VERSION "BASE;119 -- 04.07.2025 -- R3233 -- FDMgenDBC1.0"

NS_ :

BS_:

BU_: CM4

BO_ 2600460568 RTprop2_BASE: 8 CM4
 SG_ rmtTstrBattCurrentOTA_BASE : 0|8@1+ (0.2,0) [0|50] "A" Vector__XXX
 SG_ rmtTstrInstallProgressBar_BASE : 16|8@1+ (1,0) [0|250] "%" Vector__XXX
 SG_ rmtTstrDispCondC1gearNeut_BASE : 24|2@1+ (1,0) [0|0] "-" Vector__XXX
 SG_ rmtTstrDispCondC1VehSpd_BASE : 26|2@1+ (1,0) [0|0] "-" Vector__XXX
 SG_ rmtTstrDispCondC1ParkBrake_BASE : 28|2@1+ (1,0) [0|0] "-" Vector__XXX
 SG_ rmtTstrDispCondC1engSpd_BASE : 30|2@1+ (1,0) [0|0] "-" Vector__XXX
 SG_ rmtTstrDispCondIgnition_BASE : 32|2@1+ (1,0) [0|0] "-" Vector__XXX
 SG_ rmtTstrDispCondOBD_BASE : 34|2@1+ (1,0) [0|0] "-" Vector__XXX
 SG_ rmtTstrDispICLreset_BASE : 36|2@1+ (1,0) [0|0] "-" Vector__XXX
 SG_ rmtTstrDispUpdateAvail_BASE : 38|2@1+ (1,0) [0|0] "-" Vector__XXX
 SG_ rmtTstrInstallNumOfJobs_BASE : 40|8@1+ (1,0) [0|250] "-" Vector__XXX
 SG_ rmtTstrInstallTxtUpdToggle_BASE : 48|2@1+ (1,0) [0|1] "-" Vector__XXX
 SG_ rmtTstrDispCondEPTO_BASE : 50|2@1+ (1,0) [0|0] "-" Vector__XXX
 SG_ rmtTstrDispCond24VBattChrg_BASE : 52|2@1+ (1,0) [0|0] "-" Vector__XXX
 SG_ rmtTstrDispCondSecCerts_BASE : 54|2@1+ (1,0) [0|0] "-" Vector__XXX
 SG_ rmtTstrDispCondCurrent_BASE : 56|2@1+ (1,0) [0|0] "-" Vector__XXX
 SG_ rmtTstrDispAllowDriverExit_BASE : 58|2@1+ (1,0) [0|0] "-" Vector__XXX
 SG_ rmtTstrDispCondExtrnlChrg_BASE : 60|2@1+ (1,0) [0|0] "-" Vector__XXX
 SG_ rmtTstrOverrideCl15_BASE : 62|2@1+ (1,0) [0|0] "-" Vector__XXX
 SG_ rmtTstrInstallEstTotTime_VAR1 : 8|8@1+ (5,0) [0|1250] "min" Vector__XXX

BO_ 2566834939 DM1_CM4_SAE: 42 CM4
 SG_ protectLampStatus_CM4_SAE : 0|2@1+ (1,0) [0|0] "-" Vector__XXX
 SG_ flashAmberWarningLamp_CM4_SAE : 10|2@1+ (1,0) [0|0] "-" Vector__XXX
 SG_ SPN_high_reserved03_CM4_SAE : 101|3@1+ (1,0) [0|7] "-" Vector__XXX
 SG_ OcC_03_CM4_SAE : 104|7@1+ (1,0) [0|127] "-" Vector__XXX
 SG_ CM_03_CM4_SAE : 111|1@1+ (1,0) [0|1] "-" Vector__XXX
 SG_ SPN_04_CM4_SAE : 112|16@1+ (1,0) [0|65535] "-" Vector__XXX
 SG_ flashRedStopLamp_CM4_SAE : 12|2@1+ (1,0) [0|0] "-" Vector__XXX
 SG_ FMI_04_CM4_SAE : 128|5@1+ (1,0) [0|31] "-" Vector__XXX
 SG_ SPN_high_reserved04_CM4_SAE : 133|3@1+ (1,0) [0|7] "-" Vector__XXX
 SG_ OcC_04_CM4_SAE : 136|7@1+ (1,0) [0|127] "-" Vector__XXX
 SG_ flashMalFunctionalIndicatorLamp_ : 14|2@1+ (1,0) [0|0] "-" Vector__XXX
 SG_ CM_04_CM4_SAE : 143|1@1+ (1,0) [0|1] "-" Vector__XXX
 SG_ SPN_05_CM4_SAE : 144|16@1+ (1,0) [0|65535] "-" Vector__XXX
 SG_ SPN_01_CM4_SAE : 16|16@1+ (1,0) [0|65535] "-" Vector__XXX
 SG_ FMI_05_CM4_SAE : 160|5@1+ (1,0) [0|31] "-" Vector__XXX
 SG_ SPN_high_reserved05_CM4_SAE : 165|3@1+ (1,0) [0|7] "-" Vector__XXX
 SG_ OcC_05_CM4_SAE : 168|7@1+ (1,0) [0|127] "-" Vector__XXX
 SG_ CM_05_CM4_SAE : 175|1@1+ (1,0) [0|1] "-" Vector__XXX
 SG_ SPN_06_CM4_SAE : 176|16@1+ (1,0) [0|65535] "-" Vector__XXX
 SG_ FMI_06_CM4_SAE : 192|5@1+ (1,0) [0|31] "-" Vector__XXX
 SG_ SPN_high_reserved06_CM4_SAE : 197|3@1+ (1,0) [0|7] "-" Vector__XXX
 SG_ amberWarningLamp_CM4_SAE : 2|2@1+ (1,0) [0|0] "-" Vector__XXX
 SG_ OcC_06_CM4_SAE : 200|7@1+ (1,0) [0|127] "-" Vector__XXX
 SG_ CM_06_CM4_SAE : 207|1@1+ (1,0) [0|1] "-" Vector__XXX
 SG_ SPN_07_CM4_SAE : 208|16@1+ (1,0) [0|65535] "-" Vector__XXX
 SG_ FMI_07_CM4_SAE : 224|5@1+ (1,0) [0|31] "-" Vector__XXX
 SG_ SPN_high_reserved07_CM4_SAE : 229|3@1+ (1,0) [0|7] "-" Vector__XXX
 SG_ OcC_07_CM4_SAE : 232|7@1+ (1,0) [0|127] "-" Vector__XXX
 SG_ CM_07_CM4_SAE : 239|1@1+ (1,0) [0|1] "-" Vector__XXX
 SG_ SPN_08_CM4_SAE : 240|16@1+ (1,0) [0|65535] "-" Vector__XXX
 SG_ FMI_08_CM4_SAE : 256|5@1+ (1,0) [0|31] "-" Vector__XXX
 SG_ SPN_high_reserved08_CM4_SAE : 261|3@1+ (1,0) [0|7] "-" Vector__XXX
 SG_ OcC_08_CM4_SAE : 264|7@1+ (1,0) [0|127] "-" Vector__XXX
 SG_ CM_08_CM4_SAE : 271|1@1+ (1,0) [0|1] "-" Vector__XXX
 SG_ SPN_09_CM4_SAE : 272|16@1+ (1,0) [0|65535] "-" Vector__XXX
 SG_ FMI_09_CM4_SAE : 288|5@1+ (1,0) [0|31] "-" Vector__XXX
 SG_ SPN_high_reserved09_CM4_SAE : 293|3@1+ (1,0) [0|7] "-" Vector__XXX
 SG_ OcC_09_CM4_SAE : 296|7@1+ (1,0) [0|127] "-" Vector__XXX
 SG_ CM_09_CM4_SAE : 303|1@1+ (1,0) [0|1] "-" Vector__XXX
 SG_ SPN_10_CM4_SAE : 304|16@1+ (1,0) [0|65535] "-" Vector__XXX
 SG_ FMI_01_CM4_SAE : 32|5@1+ (1,0) [0|31] "-" Vector__XXX
 SG_ FMI_10_CM4_SAE : 320|5@1+ (1,0) [0|31] "-" Vector__XXX
 SG_ SPN_high_reserved10_CM4_SAE : 325|3@1+ (1,0) [0|7] "-" Vector__XXX
 SG_ OcC_10_CM4_SAE : 328|7@1+ (1,0) [0|127] "-" Vector__XXX
 SG_ CM_10_CM4_SAE : 335|1@1+ (1,0) [0|1] "-" Vector__XXX
 SG_ SPN_high_reserved01_CM4_SAE : 37|3@1+ (1,0) [0|7] "-" Vector__XXX
 SG_ redStopLamp_CM4_SAE : 4|2@1+ (1,0) [0|0] "-" Vector__XXX
 SG_ OcC_01_CM4_SAE : 40|7@1+ (1,0) [0|127] "-" Vector__XXX
 SG_ CM_01_CM4_SAE : 47|1@1+ (1,0) [0|1] "-" Vector__XXX
 SG_ SPN_02_CM4_SAE : 48|16@1+ (1,0) [0|65535] "-" Vector__XXX
 SG_ malfunctionIndicatorLamp_CM4_SAE : 6|2@1+ (1,0) [0|0] "-" Vector__XXX
 SG_ FMI_02_CM4_SAE : 64|5@1+ (1,0) [0|31] "-" Vector__XXX
 SG_ SPN_high_reserved02_CM4_SAE : 69|3@1+ (1,0) [0|7] "-" Vector__XXX
 SG_ OcC_02_CM4_SAE : 72|7@1+ (1,0) [0|127] "-" Vector__XXX
 SG_ CM_02_CM4_SAE : 79|1@1+ (1,0) [0|1] "-" Vector__XXX
 SG_ flashProtectLampStatus_CM4_SAE : 8|2@1+ (1,0) [0|0] "-" Vector__XXX
 SG_ SPN_03_CM4_SAE : 80|16@1+ (1,0) [0|65535] "-" Vector__XXX
 SG_ FMI_03_CM4_SAE : 96|5@1+ (1,0) [0|31] "-" Vector__XXX

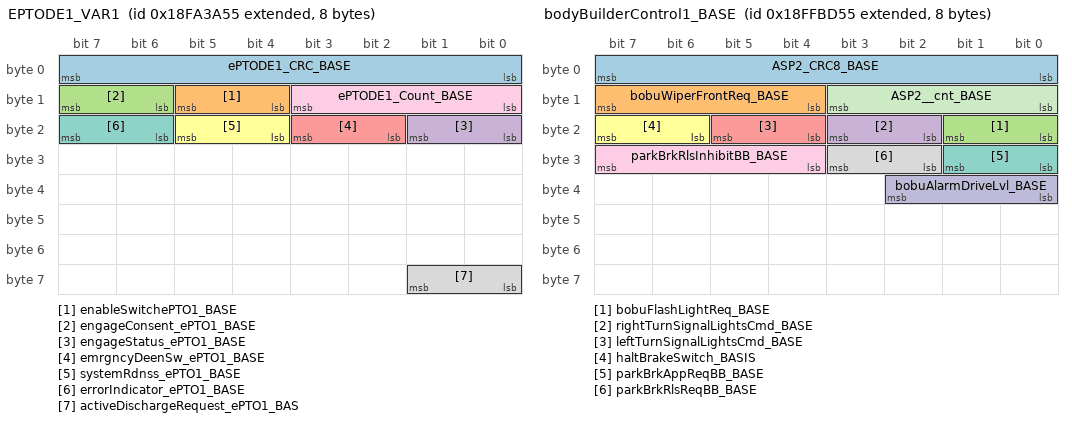
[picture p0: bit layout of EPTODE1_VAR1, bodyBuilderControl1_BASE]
BO_ 2566535765 EPTODE1_VAR1: 8 CM4
 SG_ ePTODE1_CRC_BASE : 0|8@1+ (1,0) [0|255] "count" Vector__XXX
 SG_ enableSwitchePTO1_BASE : 12|2@1+ (1,0) [0|0] "-" Vector__XXX
 SG_ engageConsent_ePTO1_BASE : 14|2@1+ (1,0) [0|0] "-" Vector__XXX
 SG_ engageStatus_ePTO1_BASE : 16|2@1+ (1,0) [0|0] "-" Vector__XXX
 SG_ emrgncyDeenSw_ePTO1_BASE : 18|2@1+ (1,0) [0|0] "-" Vector__XXX
 SG_ systemRdnss_ePTO1_BASE : 20|2@1+ (1,0) [0|0] "-" Vector__XXX
 SG_ errorIndicator_ePTO1_BASE : 22|2@1+ (1,0) [0|0] "-" Vector__XXX
 SG_ activeDischargeRequest_ePTO1_BAS : 56|2@1+ (1,0) [0|0] "-" Vector__XXX
 SG_ ePTODE1_Count_BASE : 8|4@1+ (1,0) [0|15] "-" Vector__XXX

BO_ 2566896981 bodyBuilderControl1_BASE: 8 CM4
 SG_ ASP2_CRC8_BASE : 0|8@1+ (1,0) [0|255] "-" Vector__XXX
 SG_ bobuWiperFrontReq_BASE : 12|4@1+ (1,0) [0|0] "-" Vector__XXX
 SG_ bobuFlashLightReq_BASE : 16|2@1+ (1,0) [0|0] "-" Vector__XXX
 SG_ rightTurnSignalLightsCmd_BASE : 18|2@1+ (1,0) [0|0] "-" Vector__XXX
 SG_ leftTurnSignalLightsCmd_BASE : 20|2@1+ (1,0) [0|0] "-" Vector__XXX
 SG_ haltBrakeSwitch_BASIS : 22|2@1+ (1,0) [0|0] "-" Vector__XXX
 SG_ parkBrkAppReqBB_BASE : 24|2@1+ (1,0) [0|0] "-" Vector__XXX
 SG_ parkBrkRlsReqBB_BASE : 26|2@1+ (1,0) [0|0] "-" Vector__XXX
 SG_ parkBrkRlsInhibitBB_BASE : 28|4@1+ (1,0) [0|0] "-" Vector__XXX
 SG_ bobuAlarmDriveLvl_BASE : 32|3@1+ (1,0) [0|0] "-" Vector__XXX
 SG_ ASP2__cnt_BASE : 8|4@1+ (1,0) [0|15] "-" Vector__XXX

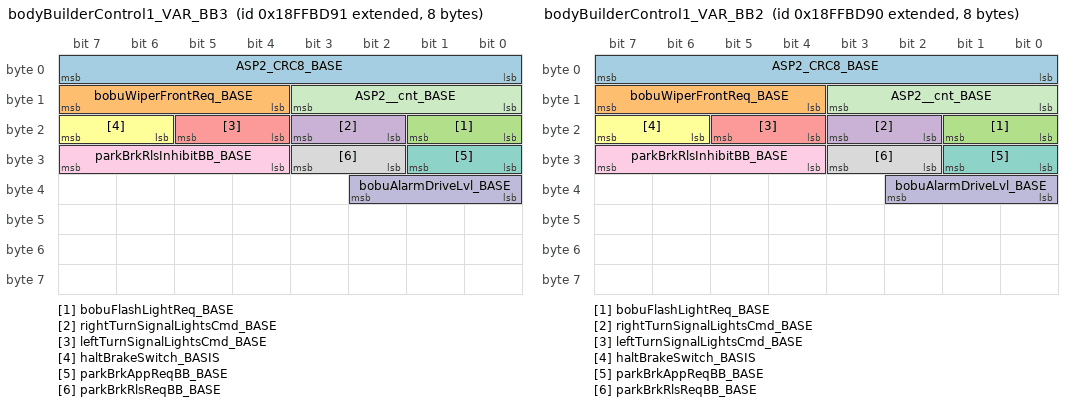
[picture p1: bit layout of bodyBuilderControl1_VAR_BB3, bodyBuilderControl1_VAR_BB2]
BO_ 2566897041 bodyBuilderControl1_VAR_BB3: 8 CM4
 SG_ ASP2_CRC8_BASE : 0|8@1+ (1,0) [0|255] "-" Vector__XXX
 SG_ bobuWiperFrontReq_BASE : 12|4@1+ (1,0) [0|0] "-" Vector__XXX
 SG_ bobuFlashLightReq_BASE : 16|2@1+ (1,0) [0|0] "-" Vector__XXX
 SG_ rightTurnSignalLightsCmd_BASE : 18|2@1+ (1,0) [0|0] "-" Vector__XXX
 SG_ leftTurnSignalLightsCmd_BASE : 20|2@1+ (1,0) [0|0] "-" Vector__XXX
 SG_ haltBrakeSwitch_BASIS : 22|2@1+ (1,0) [0|0] "-" Vector__XXX
 SG_ parkBrkAppReqBB_BASE : 24|2@1+ (1,0) [0|0] "-" Vector__XXX
 SG_ parkBrkRlsReqBB_BASE : 26|2@1+ (1,0) [0|0] "-" Vector__XXX
 SG_ parkBrkRlsInhibitBB_BASE : 28|4@1+ (1,0) [0|0] "-" Vector__XXX
 SG_ bobuAlarmDriveLvl_BASE : 32|3@1+ (1,0) [0|0] "-" Vector__XXX
 SG_ ASP2__cnt_BASE : 8|4@1+ (1,0) [0|15] "-" Vector__XXX

BO_ 2566897040 bodyBuilderControl1_VAR_BB2: 8 CM4
 SG_ ASP2_CRC8_BASE : 0|8@1+ (1,0) [0|255] "-" Vector__XXX
 SG_ bobuWiperFrontReq_BASE : 12|4@1+ (1,0) [0|0] "-" Vector__XXX
 SG_ bobuFlashLightReq_BASE : 16|2@1+ (1,0) [0|0] "-" Vector__XXX
 SG_ rightTurnSignalLightsCmd_BASE : 18|2@1+ (1,0) [0|0] "-" Vector__XXX
 SG_ leftTurnSignalLightsCmd_BASE : 20|2@1+ (1,0) [0|0] "-" Vector__XXX
 SG_ haltBrakeSwitch_BASIS : 22|2@1+ (1,0) [0|0] "-" Vector__XXX
 SG_ parkBrkAppReqBB_BASE : 24|2@1+ (1,0) [0|0] "-" Vector__XXX
 SG_ parkBrkRlsReqBB_BASE : 26|2@1+ (1,0) [0|0] "-" Vector__XXX
 SG_ parkBrkRlsInhibitBB_BASE : 28|4@1+ (1,0) [0|0] "-" Vector__XXX
 SG_ bobuAlarmDriveLvl_BASE : 32|3@1+ (1,0) [0|0] "-" Vector__XXX
 SG_ ASP2__cnt_BASE : 8|4@1+ (1,0) [0|15] "-" Vector__XXX

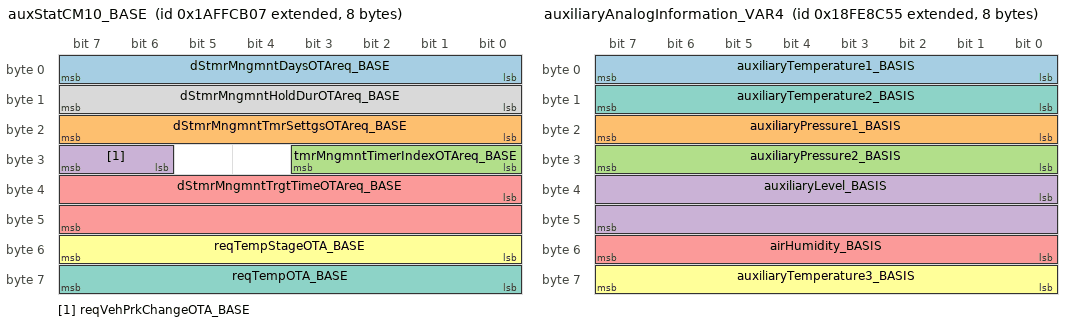
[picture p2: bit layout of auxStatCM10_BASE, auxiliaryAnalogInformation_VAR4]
BO_ 2600454919 auxStatCM10_BASE: 8 CM4
 SG_ dStmrMngmntDaysOTAreq_BASE : 0|8@1+ (1,0) [0|127] "-" Vector__XXX
 SG_ dStmrMngmntTmrSettgsOTAreq_BASE : 16|8@1+ (1,0) [0|127] "-" Vector__XXX
 SG_ tmrMngmntTimerIndexOTAreq_BASE : 24|4@1+ (1,0) [0|0] "-" Vector__XXX
 SG_ reqVehPrkChangeOTA_BASE : 30|2@1+ (1,0) [0|0] "-" Vector__XXX
 SG_ dStmrMngmntTrgtTimeOTAreq_BASE : 32|16@1+ (1,0) [0|64255] "min" Vector__XXX
 SG_ reqTempStageOTA_BASE : 48|8@1+ (1,1) [1|9] "-" Vector__XXX
 SG_ reqTempOTA_BASE : 56|8@1+ (0.5,0) [0|125] "°C" Vector__XXX
 SG_ dStmrMngmntHoldDurOTAreq_BASE : 8|8@1+ (15,0) [0|3750] "min" Vector__XXX

BO_ 2566818901 auxiliaryAnalogInformation_VAR4: 8 CM4
 SG_ auxiliaryTemperature1_BASIS : 0|8@1+ (1,-40) [-40|210] "°C" Vector__XXX
 SG_ auxiliaryPressure1_BASIS : 16|8@1+ (16,0) [0|4000] "kPa" Vector__XXX
 SG_ auxiliaryPressure2_BASIS : 24|8@1+ (16,0) [0|4000] "kPa" Vector__XXX
 SG_ auxiliaryLevel_BASIS : 32|16@1+ (0.1,0) [0|6425.5] "mm" Vector__XXX
 SG_ airHumidity_BASIS : 48|8@1+ (0.4,0) [0|100] "%" Vector__XXX
 SG_ auxiliaryTemperature3_BASIS : 56|8@1+ (1,-40) [-40|210] "°C" Vector__XXX
 SG_ auxiliaryTemperature2_BASIS : 8|8@1+ (1,-40) [-40|210] "°C" Vector__XXX

BO_ 2600454922 auxStatCM13_BASE: 8 CM4
 SG_ auxStatCM13placeholder_BASE : 0|8@1+ (1,0) [0|255] "-" Vector__XXX

BO_ 2566845696 ambientConditions_BASIS: 8 Vector__XXX
 SG_ barometricPressure_BASIS : 0|8@1+ (0.5,0) [0|125] "kPa" CM4
 SG_ ambientAirTemperature_BASIS : 24|16@1+ (0.03125,-273) [-273|1734.96875] "°C" CM4
 SG_ cabInteriorTemperature_BASIS : 8|16@1+ (0.03125,-273) [-273|1734.96875] "°C" CM4

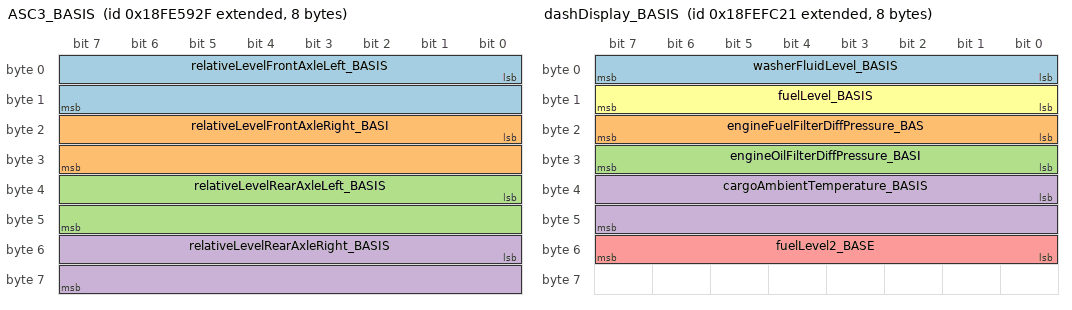
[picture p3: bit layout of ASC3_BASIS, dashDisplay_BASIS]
BO_ 2566805807 ASC3_BASIS: 8 Vector__XXX
 SG_ relativeLevelFrontAxleLeft_BASIS : 0|16@1+ (0.1,-3200) [-3200|3225.5] "mm" CM4
 SG_ relativeLevelFrontAxleRight_BASI : 16|16@1+ (0.1,-3200) [-3200|3225.5] "mm" CM4
 SG_ relativeLevelRearAxleLeft_BASIS : 32|16@1+ (0.1,-3200) [-3200|3225.5] "mm" CM4
 SG_ relativeLevelRearAxleRight_BASIS : 48|16@1+ (0.1,-3200) [-3200|3225.5] "mm" CM4

BO_ 2566838781 auxStatKSM1_BASIS: 8 Vector__XXX
 SG_ Kuehlwassertemperaturwarnung_BAS : 0|2@1+ (1,0) [0|0] "-" CM4
 SG_ Oeldruckwarnung_BASIS : 2|2@1+ (1,0) [0|0] "-" CM4

BO_ 2563833623 cabIllumination_BASIS: 8 Vector__XXX
 SG_ illuminationBrightness_BASIS : 0|8@1+ (0.4,0) [0|100] "%" CM4

BO_ 2566843687 cruiseControlVehicleSpeedSetup_V: 8 Vector__XXX
 SG_ maximumVehicleSpeedLimit_BASIS : 0|8@1+ (1,0) [0|250] "km/h" CM4
 SG_ CClowSetLimitSpeed_BASIS : 16|8@1+ (1,0) [0|250] "km/h" CM4
 SG_ CChighSetLimitSpeed_BASIS : 8|8@1+ (1,0) [0|250] "km/h" CM4

BO_ 2566847521 dashDisplay_BASIS: 8 Vector__XXX
 SG_ washerFluidLevel_BASIS : 0|8@1+ (0.4,0) [0|100] "%" CM4
 SG_ engineFuelFilterDiffPressure_BAS : 16|8@1+ (2,0) [0|500] "kPa" CM4
 SG_ engineOilFilterDiffPressure_BASI : 24|8@1+ (0.5,0) [0|125] "kPa" CM4
 SG_ cargoAmbientTemperature_BASIS : 32|16@1+ (0.03125,-273) [-273|1735] "°C" CM4
 SG_ fuelLevel2_BASE : 48|8@1+ (0.4,0) [0|100] "%" CM4
 SG_ fuelLevel_BASIS : 8|8@1+ (0.4,0) [0|100] "%" CM4

BO_ 2566759916 doorControl2_BASIS: 8 Vector__XXX
 SG_ lockStatusOfDoor1_BASIS : 0|2@1+ (1,0) [0|0] "-" CM4
 SG_ enableStatusOfDoor2_BASIS : 10|2@1+ (1,0) [0|0] "-" CM4
 SG_ lockStatusOfDoor3_BASIS : 12|2@1+ (1,0) [0|0] "-" CM4
 SG_ openStatusOfDoor3_BASIS : 14|2@1+ (1,0) [0|0] "-" CM4
 SG_ enableStatusOfDoor3_BASIS : 16|2@1+ (1,0) [0|0] "-" CM4
 SG_ lockStatusOfDoor4_BASIS : 18|2@1+ (1,0) [0|0] "-" CM4
 SG_ openStatusOfDoor1_BASIS : 2|2@1+ (1,0) [0|0] "-" CM4
 SG_ openStatusOfDoor4_BASIS : 20|2@1+ (1,0) [0|0] "-" CM4
 SG_ enableStatusOfDoor4_BASIS : 22|2@1+ (1,0) [0|0] "-" CM4
 SG_ lockStatusOfDoor5_BASIS : 24|2@1+ (1,0) [0|0] "-" CM4
 SG_ openStatusOfDoor5_BASIS : 26|2@1+ (1,0) [0|0] "-" CM4
 SG_ enableStatusOfDoor5_BASIS : 28|2@1+ (1,0) [0|0] "-" CM4
 SG_ lockStatusOfDoor6_BASIS : 30|2@1+ (1,0) [0|0] "-" CM4
 SG_ openStatusOfDoor6_BASIS : 32|2@1+ (1,0) [0|0] "-" CM4
 SG_ enableStatusOfDoor6_BASIS : 34|2@1+ (1,0) [0|0] "-" CM4
 SG_ lockStatusOfDoor7_BASIS : 36|2@1+ (1,0) [0|0] "-" CM4
 SG_ openStatusOfDoor7_BASIS : 38|2@1+ (1,0) [0|0] "-" CM4
 SG_ enableStatusOfDoor1_BASIS : 4|2@1+ (1,0) [0|0] "-" CM4
 SG_ enableStatusOfDoor7_BASIS : 40|2@1+ (1,0) [0|0] "-" CM4
 SG_ lockStatusOfDoor8_BASIS : 42|2@1+ (1,0) [0|0] "-" CM4
 SG_ openStatusOfDoor8_BASIS : 44|2@1+ (1,0) [0|0] "-" CM4
 SG_ enableStatusOfDoor8_BASIS : 46|2@1+ (1,0) [0|0] "-" CM4
 SG_ lockStatusOfDoor9_BASIS : 48|2@1+ (1,0) [0|0] "-" CM4
 SG_ openStatusOfDoor9_BASIS : 50|2@1+ (1,0) [0|0] "-" CM4
 SG_ enableStatusOfDoor9_BASIS : 52|2@1+ (1,0) [0|0] "-" CM4
 SG_ lockStatusOfDoor10_BASIS : 54|2@1+ (1,0) [0|0] "-" CM4
 SG_ openStatusOfDoor10_BASIS : 56|2@1+ (1,0) [0|0] "-" CM4
 SG_ enableStatusOfDoor10_BASIS : 58|2@1+ (1,0) [0|0] "-" CM4
 SG_ lockStatusOfDoor2_BASIS : 6|2@1+ (1,0) [0|0] "-" CM4
 SG_ openStatusOfDoor2_BASIS : 8|2@1+ (1,0) [0|0] "-" CM4

BO_ 2566810606 driversIdentification_VAR3: 40 Vector__XXX
 SG_ driverIdentification_BASE : 0|320@1+ (1,0) [0|0] "-" CM4

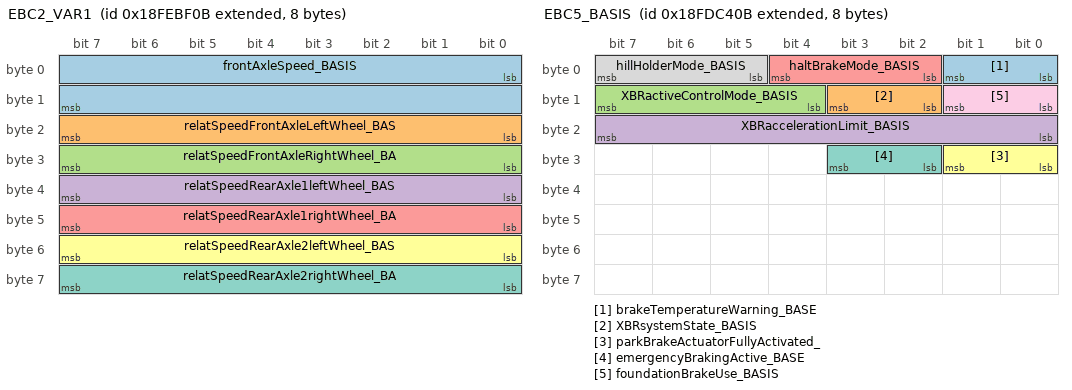
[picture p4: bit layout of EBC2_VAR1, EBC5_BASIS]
BO_ 2566831883 EBC2_VAR1: 8 Vector__XXX
 SG_ frontAxleSpeed_BASIS : 0|16@1+ (0.00390625,0) [0|250.996] "km/h" CM4
 SG_ relatSpeedFrontAxleLeftWheel_BAS : 16|8@1+ (0.0625,-7.8125) [-7.8125|7.8125] "km/h" CM4
 SG_ relatSpeedFrontAxleRightWheel_BA : 24|8@1+ (0.0625,-7.8125) [-7.8125|7.8125] "km/h" CM4
 SG_ relatSpeedRearAxle1leftWheel_BAS : 32|8@1+ (0.0625,-7.8125) [-7.8125|7.8125] "km/h" CM4
 SG_ relatSpeedRearAxle1rightWheel_BA : 40|8@1+ (0.0625,-7.8125) [-7.8125|7.8125] "km/h" CM4
 SG_ relatSpeedRearAxle2leftWheel_BAS : 48|8@1+ (0.0625,-7.8125) [-7.8125|7.8125] "km/h" CM4
 SG_ relatSpeedRearAxle2rightWheel_BA : 56|8@1+ (0.0625,-7.8125) [-7.8125|7.8125] "km/h" CM4

BO_ 2566767627 EBC5_BASIS: 8 Vector__XXX
 SG_ brakeTemperatureWarning_BASE : 0|2@1+ (1,0) [0|0] "-" CM4
 SG_ XBRsystemState_BASIS : 10|2@1+ (1,0) [0|0] "-" CM4
 SG_ XBRactiveControlMode_BASIS : 12|4@1+ (1,0) [0|0] "-" CM4
 SG_ XBRaccelerationLimit_BASIS : 16|8@1+ (0.1,-12.5) [-12.5|12.5] "m/s²" CM4
 SG_ haltBrakeMode_BASIS : 2|3@1+ (1,0) [0|0] "-" CM4
 SG_ parkBrakeActuatorFullyActivated_ : 24|2@1+ (1,0) [0|0] "-" CM4
 SG_ emergencyBrakingActive_BASE : 26|2@1+ (1,0) [0|0] "-" CM4
 SG_ hillHolderMode_BASIS : 5|3@1+ (1,0) [0|0] "-" CM4
 SG_ foundationBrakeUse_BASIS : 8|2@1+ (1,0) [0|0] "-" CM4

BO_ 2566833352 EBS22_T1_TO_TRUCK: 8 Vector__XXX
 SG_ vehicleABSactivePassive_T1_TO_TR : 0|2@1+ (1,0) [0|0] "-" CM4
 SG_ redWarningSignalRequest_T1_TO_TR : 10|2@1+ (1,0) [0|0] "-" CM4
 SG_ amberWarningSignalRequest_T1_TO_ : 12|2@1+ (1,0) [0|0] "-" CM4
 SG_ electricalSupplyOfNonBrakingSyst : 14|2@1+ (1,0) [0|0] "-" CM4
 SG_ springBrakeInstalled_T1_TO_TRUCK : 16|2@1+ (1,0) [0|0] "-" CM4
 SG_ electrLoadProportionalFunc_T1_TO : 18|2@1+ (1,0) [0|0] "-" CM4
 SG_ vehicleRetContrActivePassive_T1_ : 2|2@1+ (1,0) [0|0] "-" CM4
 SG_ vehicleType_T1_TO_TRUCK_EBS22 : 20|2@1+ (1,0) [0|0] "-" CM4
 SG_ springBrakeEngaged_T1_TO_TRUCK : 22|2@1+ (1,0) [0|0] "-" CM4
 SG_ loadingRampApproachAssistance_T1 : 24|2@1+ (1,0) [0|0] "-" CM4
 SG_ supplylineBrakingRequest_T1_TO_T : 26|2@1+ (1,0) [0|0] "-" CM4
 SG_ stopLampsRequest_BASE : 28|2@1+ (1,0) [0|0] "-" CM4
 SG_ electricCtrlLineBrkngSuprt_BASE : 30|2@1+ (1,0) [0|0] "-" CM4
 SG_ axleLoadSum_T1_TO_TRUCK : 32|16@1+ (2,0) [0|128510] "kg" CM4
 SG_ vehicleServiceBrakeActPass_T1_TO : 4|2@1+ (1,0) [0|0] "-" CM4
 SG_ referenceRetarderTorque_T1_TO_TR : 48|16@1+ (1,0) [0|64255] "Nm" CM4
 SG_ automaticTowedVehicleBrake_T1_TO : 6|2@1+ (1,0) [0|0] "-" CM4
 SG_ vehicleElectricalSupply_T1_TO_TR : 8|2@1+ (1,0) [0|0] "-" CM4

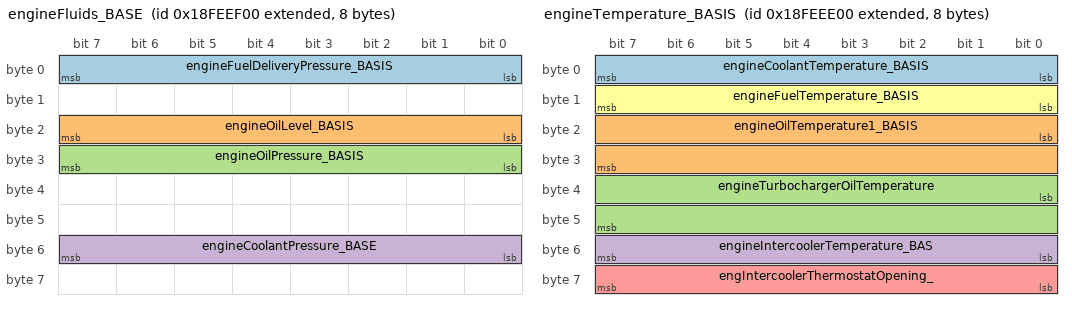
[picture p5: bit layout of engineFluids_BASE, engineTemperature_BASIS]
BO_ 2566844160 engineFluids_BASE: 8 Vector__XXX
 SG_ engineFuelDeliveryPressure_BASIS : 0|8@1+ (4,0) [0|1000] "kPa" CM4
 SG_ engineOilLevel_BASIS : 16|8@1+ (0.4,0) [0|100] "%" CM4
 SG_ engineOilPressure_BASIS : 24|8@1+ (4,0) [0|1000] "kPa" CM4
 SG_ engineCoolantPressure_BASE : 48|8@1+ (2,0) [0|500] "kPa" CM4

BO_ 2566841639 engineHoursRevolutions_VAR1: 8 Vector__XXX
 SG_ engineTotalHoursOfOperation_BASI : 0|32@1+ (0.05,0) [0|210554060.75] "h" CM4
 SG_ engineTotalRevolutions_BASIS : 32|32@1+ (1000,0) [0|4211081215000] "r" CM4

BO_ 2566843904 engineTemperature_BASIS: 8 Vector__XXX
 SG_ engineCoolantTemperature_BASIS : 0|8@1+ (1,-40) [-40|210] "°C" CM4
 SG_ engineOilTemperature1_BASIS : 16|16@1+ (0.03125,-273) [-273|1734.96875] "°C" CM4
 SG_ engineTurbochargerOilTemperature : 32|16@1+ (0.03125,-273) [-273|1734.96875] "°C" CM4
 SG_ engineIntercoolerTemperature_BAS : 48|8@1+ (1,-40) [-40|210] "°C" CM4
 SG_ engIntercoolerThermostatOpening_ : 56|8@1+ (0.4,0) [0|100] "%" CM4
 SG_ engineFuelTemperature_BASIS : 8|8@1+ (1,-40) [-40|210] "°C" CM4

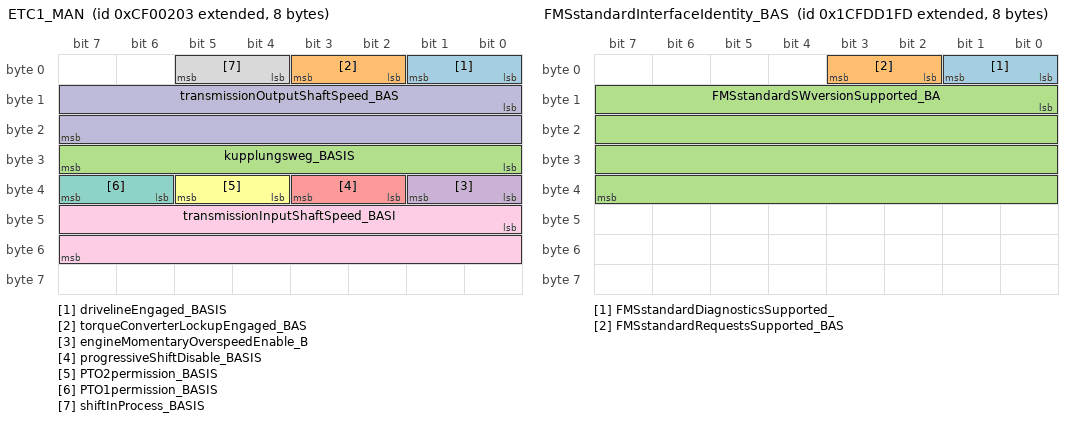
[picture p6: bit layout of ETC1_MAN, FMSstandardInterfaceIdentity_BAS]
BO_ 2364539395 ETC1_MAN: 8 Vector__XXX
 SG_ drivelineEngaged_BASIS : 0|2@1+ (1,0) [0|0] "-" CM4
 SG_ torqueConverterLockupEngaged_BAS : 2|2@1+ (1,0) [0|0] "-" CM4
 SG_ kupplungsweg_BASIS : 24|8@1+ (0.4,0) [0|100] "%" CM4
 SG_ engineMomentaryOverspeedEnable_B : 32|2@1+ (1,0) [0|0] "-" CM4
 SG_ progressiveShiftDisable_BASIS : 34|2@1+ (1,0) [0|0] "-" CM4
 SG_ PTO2permission_BASIS : 36|2@1+ (1,0) [0|0] "-" CM4
 SG_ PTO1permission_BASIS : 38|2@1+ (1,0) [0|0] "-" CM4
 SG_ shiftInProcess_BASIS : 4|2@1+ (1,0) [0|0] "-" CM4
 SG_ transmissionInputShaftSpeed_BASI : 40|16@1+ (0.125,0) [0|8031.875] "rpm" CM4
 SG_ transmissionOutputShaftSpeed_BAS : 8|16@1+ (0.125,0) [0|8031.875] "rpm" CM4

BO_ 2633880061 FMSstandardInterfaceIdentity_BAS: 8 Vector__XXX
 SG_ FMSstandardDiagnosticsSupported_ : 0|2@1+ (1,0) [0|0] "-" CM4
 SG_ FMSstandardRequestsSupported_BAS : 2|2@1+ (1,0) [0|0] "-" CM4
 SG_ FMSstandardSWversionSupported_BA : 8|32@1+ (1,0) [0|255] "-" CM4

BO_ 2566842663 fuelConsumption_VAR3: 8 Vector__XXX
 SG_ engineTripFuel_BASIS : 0|32@1+ (0.5,0) [0|2105540607.5] "l" CM4
 SG_ engineTotalFuelUsed_BASIS : 32|32@1+ (0.5,0) [0|2105540607.5] "l" CM4

BO_ 2566719744 highResolutionFuelConsumption_BA: 8 Vector__XXX
 SG_ highResolutionEngineTripFuel_BAS : 0|32@1+ (0.001,0) [0|4211081.2149999998509883881] "l" CM4
 SG_ HRengineTotalFuelUsed_BASE : 32|32@1+ (0.001,0) [0|4211081.2149999998509883881] "l" CM4

BO_ 2566844967 fuelEconomy_BASIS: 8 Vector__XXX
 SG_ engineFuelRate_BASIS : 0|16@1+ (0.05,0) [0|3212.75] "l/h" CM4
 SG_ engineInstantaneousFuelEconomy_B : 16|16@1+ (0.001953,0) [0|125.490015] "km/l" CM4
 SG_ engineAverageFuelEconomy_BASIS : 32|16@1+ (0.001953,0) [0|125.490015] "km/l" CM4

BO_ 2365443111 operatorsExtLightControlsMessage: 8 Vector__XXX
 SG_ turnSignalSwitch_BASE : 8|4@1+ (1,0) [0|0] "-" CM4

BO_ 2566805053 tankInformation1_BASIS: 8 Vector__XXX
 SG_ catalystTankLevel_BASIS : 0|8@1+ (0.4,0) [0|100] "%" CM4
 SG_ temperatureReagentInTank_BASIS : 8|8@1+ (1,-40) [-40|210] "°C" CM4

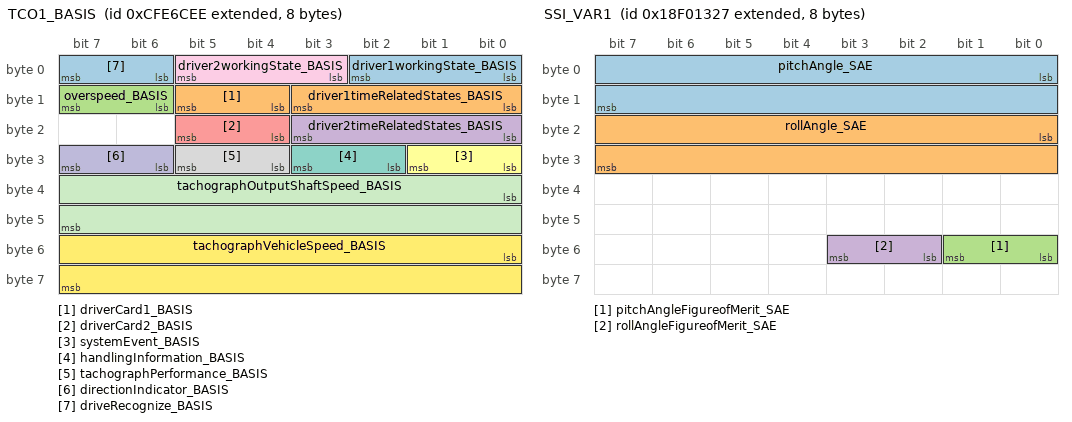
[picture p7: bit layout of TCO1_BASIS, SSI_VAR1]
BO_ 2365484270 TCO1_BASIS: 8 Vector__XXX
 SG_ driver1workingState_BASIS : 0|3@1+ (1,0) [0|0] "-" CM4
 SG_ driverCard1_BASIS : 12|2@1+ (1,0) [0|0] "-" CM4
 SG_ overspeed_BASIS : 14|2@1+ (1,0) [0|0] "-" CM4
 SG_ driver2timeRelatedStates_BASIS : 16|4@1+ (1,0) [0|0] "-" CM4
 SG_ driverCard2_BASIS : 20|2@1+ (1,0) [0|0] "-" CM4
 SG_ systemEvent_BASIS : 24|2@1+ (1,0) [0|0] "-" CM4
 SG_ handlingInformation_BASIS : 26|2@1+ (1,0) [0|0] "-" CM4
 SG_ tachographPerformance_BASIS : 28|2@1+ (1,0) [0|0] "-" CM4
 SG_ driver2workingState_BASIS : 3|3@1+ (1,0) [0|0] "-" CM4
 SG_ directionIndicator_BASIS : 30|2@1+ (1,0) [0|0] "-" CM4
 SG_ tachographOutputShaftSpeed_BASIS : 32|16@1+ (0.125,0) [0|8031.875] "rpm" CM4
 SG_ tachographVehicleSpeed_BASIS : 48|16@1+ (0.00390625,0) [0|250.996] "km/h" CM4
 SG_ driveRecognize_BASIS : 6|2@1+ (1,0) [0|0] "-" CM4
 SG_ driver1timeRelatedStates_BASIS : 8|4@1+ (1,0) [0|0] "-" CM4

BO_ 2566802471 militaryLightingCommand_BASE: 8 Vector__XXX
 SG_ OprtrsBlackOutIntnstySel_BASE : 56|8@1+ (0.4,0) [0|100] "%" CM4

BO_ 2566806728 RGE22_T1_TO_TRUCK: 8 Vector__XXX
 SG_ tyreWheelIdentification_BASIS : 32|8@1+ (1,0) [0|0] "-" CM4
 SG_ axleLoad_BASE : 40|16@1+ (0.5,0) [0|32127.5] "kg" CM4

BO_ 2565870375 SSI_VAR1: 8 Vector__XXX
 SG_ pitchAngle_SAE : 0|16@1+ (0.002,-64) [-64|64.51] "°" CM4
 SG_ rollAngle_SAE : 16|16@1+ (0.002,-64) [-64|64.51] "°" CM4
 SG_ pitchAngleFigureofMerit_SAE : 48|2@1+ (1,0) [0|0] "-" CM4
 SG_ rollAngleFigureofMerit_SAE : 50|2@1+ (1,0) [0|0] "-" CM4

BO_ 2566846467 transmissionFluids_TCU: 8 Vector__XXX
 SG_ transmissionOilTemperature_TCU : 32|16@1+ (0.03125,-273) [-273|1735] "°C" CM4
 SG_ transmissionOilLevel_TCU : 8|8@1+ (0.4,0) [0|100] "%" CM4

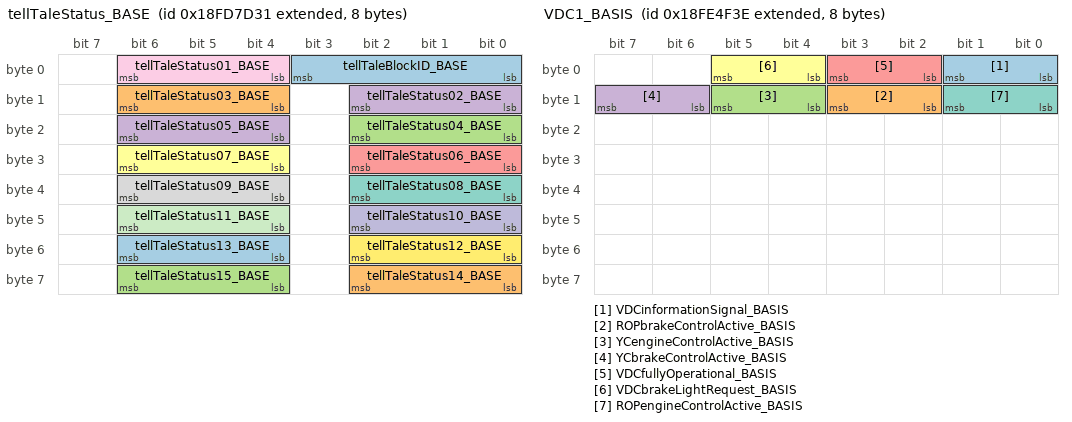
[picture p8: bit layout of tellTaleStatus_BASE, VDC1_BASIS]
BO_ 2566749489 tellTaleStatus_BASE: 8 Vector__XXX
 SG_ tellTaleBlockID_BASE : 0|4@1+ (1,0) [0|15] "-" CM4
 SG_ tellTaleStatus03_BASE : 12|3@1+ (1,0) [0|0] "-" CM4
 SG_ tellTaleStatus04_BASE : 16|3@1+ (1,0) [0|0] "-" CM4
 SG_ tellTaleStatus05_BASE : 20|3@1+ (1,0) [0|0] "-" CM4
 SG_ tellTaleStatus06_BASE : 24|3@1+ (1,0) [0|0] "-" CM4
 SG_ tellTaleStatus07_BASE : 28|3@1+ (1,0) [0|0] "-" CM4
 SG_ tellTaleStatus08_BASE : 32|3@1+ (1,0) [0|0] "-" CM4
 SG_ tellTaleStatus09_BASE : 36|3@1+ (1,0) [0|0] "-" CM4
 SG_ tellTaleStatus01_BASE : 4|3@1+ (1,0) [0|0] "-" CM4
 SG_ tellTaleStatus10_BASE : 40|3@1+ (1,0) [0|0] "-" CM4
 SG_ tellTaleStatus11_BASE : 44|3@1+ (1,0) [0|0] "-" CM4
 SG_ tellTaleStatus12_BASE : 48|3@1+ (1,0) [0|0] "-" CM4
 SG_ tellTaleStatus13_BASE : 52|3@1+ (1,0) [0|0] "-" CM4
 SG_ tellTaleStatus14_BASE : 56|3@1+ (1,0) [0|0] "-" CM4
 SG_ tellTaleStatus15_BASE : 60|3@1+ (1,0) [0|0] "-" CM4
 SG_ tellTaleStatus02_BASE : 8|3@1+ (1,0) [0|0] "-" CM4

BO_ 2566803262 VDC1_BASIS: 8 Vector__XXX
 SG_ VDCinformationSignal_BASIS : 0|2@1+ (1,0) [0|0] "-" CM4
 SG_ ROPbrakeControlActive_BASIS : 10|2@1+ (1,0) [0|0] "-" CM4
 SG_ YCengineControlActive_BASIS : 12|2@1+ (1,0) [0|0] "-" CM4
 SG_ YCbrakeControlActive_BASIS : 14|2@1+ (1,0) [0|0] "-" CM4
 SG_ VDCfullyOperational_BASIS : 2|2@1+ (1,0) [0|0] "-" CM4
 SG_ VDCbrakeLightRequest_BASIS : 4|2@1+ (1,0) [0|0] "-" CM4
 SG_ ROPengineControlActive_BASIS : 8|2@1+ (1,0) [0|0] "-" CM4

BO_ 2566613799 HVBI_BASE: 8 Vector__XXX
 SG_ highVtgBusEPTOAvlblty_BASE : 12|4@1+ (1,0) [0|0] "-" CM4

BO_ 2365346087 ASC7_BASE: 8 Vector__XXX
 SG_ liftAxle1Status_BASE : 0|3@1+ (1,0) [0|0] "-" CM4

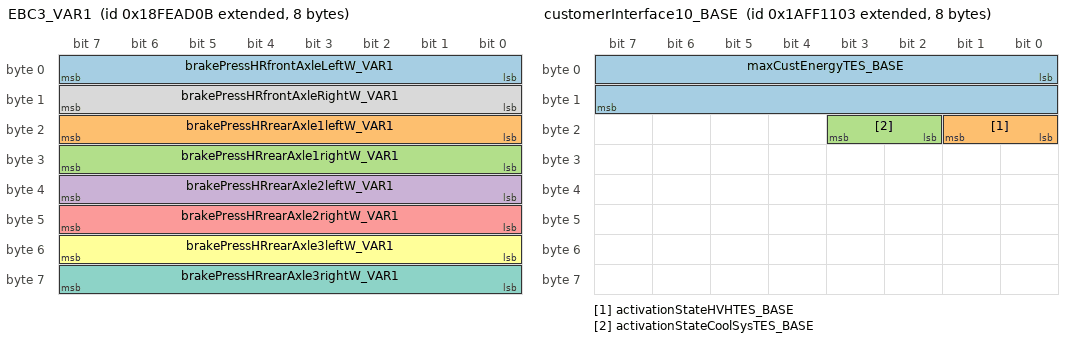
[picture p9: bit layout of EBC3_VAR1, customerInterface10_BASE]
BO_ 2566827275 EBC3_VAR1: 8 Vector__XXX
 SG_ brakePressHRfrontAxleLeftW_VAR1 : 0|8@1+ (5,0) [0|1250] "kPa" CM4
 SG_ brakePressHRrearAxle1leftW_VAR1 : 16|8@1+ (5,0) [0|1250] "kPa" CM4
 SG_ brakePressHRrearAxle1rightW_VAR1 : 24|8@1+ (5,0) [0|1250] "kPa" CM4
 SG_ brakePressHRrearAxle2leftW_VAR1 : 32|8@1+ (5,0) [0|1250] "kPa" CM4
 SG_ brakePressHRrearAxle2rightW_VAR1 : 40|8@1+ (5,0) [0|1250] "kPa" CM4
 SG_ brakePressHRrearAxle3leftW_VAR1 : 48|8@1+ (5,0) [0|1250] "kPa" CM4
 SG_ brakePressHRrearAxle3rightW_VAR1 : 56|8@1+ (5,0) [0|1250] "kPa" CM4
 SG_ brakePressHRfrontAxleRightW_VAR1 : 8|8@1+ (5,0) [0|1250] "kPa" CM4

BO_ 2566767143 EEC14_BASE: 8 Vector__XXX
 SG_ fuelType_BASE : 48|8@1+ (1,0) [0|0] "-" CM4

BO_ 2364641930 HVESP1D2_BASE: 8 Vector__XXX
 SG_ HVESP1fastUpdateSOC_BASE : 0|16@1+ (0.0015625,0) [0|100.3984375] "%" CM4
 SG_ HVESP1HighestCellVoltage_BASE : 16|16@1+ (0.001,0) [0|64.255] "V" CM4
 SG_ HVESP1lowestCellVoltage_BASE : 32|16@1+ (0.001,0) [0|64.255] "V" CM4

BO_ 2364645770 HVESP2D2_BASE: 8 Vector__XXX
 SG_ HVESP2fastUpdateSOC_BASE : 0|16@1+ (0.0015625,0) [0|100.3984375] "%" CM4
 SG_ HVESP2HighestCellVoltage_BASE : 16|16@1+ (0.001,0) [0|64.255] "V" CM4
 SG_ HVESP2lowestCellVoltage_BASE : 32|16@1+ (0.001,0) [0|64.255] "V" CM4

BO_ 2364649610 HVESP3D2_BASE: 8 Vector__XXX
 SG_ HVESP3fastUpdateSOC_BASE : 0|16@1+ (0.0015625,0) [0|100.3984375] "%" CM4
 SG_ HVESP3HighestCellVoltage_BASE : 16|16@1+ (0.001,0) [0|64.255] "V" CM4
 SG_ HVESP3lowestCellVoltage_BASE : 32|16@1+ (0.001,0) [0|64.255] "V" CM4

BO_ 2364657290 HVESP5D2_BASE: 8 Vector__XXX
 SG_ HVESP5fastUpdateSOC_BASE : 0|16@1+ (0.0015625,0) [0|100.3984375] "%" CM4
 SG_ HVESP5HighestCellVoltage_BASE : 16|16@1+ (0.001,0) [0|64.255] "V" CM4
 SG_ HVESP5lowestCellVoltage_BASE : 32|16@1+ (0.001,0) [0|64.255] "V" CM4

BO_ 2364675722 HVESP7D2_BASE: 8 Vector__XXX
 SG_ HVESP7fastUpdateSOC_BASE : 0|16@1+ (0.0015625,0) [0|100.3984375] "%" CM4
 SG_ HVESP7HighestCellVoltage_BASE : 16|16@1+ (0.001,0) [0|64.255] "V" CM4
 SG_ HVESP7lowestCellVoltage_BASE : 32|16@1+ (0.001,0) [0|64.255] "V" CM4

BO_ 2364653450 HVESP4D2_BASE: 8 Vector__XXX
 SG_ HVESP4fastUpdateSOC_BASE : 0|16@1+ (0.0015625,0) [0|100.3984375] "%" CM4
 SG_ HVESP4HighestCellVoltage_BASE : 16|16@1+ (0.001,0) [0|64.255] "V" CM4
 SG_ HVESP4lowestCellVoltage_BASE : 32|16@1+ (0.001,0) [0|64.255] "V" CM4

BO_ 2364679562 HVESP8D2_BASE: 8 Vector__XXX
 SG_ HVESP8fastUpdateSOC_BASE : 0|16@1+ (0.0015625,0) [0|100.3984375] "%" CM4
 SG_ HVESP8HighestCellVoltage_BASE : 16|16@1+ (0.001,0) [0|64.255] "V" CM4
 SG_ HVESP8lowestCellVoltage_BASE : 32|16@1+ (0.001,0) [0|64.255] "V" CM4

BO_ 2364661130 HVESP6D2_BASE: 8 Vector__XXX
 SG_ HVESP6fastUpdateSOC_BASE : 0|16@1+ (0.0015625,0) [0|100.3984375] "%" CM4
 SG_ HVESP6HighestCellVoltage_BASE : 16|16@1+ (0.001,0) [0|64.255] "V" CM4
 SG_ HVESP6lowestCellVoltage_BASE : 32|16@1+ (0.001,0) [0|64.255] "V" CM4

BO_ 2566840592 retarderConfiguration_RD: 19 Vector__XXX
 SG_ retarderType_RD : 0|4@1+ (1,0) [0|0] "-" CM4
 SG_ percentTorqueAtPoint4_RD : 104|8@1+ (1,-125) [-125|125] "%" CM4
 SG_ retarderSpeedAtPeakTorqPoint5_RD : 112|16@1+ (0.125,0) [0|8031.875] "rpm" CM4
 SG_ referenceRetarderTorque_RD : 128|16@1+ (1,0) [0|64255] "Nm" CM4
 SG_ percentTorqAtPeakTorqPoint5_RD : 144|8@1+ (1,-125) [-125|125] "%" CM4
 SG_ retarderSpeedAtIdlePoint1_RD : 16|16@1+ (0.125,0) [0|8031.875] "rpm" CM4
 SG_ percentTorqueAtIdlePoint1_RD : 32|8@1+ (1,-125) [-125|125] "%" CM4
 SG_ retarderLocation_RD : 4|4@1+ (1,0) [0|0] "-" CM4
 SG_ maximumRetarderSpeedPoint2_RD : 40|16@1+ (0.125,0) [0|8031.875] "rpm" CM4
 SG_ percentTorqueAtMaxSpeedPoint2_RD : 56|8@1+ (1,-125) [-125|125] "%" CM4
 SG_ retarderSpeedAtPoint3_RD : 64|16@1+ (0.125,0) [0|8031.875] "rpm" CM4
 SG_ retarderControlMethod_RD : 8|8@1+ (1,0) [0|250] "step" CM4
 SG_ percentTorqueAtPoint3_RD : 80|8@1+ (1,-125) [-125|125] "%" CM4
 SG_ retarderSpeedAtPoint4_RD : 88|16@1+ (0.125,0) [0|8031.875] "rpm" CM4

BO_ 2566847248 retarderFluids_RD: 8 Vector__XXX
 SG_ drivelineRetOverheatIndicator_RD : 16|2@1+ (1,0) [0|0] "-" CM4
 SG_ hydraulicOilTemperature_RD : 8|8@1+ (1,-40) [-40|210] "°C" CM4

BO_ 2566698791 VEP4_BASE: 8 Vector__XXX
 SG_ hybridBatPackRemCharge_BASE : 0|16@1+ (0.0025,0) [0|160.6375] "%" CM4

BO_ 2566545546 EVDCCIP_BASE: 8 Vector__XXX
 SG_ EVfullChargeTimeRemaining_BASE : 32|16@1+ (10,0) [0|642550] "s" CM4

BO_ 2600407299 customerInterface10_BASE: 8 Vector__XXX
 SG_ maxCustEnergyTES_BASE : 0|16@1+ (0.05,0) [0|3212.75] "kWh" CM4
 SG_ activationStateHVHTES_BASE : 16|2@1+ (1,0) [0|0] "-" CM4
 SG_ activationStateCoolSysTES_BASE : 18|2@1+ (1,0) [0|0] "-" CM4

BO_ 2600407300 customerInterface11_BASE: 8 Vector__XXX
 SG_ totalEnergyConsumption_BASE : 0|32@1+ (1,0) [0|4211081215] "kWh" CM4
 SG_ HVESSintakeCoolantTemp_BASE : 32|8@1+ (1,-40) [-40|210] "°C" CM4
 SG_ drvSysActv_BASE : 40|2@1+ (1,0) [0|0] "-" CM4

BO_ 2600407297 customerInterface8_BASE: 8 Vector__XXX
 SG_ HVESSstateOfHealth_BASE : 0|8@1+ (0.4,0) [0|100] "%" CM4
 SG_ HVESSmaxPackSOC_BASE : 24|16@1+ (0.0015625,0) [0|100.3984375] "%" CM4
 SG_ HVESSminPackSOC_BASE : 8|16@1+ (0.0015625,0) [0|100.3984375] "%" CM4

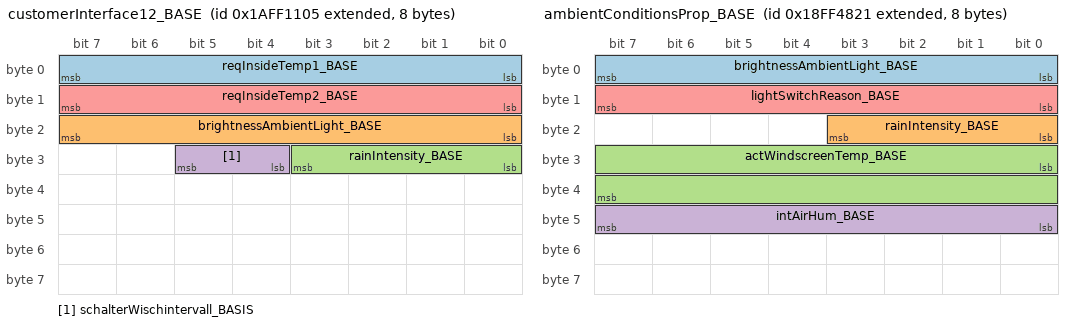
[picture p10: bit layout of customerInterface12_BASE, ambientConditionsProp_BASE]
BO_ 2600407301 customerInterface12_BASE: 8 Vector__XXX
 SG_ reqInsideTemp1_BASE : 0|8@1+ (0.33,-30) [-30|52.5] "°C" CM4
 SG_ brightnessAmbientLight_BASE : 16|8@1+ (100,0) [0|25000] "lx" CM4
 SG_ rainIntensity_BASE : 24|4@1+ (1,0) [0|0] "-" CM4
 SG_ schalterWischintervall_BASIS : 28|2@1+ (1,0) [0|0] "-" CM4
 SG_ reqInsideTemp2_BASE : 8|8@1+ (0.33,-30) [-30|52.5] "°C" CM4

BO_ 2565903754 HVESSD6_BASE: 8 Vector__XXX
 SG_ HVESSintakeCoolantTemp_BASE : 32|8@1+ (1,-40) [-40|210] "°C" CM4
 SG_ HVESStemperature_BASE : 56|8@1+ (1,-40) [-40|210] "°C" CM4

BO_ 2566866977 ambientConditionsProp_BASE: 8 Vector__XXX
 SG_ brightnessAmbientLight_BASE : 0|8@1+ (100,0) [0|25000] "lx" CM4
 SG_ rainIntensity_BASE : 16|4@1+ (1,0) [0|0] "-" CM4
 SG_ actWindscreenTemp_BASE : 24|16@1+ (0.03125,-273) [-273|1734.96875] "°C" CM4
 SG_ intAirHum_BASE : 40|8@1+ (0.4,0) [0|100] "%" CM4
 SG_ lightSwitchReason_BASE : 8|8@1+ (1,0) [0|0] "-" CM4

BO_ 2566771850 CM3_BASE: 8 Vector__XXX
 SG_ oprtnKeySwIgnPow_BASE : 20|2@1+ (1,0) [0|0] "-" CM4

BO_ 2364610442 DCDC1S2_BASE: 8 Vector__XXX
 SG_ lowSidePowerDCDC_BASE : 0|16@1+ (0.05,-1600) [-1600|1612.75] "kW" CM4

BO_ 2364579978 HVESSD7_BASE: 8 Vector__XXX
 SG_ HVESSdischgEnCpcty_BASE : 0|24@1+ (0.001,0) [0|16449.535] "kWh" CM4

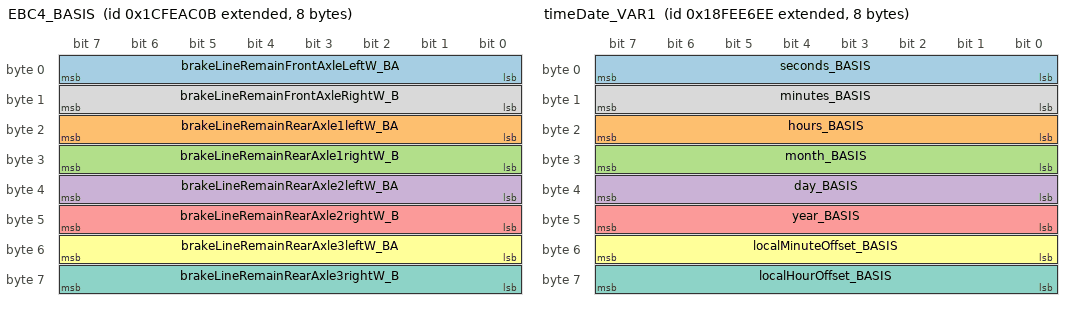
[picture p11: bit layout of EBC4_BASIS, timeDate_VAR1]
BO_ 2633935883 EBC4_BASIS: 8 Vector__XXX
 SG_ brakeLineRemainFrontAxleLeftW_BA : 0|8@1+ (0.4,0) [0|100] "%" CM4
 SG_ brakeLineRemainRearAxle1leftW_BA : 16|8@1+ (0.4,0) [0|100] "%" CM4
 SG_ brakeLineRemainRearAxle1rightW_B : 24|8@1+ (0.4,0) [0|100] "%" CM4
 SG_ brakeLineRemainRearAxle2leftW_BA : 32|8@1+ (0.4,0) [0|100] "%" CM4
 SG_ brakeLineRemainRearAxle2rightW_B : 40|8@1+ (0.4,0) [0|100] "%" CM4
 SG_ brakeLineRemainRearAxle3leftW_BA : 48|8@1+ (0.4,0) [0|100] "%" CM4
 SG_ brakeLineRemainRearAxle3rightW_B : 56|8@1+ (0.4,0) [0|100] "%" CM4
 SG_ brakeLineRemainFrontAxleRightW_B : 8|8@1+ (0.4,0) [0|100] "%" CM4

BO_ 2566842094 timeDate_VAR1: 8 Vector__XXX
 SG_ seconds_BASIS : 0|8@1+ (0.25,0) [0|62.5] "s" CM4
 SG_ hours_BASIS : 16|8@1+ (1,0) [0|250] "h" CM4
 SG_ month_BASIS : 24|8@1+ (1,0) [0|250] "month" CM4
 SG_ day_BASIS : 32|8@1+ (0.25,0) [0|62.5] "day" CM4
 SG_ year_BASIS : 40|8@1+ (1,1985) [1985|2235] "year" CM4
 SG_ localMinuteOffset_BASIS : 48|8@1+ (1,-125) [-125|125] "min" CM4
 SG_ localHourOffset_BASIS : 56|8@1+ (1,-125) [-125|125] "h" CM4
 SG_ minutes_BASIS : 8|8@1+ (1,0) [0|250] "min" CM4

BO_ 2583638092 appControlInterface_VAR1: 8 Vector__XXX
 SG_ appFrameworkAppID_BASE : 0|16@1+ (1,0) [0|64255] "-" CM4
 SG_ appFrameworkAppState_BASE : 16|8@1+ (1,0) [0|0] "-" CM4

BO_ 2564488174 UDSresp_DTCO2TBM: 8 Vector__XXX
 SG_ UDSresp_DTCO2TBM : 0|8@1+ (1,0) [0|255] "-" CM4

BO_ 2564430062 UDSresp_DTCO2CM4: 8 Vector__XXX
 SG_ UDSresp_DTCO2CM4 : 0|8@1+ (1,0) [0|255] "-" CM4

BO_ 2600422183 CVM_13_BASE: 8 Vector__XXX
 SG_ frceAirflushActive_BASE : 0|2@1+ (1,0) [0|0] "-" CM4
 SG_ actPrkHtrProgData_BASE : 10|2@1+ (1,0) [0|0] "-" CM4
 SG_ reqSilentMode_BASE : 12|2@1+ (1,0) [0|0] "-" CM4
 SG_ washerPumpFront_BASE : 14|2@1+ (1,0) [0|0] "-" CM4
 SG_ eco24VshutOffReq_BASE : 16|2@1+ (1,0) [0|0] "-" CM4
 SG_ mainSwitchShutOffInfo_BASE : 18|2@1+ (1,0) [0|0] "-" CM4
 SG_ actForceReqAC_BASE : 2|2@1+ (1,0) [0|0] "-" CM4
 SG_ infoEmgcyShutOff_BASE : 20|2@1+ (1,0) [0|0] "-" CM4
 SG_ revGearHVAC_BASE : 22|2@1+ (1,0) [0|0] "-" CM4
 SG_ eco24VpwrSaveReq_BASE : 24|8@1+ (1,0) [0|0] "-" CM4
 SG_ egyModeHVAC_BASE : 32|8@1+ (1,0) [0|0] "-" CM4
 SG_ prkHtrEnabled_BASE : 4|2@1+ (1,0) [0|0] "-" CM4
 SG_ tempReduceCorrect_BASE : 40|8@1+ (0.1,0) [0|10] "°C" CM4
 SG_ drvSysOff_BASE : 48|2@1+ (1,0) [0|0] "-" CM4
 SG_ wiperMotorFrontStep1_BASE : 50|2@1+ (1,0) [0|0] "-" CM4
 SG_ wiperMotorFrontStep2_BASE : 52|2@1+ (1,0) [0|0] "-" CM4
 SG_ stopStartActvnState_BASE : 54|2@1+ (1,0) [0|0] "-" CM4
 SG_ CVM13cntE2E_BASE : 56|4@1+ (1,0) [0|15] "-" CM4
 SG_ windscreenHeatingDisp_BASE : 6|2@1+ (1,0) [0|0] "-" CM4
 SG_ CVM13chkE2E_BASE : 60|4@1+ (1,0) [0|15] "-" CM4
 SG_ reqElManual_BASE : 8|2@1+ (1,0) [0|0] "-" CM4

BO_ 2600460311 RTinst1_BASE: 8 Vector__XXX
 SG_ rmtTstrInstallMsgHeaderReq_BASE : 0|16@1+ (1,0) [0|0] "-" CM4
 SG_ rmtTstrInstallJobIdReq_BASE : 16|8@1+ (1,0) [0|250] "-" CM4
 SG_ rmtTstrInstallListIdxReq_BASE : 24|8@1+ (1,0) [0|250] "-" CM4

BO_ 2600462375 LCprop2_BASE: 8 Vector__XXX
 SG_ selectedLanguage_BASE : 48|8@1+ (1,0) [0|0] "-" CM4

BO_ 2364547840 A1SCRdosingSysInfo1_VAR2: 8 Vector__XXX
 SG_ A1SCRactDosingUreaQuantity_BASE : 0|16@1+ (0.3,0) [0|19276.5] "g/h" CM4

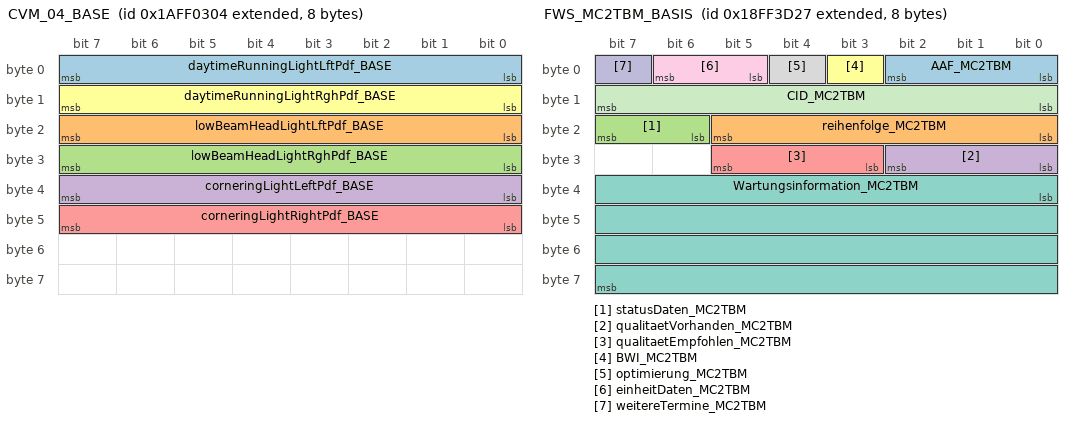
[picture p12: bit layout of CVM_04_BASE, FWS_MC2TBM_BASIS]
BO_ 2600403716 CVM_04_BASE: 8 Vector__XXX
 SG_ daytimeRunningLightLftPdf_BASE : 0|8@1+ (0.4,0) [0|100] "%" CM4
 SG_ lowBeamHeadLightLftPdf_BASE : 16|8@1+ (0.4,0) [0|100] "%" CM4
 SG_ lowBeamHeadLightRghPdf_BASE : 24|8@1+ (0.4,0) [0|100] "%" CM4
 SG_ corneringLightLeftPdf_BASE : 32|8@1+ (0.4,0) [0|100] "%" CM4
 SG_ corneringLightRightPdf_BASE : 40|8@1+ (0.4,0) [0|100] "%" CM4
 SG_ daytimeRunningLightRghPdf_BASE : 8|8@1+ (0.4,0) [0|100] "%" CM4

BO_ 2566832622 highResolutionVehicleDistance_BA: 8 Vector__XXX
 SG_ highResolutionTotalVehDistance_B : 0|32@1+ (0.005,0) [0|21055406] "km" CM4
 SG_ highResolutionTripDistance_BASIS : 32|32@1+ (0.005,0) [0|21055406] "km" CM4

BO_ 2566864167 FWS_MC2TBM_BASIS: 8 Vector__XXX
 SG_ AAF_MC2TBM : 0|3@1+ (1,0) [0|0] "-" CM4
 SG_ reihenfolge_MC2TBM : 16|6@1+ (1,0) [0|0] "-" CM4
 SG_ statusDaten_MC2TBM : 22|2@1+ (1,0) [0|0] "-" CM4
 SG_ qualitaetVorhanden_MC2TBM : 24|3@1+ (1,0) [0|0] "-" CM4
 SG_ qualitaetEmpfohlen_MC2TBM : 27|3@1+ (1,0) [0|0] "-" CM4
 SG_ BWI_MC2TBM : 3|1@1+ (1,0) [0|0] "-" CM4
 SG_ Wartungsinformation_MC2TBM : 32|32@1+ (1,0) [0|4294967295] "-" CM4
 SG_ optimierung_MC2TBM : 4|1@1+ (1,0) [0|0] "-" CM4
 SG_ einheitDaten_MC2TBM : 5|2@1+ (1,0) [0|0] "-" CM4
 SG_ weitereTermine_MC2TBM : 7|1@1+ (1,0) [0|0] "-" CM4
 SG_ CID_MC2TBM : 8|8@1+ (1,0) [0|255] "-" CM4

BO_ 2364642442 HVESP1D4_BASE: 8 Vector__XXX
 SG_ HVESP1dischargeCapacity_BASE : 0|16@1+ (0.01,0) [0|642.55] "Ah" CM4

BO_ 2364646282 HVESP2D4_BASE: 8 Vector__XXX
 SG_ HVESP2dischargeCapacity_BASE : 0|16@1+ (0.01,0) [0|642.55] "Ah" CM4

BO_ 2364650122 HVESP3D4_BASE: 8 Vector__XXX
 SG_ HVESP3dischargeCapacity_BASE : 0|16@1+ (0.01,0) [0|642.55] "Ah" CM4

BO_ 2364661642 HVESP6D4_BASE: 8 Vector__XXX
 SG_ HVESP6dischargeCapacity_BASE : 0|16@1+ (0.01,0) [0|642.55] "Ah" CM4

BO_ 2364653962 HVESP4D4_BASE: 8 Vector__XXX
 SG_ HVESP4dischargeCapacity_BASE : 0|16@1+ (0.01,0) [0|642.55] "Ah" CM4

BO_ 2364657802 HVESP5D4_BASE: 8 Vector__XXX
 SG_ HVESP5dischargeCapacity_BASE : 0|16@1+ (0.01,0) [0|642.55] "Ah" CM4

BO_ 2364676234 HVESP7D4_BASE: 8 Vector__XXX
 SG_ HVESP7dischargeCapacity_BASE : 0|16@1+ (0.01,0) [0|642.55] "Ah" CM4

BO_ 2364680074 HVESP8D4_BASE: 8 Vector__XXX
 SG_ HVESP8dischargeCapacity_BASE : 0|16@1+ (0.01,0) [0|642.55] "Ah" CM4

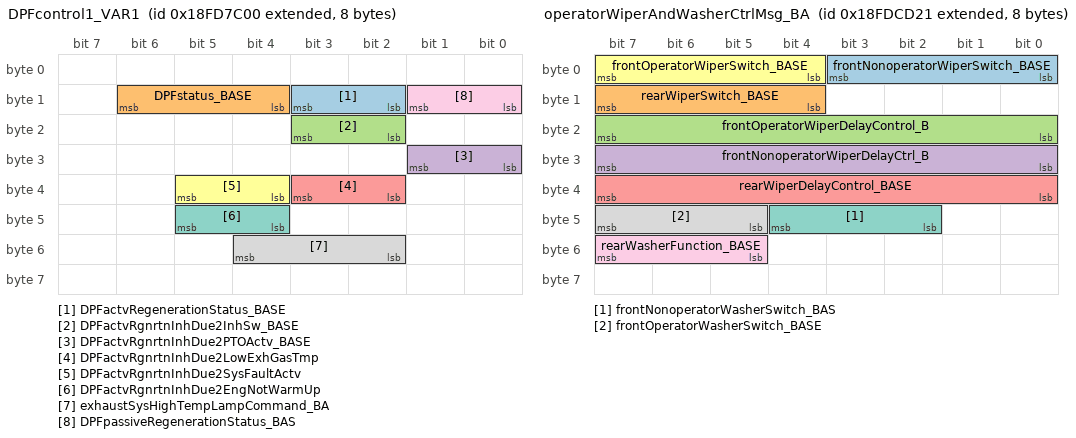
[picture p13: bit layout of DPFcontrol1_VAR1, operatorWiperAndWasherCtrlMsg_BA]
BO_ 2566749184 DPFcontrol1_VAR1: 8 Vector__XXX
 SG_ DPFactvRegenerationStatus_BASE : 10|2@1+ (1,0) [0|0] "-" CM4
 SG_ DPFstatus_BASE : 12|3@1+ (1,0) [0|0] "-" CM4
 SG_ DPFactvRgnrtnInhDue2InhSw_BASE : 18|2@1+ (1,0) [0|0] "-" CM4
 SG_ DPFactvRgnrtnInhDue2PTOActv_BASE : 24|2@1+ (1,0) [0|0] "-" CM4
 SG_ DPFactvRgnrtnInhDue2LowExhGasTmp : 34|2@1+ (1,0) [0|0] "-" CM4
 SG_ DPFactvRgnrtnInhDue2SysFaultActv : 36|2@1+ (1,0) [0|0] "-" CM4
 SG_ DPFactvRgnrtnInhDue2EngNotWarmUp : 44|2@1+ (1,0) [0|0] "-" CM4
 SG_ exhaustSysHighTempLampCommand_BA : 50|3@1+ (1,0) [0|0] "-" CM4
 SG_ DPFpassiveRegenerationStatus_BAS : 8|2@1+ (1,0) [0|0] "-" CM4

BO_ 2566769953 operatorWiperAndWasherCtrlMsg_BA: 8 Vector__XXX
 SG_ frontNonoperatorWiperSwitch_BASE : 0|4@1+ (1,0) [0|0] "-" CM4
 SG_ rearWiperSwitch_BASE : 12|4@1+ (1,0) [0|0] "-" CM4
 SG_ frontOperatorWiperDelayControl_B : 16|8@1+ (0.4,0) [0|100] "%" CM4
 SG_ frontNonoperatorWiperDelayCtrl_B : 24|8@1+ (0.4,0) [0|100] "%" CM4
 SG_ rearWiperDelayControl_BASE : 32|8@1+ (0.4,0) [0|100] "%" CM4
 SG_ frontOperatorWiperSwitch_BASE : 4|4@1+ (1,0) [0|0] "-" CM4
 SG_ frontNonoperatorWasherSwitch_BAS : 42|3@1+ (1,0) [0|0] "-" CM4
 SG_ frontOperatorWasherSwitch_BASE : 45|3@1+ (1,0) [0|0] "-" CM4
 SG_ rearWasherFunction_BASE : 53|3@1+ (1,0) [0|0] "-" CM4

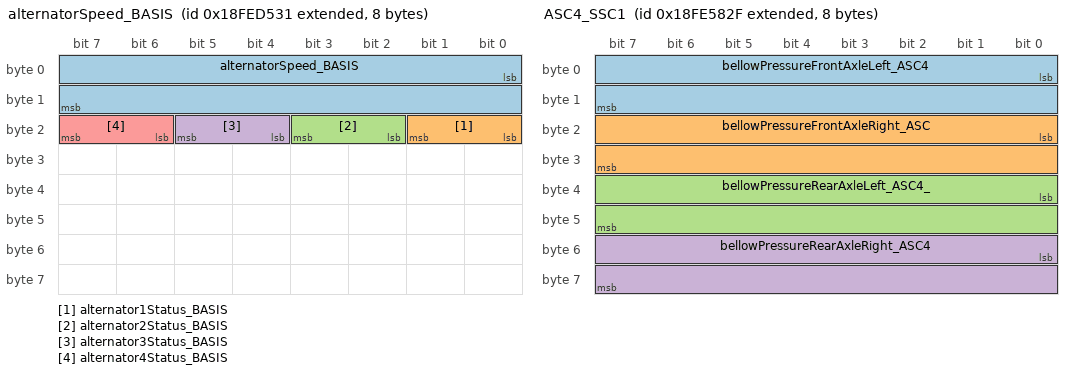
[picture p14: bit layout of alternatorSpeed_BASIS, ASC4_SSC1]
BO_ 2566837553 alternatorSpeed_BASIS: 8 Vector__XXX
 SG_ alternatorSpeed_BASIS : 0|16@1+ (0.5,0) [0|32127.5] "rpm" CM4
 SG_ alternator1Status_BASIS : 16|2@1+ (1,0) [0|0] "-" CM4
 SG_ alternator2Status_BASIS : 18|2@1+ (1,0) [0|0] "-" CM4
 SG_ alternator3Status_BASIS : 20|2@1+ (1,0) [0|0] "-" CM4
 SG_ alternator4Status_BASIS : 22|2@1+ (1,0) [0|0] "-" CM4

BO_ 2566805551 ASC4_SSC1: 8 Vector__XXX
 SG_ bellowPressureFrontAxleLeft_ASC4 : 0|16@1+ (0.1,0) [0|6425.5] "kPa" CM4
 SG_ bellowPressureFrontAxleRight_ASC : 16|16@1+ (0.1,0) [0|6425.5] "kPa" CM4
 SG_ bellowPressureRearAxleLeft_ASC4_ : 32|16@1+ (0.1,0) [0|6425.5] "kPa" CM4
 SG_ bellowPressureRearAxleRight_ASC4 : 48|16@1+ (0.1,0) [0|6425.5] "kPa" CM4

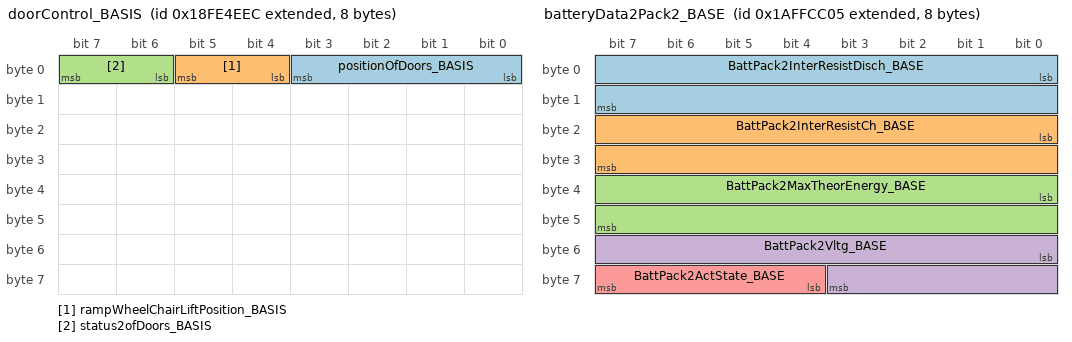
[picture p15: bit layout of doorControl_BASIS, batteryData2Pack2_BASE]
BO_ 2566803180 doorControl_BASIS: 8 Vector__XXX
 SG_ positionOfDoors_BASIS : 0|4@1+ (1,0) [0|0] "-" CM4
 SG_ rampWheelChairLiftPosition_BASIS : 4|2@1+ (1,0) [0|0] "-" CM4
 SG_ status2ofDoors_BASIS : 6|2@1+ (1,0) [0|0] "-" CM4

BO_ 2566876928 vehicleDimensions1_BASE: 8 Vector__XXX
 SG_ bodyLength_BASE : 0|16@1+ (1,0) [0|30000] "mm" CM4
 SG_ bodyWidth_BASE : 16|16@1+ (1,0) [0|3000] "mm" CM4
 SG_ bodyHeight_BASE : 32|16@1+ (1,0) [0|10000] "mm" CM4
 SG_ passengerCapacity_BASE : 48|8@1+ (1,0) [0|250] "-" CM4

BO_ 2566842151 vehicleHours_BASE: 8 Vector__XXX
 SG_ totalVehicleHours_BASE : 0|32@1+ (0.05,0) [0|210554060.75] "h" CM4
 SG_ totalPowerTakeoffHours_BASE : 32|32@1+ (0.05,0) [0|210554060.75] "h" CM4

BO_ 2600455183 batteryData3Pack4_BASE: 8 Vector__XXX
 SG_ BattPack4ActTemp_BASE : 24|8@1+ (0.5,-40) [-40|85] "°C" CM4
 SG_ BattPack4Curr_BASE : 32|12@1+ (0.5,-1024) [-1024|983.5] "A" CM4
 SG_ BattPack4TechSoC_BASE : 48|14@1+ (0.01,0) [0|100] "%" CM4

BO_ 2600455173 batteryData2Pack2_BASE: 8 Vector__XXX
 SG_ BattPack2InterResistDisch_BASE : 0|16@1+ (0.00012207,0) [0|7.8436078499999997149] "Ohm" CM4
 SG_ BattPack2InterResistCh_BASE : 16|16@1+ (0.00012207,0) [0|7.8436078499999997149] "Ohm" CM4
 SG_ BattPack2MaxTheorEnergy_BASE : 32|16@1+ (2,0) [0|128510] "Wh" CM4
 SG_ BattPack2Vltg_BASE : 48|12@1+ (0.25,0) [0|1003.75] "V" CM4
 SG_ BattPack2ActState_BASE : 60|4@1+ (1,0) [0|0] "-" CM4

BO_ 2600455181 batteryData3Pack2_BASE: 8 Vector__XXX
 SG_ BattPack2ActTemp_BASE : 24|8@1+ (0.5,-40) [-40|85] "°C" CM4
 SG_ BattPack2Curr_BASE : 32|12@1+ (0.5,-1024) [-1024|983.5] "A" CM4
 SG_ BattPack2TechSoC_BASE : 48|14@1+ (0.01,0) [0|100] "%" CM4

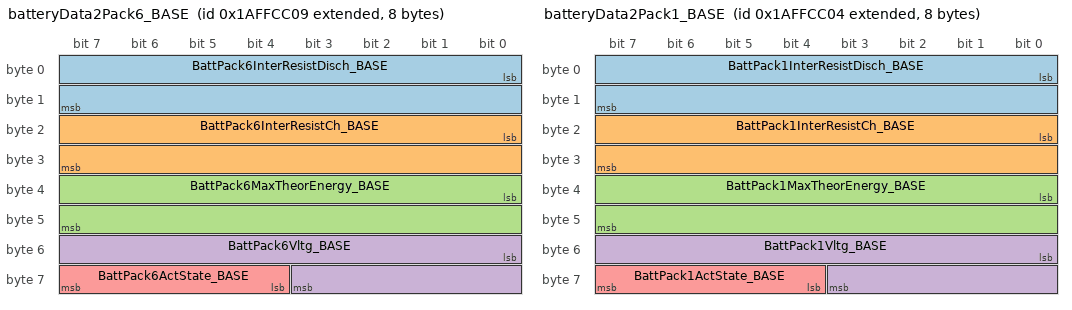
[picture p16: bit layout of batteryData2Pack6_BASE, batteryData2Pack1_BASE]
BO_ 2600455177 batteryData2Pack6_BASE: 8 Vector__XXX
 SG_ BattPack6InterResistDisch_BASE : 0|16@1+ (0.00012207,0) [0|7.8436078499999997149] "Ohm" CM4
 SG_ BattPack6InterResistCh_BASE : 16|16@1+ (0.00012207,0) [0|7.8436078499999997149] "Ohm" CM4
 SG_ BattPack6MaxTheorEnergy_BASE : 32|16@1+ (2,0) [0|128510] "Wh" CM4
 SG_ BattPack6Vltg_BASE : 48|12@1+ (0.25,0) [0|1003.75] "V" CM4
 SG_ BattPack6ActState_BASE : 60|4@1+ (1,0) [0|0] "-" CM4

BO_ 2600455185 batteryData3Pack6_BASE: 8 Vector__XXX
 SG_ BattPack6ActTemp_BASE : 24|8@1+ (0.5,-40) [-40|85] "°C" CM4
 SG_ BattPack6Curr_BASE : 32|12@1+ (0.5,-1024) [-1024|983.5] "A" CM4
 SG_ BattPack6TechSoC_BASE : 48|14@1+ (0.01,0) [0|100] "%" CM4

BO_ 2600455172 batteryData2Pack1_BASE: 8 Vector__XXX
 SG_ BattPack1InterResistDisch_BASE : 0|16@1+ (0.00012207,0) [0|7.8436078499999997149] "Ohm" CM4
 SG_ BattPack1InterResistCh_BASE : 16|16@1+ (0.00012207,0) [0|7.8436078499999997149] "Ohm" CM4
 SG_ BattPack1MaxTheorEnergy_BASE : 32|16@1+ (2,0) [0|128510] "Wh" CM4
 SG_ BattPack1Vltg_BASE : 48|12@1+ (0.25,0) [0|1003.75] "V" CM4
 SG_ BattPack1ActState_BASE : 60|4@1+ (1,0) [0|0] "-" CM4

BO_ 2600455182 batteryData3Pack3_BASE: 8 Vector__XXX
 SG_ BattPack3ActTemp_BASE : 24|8@1+ (0.5,-40) [-40|85] "°C" CM4
 SG_ BattPack3Curr_BASE : 32|12@1+ (0.5,-1024) [-1024|983.5] "A" CM4
 SG_ BattPack3TechSoC_BASE : 48|14@1+ (0.01,0) [0|100] "%" CM4

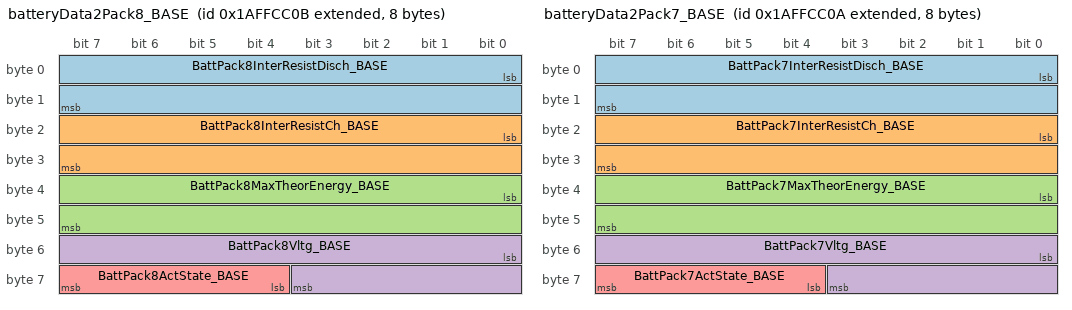
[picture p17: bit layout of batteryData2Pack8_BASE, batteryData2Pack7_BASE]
BO_ 2600455179 batteryData2Pack8_BASE: 8 Vector__XXX
 SG_ BattPack8InterResistDisch_BASE : 0|16@1+ (0.00012207,0) [0|7.8436078499999997149] "Ohm" CM4
 SG_ BattPack8InterResistCh_BASE : 16|16@1+ (0.00012207,0) [0|7.8436078499999997149] "Ohm" CM4
 SG_ BattPack8MaxTheorEnergy_BASE : 32|16@1+ (2,0) [0|128510] "Wh" CM4
 SG_ BattPack8Vltg_BASE : 48|12@1+ (0.25,0) [0|1003.75] "V" CM4
 SG_ BattPack8ActState_BASE : 60|4@1+ (1,0) [0|0] "-" CM4

BO_ 2600455178 batteryData2Pack7_BASE: 8 Vector__XXX
 SG_ BattPack7InterResistDisch_BASE : 0|16@1+ (0.00012207,0) [0|7.8436078499999997149] "Ohm" CM4
 SG_ BattPack7InterResistCh_BASE : 16|16@1+ (0.00012207,0) [0|7.8436078499999997149] "Ohm" CM4
 SG_ BattPack7MaxTheorEnergy_BASE : 32|16@1+ (2,0) [0|128510] "Wh" CM4
 SG_ BattPack7Vltg_BASE : 48|12@1+ (0.25,0) [0|1003.75] "V" CM4
 SG_ BattPack7ActState_BASE : 60|4@1+ (1,0) [0|0] "-" CM4

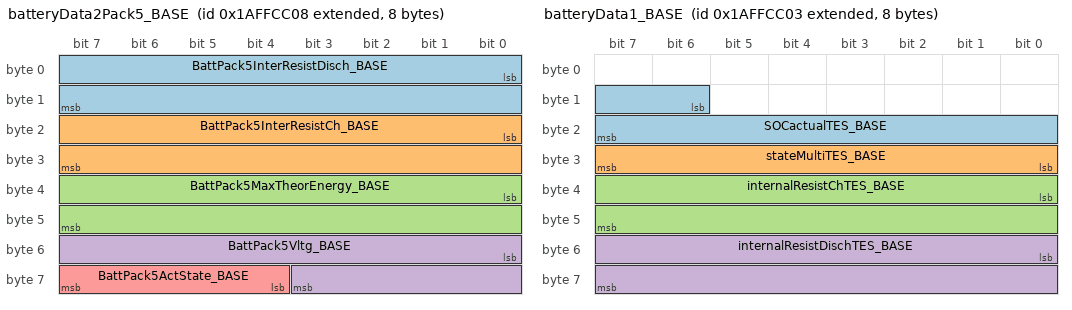
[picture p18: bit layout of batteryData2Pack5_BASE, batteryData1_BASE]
BO_ 2600455176 batteryData2Pack5_BASE: 8 Vector__XXX
 SG_ BattPack5InterResistDisch_BASE : 0|16@1+ (0.00012207,0) [0|7.8436078499999997149] "Ohm" CM4
 SG_ BattPack5InterResistCh_BASE : 16|16@1+ (0.00012207,0) [0|7.8436078499999997149] "Ohm" CM4
 SG_ BattPack5MaxTheorEnergy_BASE : 32|16@1+ (2,0) [0|128510] "Wh" CM4
 SG_ BattPack5Vltg_BASE : 48|12@1+ (0.25,0) [0|1003.75] "V" CM4
 SG_ BattPack5ActState_BASE : 60|4@1+ (1,0) [0|0] "-" CM4

BO_ 2600455180 batteryData3Pack1_BASE: 8 Vector__XXX
 SG_ BattPack1ActTemp_BASE : 24|8@1+ (0.5,-40) [-40|85] "°C" CM4
 SG_ BattPack1Curr_BASE : 32|12@1+ (0.5,-1024) [-1024|983.5] "A" CM4
 SG_ BattPack1TechSoC_BASE : 48|14@1+ (0.01,0) [0|100] "%" CM4

BO_ 2600455186 batteryData3Pack7_BASE: 8 Vector__XXX
 SG_ BattPack7ActTemp_BASE : 24|8@1+ (0.5,-40) [-40|85] "°C" CM4
 SG_ BattPack7Curr_BASE : 32|12@1+ (0.5,-1024) [-1024|983.5] "A" CM4
 SG_ BattPack7TechSoC_BASE : 48|14@1+ (0.01,0) [0|100] "%" CM4

BO_ 2600455171 batteryData1_BASE: 8 Vector__XXX
 SG_ SOCactualTES_BASE : 14|10@1+ (0.1,0) [0|102.1] "%" CM4
 SG_ stateMultiTES_BASE : 24|8@1+ (1,0) [0|0] "-" CM4
 SG_ internalResistChTES_BASE : 32|16@1+ (0.1,0) [0|6425.5] "mOhm" CM4
 SG_ internalResistDischTES_BASE : 48|16@1+ (0.1,0) [0|6425.5] "mOhm" CM4

BO_ 2600455184 batteryData3Pack5_BASE: 8 Vector__XXX
 SG_ BattPack5ActTemp_BASE : 24|8@1+ (0.5,-40) [-40|85] "°C" CM4
 SG_ BattPack5Curr_BASE : 32|12@1+ (0.5,-1024) [-1024|983.5] "A" CM4
 SG_ BattPack5TechSoC_BASE : 48|14@1+ (0.01,0) [0|100] "%" CM4

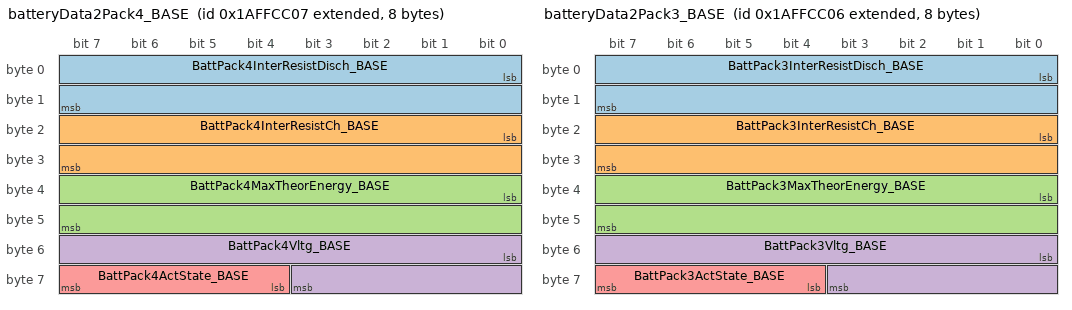
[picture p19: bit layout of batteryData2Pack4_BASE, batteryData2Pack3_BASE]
BO_ 2600455175 batteryData2Pack4_BASE: 8 Vector__XXX
 SG_ BattPack4InterResistDisch_BASE : 0|16@1+ (0.00012207,0) [0|7.8436078499999997149] "Ohm" CM4
 SG_ BattPack4InterResistCh_BASE : 16|16@1+ (0.00012207,0) [0|7.8436078499999997149] "Ohm" CM4
 SG_ BattPack4MaxTheorEnergy_BASE : 32|16@1+ (2,0) [0|128510] "Wh" CM4
 SG_ BattPack4Vltg_BASE : 48|12@1+ (0.25,0) [0|1003.75] "V" CM4
 SG_ BattPack4ActState_BASE : 60|4@1+ (1,0) [0|0] "-" CM4

BO_ 2600455187 batteryData3Pack8_BASE: 8 Vector__XXX
 SG_ BattPack8ActTemp_BASE : 24|8@1+ (0.5,-40) [-40|85] "°C" CM4
 SG_ BattPack8Curr_BASE : 32|12@1+ (0.5,-1024) [-1024|983.5] "A" CM4
 SG_ BattPack8TechSoC_BASE : 48|14@1+ (0.01,0) [0|100] "%" CM4

BO_ 2600455174 batteryData2Pack3_BASE: 8 Vector__XXX
 SG_ BattPack3InterResistDisch_BASE : 0|16@1+ (0.00012207,0) [0|7.8436078499999997149] "Ohm" CM4
 SG_ BattPack3InterResistCh_BASE : 16|16@1+ (0.00012207,0) [0|7.8436078499999997149] "Ohm" CM4
 SG_ BattPack3MaxTheorEnergy_BASE : 32|16@1+ (2,0) [0|128510] "Wh" CM4
 SG_ BattPack3Vltg_BASE : 48|12@1+ (0.25,0) [0|1003.75] "V" CM4
 SG_ BattPack3ActState_BASE : 60|4@1+ (1,0) [0|0] "-" CM4

BO_ 2566846247 vehicleElectricalPower_VAR1: 8 Vector__XXX
 SG_ electricalPotential_BASIS : 32|16@1+ (0.05,0) [0|3212.75] "V" CM4

BO_ 2566843630 VI_VAR5: 18 Vector__XXX
 SG_ vehicleID_VAR1 : 0|144@1+ (1,0) [0|0] "-" CM4

CM_ BO_ 2600460568 "Proprietary message RTprop2 of the remote tester";
CM_ SG_ 2600460568 rmtTstrBattCurrentOTA_BASE "Current (in Ampere) that would be drawn from the 24V battery during a FOTA update, when unnecessary consumers would be deactivated.";
CM_ SG_ 2600460568 rmtTstrInstallProgressBar_BASE "Percentage of the progress of a Remote Tester job installation.";
CM_ SG_ 2600460568 rmtTstrDispCondC1gearNeut_BASE "Signal from Remote-Tester when to show the condition gear is in neutral position as fulfilled and when not.";
CM_ SG_ 2600460568 rmtTstrDispCondC1VehSpd_BASE "Signal from Remote-Tester when to show the condition vehicle speed is zero as fulfilled and when not.";
CM_ SG_ 2600460568 rmtTstrDispCondC1ParkBrake_BASE "Signal from Remote-Tester when to show the condition parking brake is engaged as fulfilled and when not.";
CM_ SG_ 2600460568 rmtTstrDispCondC1engSpd_BASE "Signal from Remote-Tester when to show the condition engine speed is zero as fulfilled and when not.";
CM_ SG_ 2600460568 rmtTstrDispCondIgnition_BASE "Signal from Remote-Tester when to show the condition ignition on as fulfilled and when not.";
CM_ SG_ 2600460568 rmtTstrDispCondOBD_BASE "Signal from Remote-Tester when to show the condition no diagnostic communication at OBD connector as fulfilled and when not.";
CM_ SG_ 2600460568 rmtTstrDispICLreset_BASE "Signal from Remote-Tester when to show the additional hint during installation that the cluster will be resetted.";
CM_ SG_ 2600460568 rmtTstrDispUpdateAvail_BASE "Signal from Remote-Tester when to show the driver notice (popup) in the cluster.";
CM_ SG_ 2600460568 rmtTstrInstallNumOfJobs_BASE "Total number of Remote Tester jobs. Used in list notification message: RemoteTesterFeatureList_Update: RemoteTesterFeatureList_Update.noOfJobs Please refer also to: Service Specification for RemoteTesterFeatureList (ServiceSpec_RemoteTesterFeatureList.pdf";
CM_ SG_ 2600460568 rmtTstrInstallTxtUpdToggle_BASE "Update toggle bit indicates a change in the text information. Used only in list notification message RemoteTesterFeatureList_Update. Please refer also to: Service Specification for RemoteTesterFeatureList (ServiceSpec_RemoteTesterFeatureList.pdf)";
CM_ SG_ 2600460568 rmtTstrDispCondEPTO_BASE "Signal from Remote-Tester when to show the condition ePTO deactivated as fulfilled and when not.";
CM_ SG_ 2600460568 rmtTstrDispCond24VBattChrg_BASE "Signal from Remote-Tester when to show the condition 24V Battery sufficiently charged as fulfilled and when not.";
CM_ SG_ 2600460568 rmtTstrDispCondSecCerts_BASE "Signal from Remote-Tester when to show the condition security certificates are valid (up to date) as fulfilled and when not.";
CM_ SG_ 2600460568 rmtTstrDispCondCurrent_BASE "Binary indicator whether current power consumption (battery current) is too high for FOTA update. The condition is not fulfilled if the power consumption is too high.";
CM_ SG_ 2600460568 rmtTstrDispAllowDriverExit_BASE "Signal indicates whether the driver allowed to exit the vehicle during an OTA installation process.";
CM_ SG_ 2600460568 rmtTstrDispCondExtrnlChrg_BASE "Binary indicator whether an external charging cable (EV) is connected. Condition is fulfilled when NO charging cable is connected.";
CM_ SG_ 2600460568 rmtTstrOverrideCl15_BASE "Request to override the ignition request from driver starter switch and switch CL15 relais ON.";
CM_ SG_ 2600460568 rmtTstrInstallEstTotTime_VAR1 "Estimated time in minutes to execute all remote tester jobs.";
CM_ SG_ 2566834939 protectLampStatus_CM4_SAE "Protect Lamp Status (PL)";
CM_ SG_ 2566834939 flashAmberWarningLamp_CM4_SAE "Flash AWL";
CM_ SG_ 2566834939 SPN_high_reserved03_CM4_SAE "SPN High Reserved 03";
CM_ SG_ 2566834939 OcC_03_CM4_SAE "OcC 03";
CM_ SG_ 2566834939 CM_03_CM4_SAE "CM 03";
CM_ SG_ 2566834939 SPN_04_CM4_SAE "SPN 04";
CM_ SG_ 2566834939 flashRedStopLamp_CM4_SAE "Flash RSL";
CM_ SG_ 2566834939 FMI_04_CM4_SAE "FM1 04";
CM_ SG_ 2566834939 SPN_high_reserved04_CM4_SAE "SPN High Reserved 04";
CM_ SG_ 2566834939 OcC_04_CM4_SAE "OcC 04";
CM_ SG_ 2566834939 flashMalFunctionalIndicatorLamp_ "Flash MIL";
CM_ SG_ 2566834939 CM_04_CM4_SAE "CM 04";
CM_ SG_ 2566834939 SPN_05_CM4_SAE "SPN 05";
CM_ SG_ 2566834939 SPN_01_CM4_SAE "SPN 01";
CM_ SG_ 2566834939 FMI_05_CM4_SAE "FM1 05";
CM_ SG_ 2566834939 SPN_high_reserved05_CM4_SAE "SPN High Reserved 05";
CM_ SG_ 2566834939 OcC_05_CM4_SAE "OcC 05";
CM_ SG_ 2566834939 CM_05_CM4_SAE "CM 05";
CM_ SG_ 2566834939 SPN_06_CM4_SAE "SPN 06";
CM_ SG_ 2566834939 FMI_06_CM4_SAE "FM1 06";
CM_ SG_ 2566834939 SPN_high_reserved06_CM4_SAE "SPN High Reserved 06";
CM_ SG_ 2566834939 amberWarningLamp_CM4_SAE "Amber Warning Lamp (AWL)";
CM_ SG_ 2566834939 OcC_06_CM4_SAE "OcC 06";
CM_ SG_ 2566834939 CM_06_CM4_SAE "CM 06";
CM_ SG_ 2566834939 SPN_07_CM4_SAE "SPN 07";
CM_ SG_ 2566834939 FMI_07_CM4_SAE "FM1 07";
CM_ SG_ 2566834939 SPN_high_reserved07_CM4_SAE "SPN High Reserved 07";
CM_ SG_ 2566834939 OcC_07_CM4_SAE "OcC 07";
CM_ SG_ 2566834939 CM_07_CM4_SAE "CM 07";
CM_ SG_ 2566834939 SPN_08_CM4_SAE "SPN 08";
CM_ SG_ 2566834939 FMI_08_CM4_SAE "FM1 08";
CM_ SG_ 2566834939 SPN_high_reserved08_CM4_SAE "SPN High Reserved 08";
CM_ SG_ 2566834939 OcC_08_CM4_SAE "OcC 08";
CM_ SG_ 2566834939 CM_08_CM4_SAE "CM 08";
CM_ SG_ 2566834939 SPN_09_CM4_SAE "SPN 09";
CM_ SG_ 2566834939 FMI_09_CM4_SAE "FM1 09";
CM_ SG_ 2566834939 SPN_high_reserved09_CM4_SAE "SPN High Reserved 09";
CM_ SG_ 2566834939 OcC_09_CM4_SAE "OcC 09";
CM_ SG_ 2566834939 CM_09_CM4_SAE "CM 09";
CM_ SG_ 2566834939 SPN_10_CM4_SAE "SPN 10";
CM_ SG_ 2566834939 FMI_01_CM4_SAE "FM1 01";
CM_ SG_ 2566834939 FMI_10_CM4_SAE "FM1 10";
CM_ SG_ 2566834939 SPN_high_reserved10_CM4_SAE "SPN High Reserved 10";
CM_ SG_ 2566834939 OcC_10_CM4_SAE "OcC 10";
CM_ SG_ 2566834939 CM_10_CM4_SAE "CM 10";
CM_ SG_ 2566834939 SPN_high_reserved01_CM4_SAE "SPN High Reserved 01";
CM_ SG_ 2566834939 redStopLamp_CM4_SAE "Red Stop Lamp (RSL)";
CM_ SG_ 2566834939 OcC_01_CM4_SAE "OcC 01";
CM_ SG_ 2566834939 CM_01_CM4_SAE "CM 01";
CM_ SG_ 2566834939 SPN_02_CM4_SAE "SPN 02";
CM_ SG_ 2566834939 malfunctionIndicatorLamp_CM4_SAE "Malfunction Indicator Lamp (MIL)";
CM_ SG_ 2566834939 FMI_02_CM4_SAE "FM1 02";
CM_ SG_ 2566834939 SPN_high_reserved02_CM4_SAE "SPN High Reserved 02";
CM_ SG_ 2566834939 OcC_02_CM4_SAE "OcC 02";
CM_ SG_ 2566834939 CM_02_CM4_SAE "CM 02";
CM_ SG_ 2566834939 flashProtectLampStatus_CM4_SAE "Flash PL";
CM_ SG_ 2566834939 SPN_03_CM4_SAE "SPN 03";
CM_ SG_ 2566834939 FMI_03_CM4_SAE "FM1 03";
CM_ BO_ 2566535765 "Electric PTO Drive Engagement 1 Variant for BodyBuilder transmitting msg id FA3A55";
CM_ SG_ 2566535765 ePTODE1_CRC_BASE "Note: This uses boilerplate that is intended to be revised in 3Q2022.";
CM_ SG_ 2566535765 enableSwitchePTO1_BASE "Status of the operator's switch or other input on vehicle which indicates the desire for activating or engaging the ePTO equipment";
CM_ SG_ 2566535765 engageConsent_ePTO1_BASE "Indicates equipment controller's consent to activate or engage the high voltage ePTO. The vehicle controller may only apply high voltage to ePTO equipment when consent is given. Removal of consent initiates normal power down. Lack of consent may indicat";
CM_ SG_ 2566535765 engageStatus_ePTO1_BASE "Indicates whether electric power is applied to the ePTO equipment.";
CM_ SG_ 2566535765 emrgncyDeenSw_ePTO1_BASE "Initiates emergency shutdown procedure as appropriate to the application, which may include active discharge of ePTO bus.";
CM_ SG_ 2566535765 systemRdnss_ePTO1_BASE "Indicates availability of the power source to energize ePTO equipment or operational readiness of ePTO equipment to be energized";
CM_ SG_ 2566535765 errorIndicator_ePTO1_BASE "Signal to the operator that some ePTO error exists, such as failed to activate when requested";
CM_ SG_ 2566535765 activeDischargeRequest_ePTO1_BAS "active discharge requests";
CM_ SG_ 2566535765 ePTODE1_Count_BASE "The message counter is used to detect situations where the transmitting ECU malfunction repeats the same frame all the time. The receiver of the information may use the counter parameter to detect this situation. The transmitting device will increase the ";
CM_ BO_ 2566896981 "body builder Control 1 message - Safety  data ID: 165 233 133 4 251 108 223 241 222 144 168 203 221 59 128 135";
CM_ SG_ 2566896981 ASP2_CRC8_BASE "CRC8 Autosar Profile 2 with Data ID";
CM_ SG_ 2566896981 bobuWiperFrontReq_BASE "external wiper front request";
CM_ SG_ 2566896981 bobuFlashLightReq_BASE "The signal includes the request of the flashlight by the bodybuilder.";
CM_ SG_ 2566896981 rightTurnSignalLightsCmd_BASE "Command to activate or de-activate right turn signal lights on the tractor and all connected implements";
CM_ SG_ 2566896981 leftTurnSignalLightsCmd_BASE "Command to activate or de-activate left turn signal lights on the tractor and all connected implements";
CM_ SG_ 2566896981 haltBrakeSwitch_BASIS "Switch signal which indicates the position of the halt brake switch.";
CM_ SG_ 2566896981 parkBrkAppReqBB_BASE "External request to engage the electric parking brake";
CM_ SG_ 2566896981 parkBrkRlsReqBB_BASE "External request to release the electric parking brake";
CM_ SG_ 2566896981 parkBrkRlsInhibitBB_BASE "External requirement to prevent release of the electric parking brake";
CM_ SG_ 2566896981 bobuAlarmDriveLvl_BASE "alarm drive level for fire fighting trucks by body builder";
CM_ SG_ 2566896981 ASP2__cnt_BASE "Cnt Autosar Profile 2";
CM_ BO_ 2566897041 "body builder Control 1 message - Safety  data ID: 131 15 183 45 87 136 247 26 41 32 174 178 118 94 55 56";
CM_ SG_ 2566897041 ASP2_CRC8_BASE "CRC8 Autosar Profile 2 with Data ID";
CM_ SG_ 2566897041 bobuWiperFrontReq_BASE "external wiper front request";
CM_ SG_ 2566897041 bobuFlashLightReq_BASE "The signal includes the request of the flashlight by the bodybuilder.";
CM_ SG_ 2566897041 rightTurnSignalLightsCmd_BASE "Command to activate or de-activate right turn signal lights on the tractor and all connected implements";
CM_ SG_ 2566897041 leftTurnSignalLightsCmd_BASE "Command to activate or de-activate left turn signal lights on the tractor and all connected implements";
CM_ SG_ 2566897041 haltBrakeSwitch_BASIS "Switch signal which indicates the position of the halt brake switch.";
CM_ SG_ 2566897041 parkBrkAppReqBB_BASE "External request to engage the electric parking brake";
CM_ SG_ 2566897041 parkBrkRlsReqBB_BASE "External request to release the electric parking brake";
CM_ SG_ 2566897041 parkBrkRlsInhibitBB_BASE "External requirement to prevent release of the electric parking brake";
CM_ SG_ 2566897041 bobuAlarmDriveLvl_BASE "alarm drive level for fire fighting trucks by body builder";
CM_ SG_ 2566897041 ASP2__cnt_BASE "Cnt Autosar Profile 2";
CM_ BO_ 2566897040 "body builder Control 1 message - Safety  data ID: 142 58 204 83 10 138 122 100 185 90 47 137 126 23 149 183";
CM_ SG_ 2566897040 ASP2_CRC8_BASE "CRC8 Autosar Profile 2 with Data ID";
CM_ SG_ 2566897040 bobuWiperFrontReq_BASE "external wiper front request";
CM_ SG_ 2566897040 bobuFlashLightReq_BASE "The signal includes the request of the flashlight by the bodybuilder.";
CM_ SG_ 2566897040 rightTurnSignalLightsCmd_BASE "Command to activate or de-activate right turn signal lights on the tractor and all connected implements";
CM_ SG_ 2566897040 leftTurnSignalLightsCmd_BASE "Command to activate or de-activate left turn signal lights on the tractor and all connected implements";
CM_ SG_ 2566897040 haltBrakeSwitch_BASIS "Switch signal which indicates the position of the halt brake switch.";
CM_ SG_ 2566897040 parkBrkAppReqBB_BASE "External request to engage the electric parking brake";
CM_ SG_ 2566897040 parkBrkRlsReqBB_BASE "External request to release the electric parking brake";
CM_ SG_ 2566897040 parkBrkRlsInhibitBB_BASE "External requirement to prevent release of the electric parking brake";
CM_ SG_ 2566897040 bobuAlarmDriveLvl_BASE "alarm drive level for fire fighting trucks by body builder";
CM_ SG_ 2566897040 ASP2__cnt_BASE "Cnt Autosar Profile 2";
CM_ BO_ 2600454919 "CANMSG auxStatCM10";
CM_ SG_ 2600454919 dStmrMngmntDaysOTAreq_BASE "Data set for two timers containing the days the timer is valid provided as bitmask (0 = disabled; 1 = enabled) requested by the OTA backend.bit 0: Mondaybit 1: Tuesdaybit 2: Wednesday bit 3: Thursday bit 4: Friday bit 5: Saturday bit 6: Sunday";
CM_ SG_ 2600454919 dStmrMngmntTmrSettgsOTAreq_BASE "Data set for two timers containing the information about the timer settings provided as bitmask (0 = disabled; 1 = enabled) requested by the OTA backend. &#x0A;bit 0: charging timer &#x0A;bit 1: recurring &#x0A;bit 2: TES preconditioning &#x0A;bit 3: HVAC";
CM_ SG_ 2600454919 tmrMngmntTimerIndexOTAreq_BASE "Indicates for which of the up to seven timer the transferred information is related to.";
CM_ SG_ 2600454919 reqVehPrkChangeOTA_BASE "The signal describes the request for changing the stationary mode (auxiliary heating / parking cooling) from the OTA";
CM_ SG_ 2600454919 dStmrMngmntTrgtTimeOTAreq_BASE "Data set for two timers containing the target time of the timer in minutes calculated from 00:00 requested by the OTA backend.";
CM_ SG_ 2600454919 reqTempStageOTA_BASE "The signal describes the request for changing the setpoint temperature-level via OTA.";
CM_ SG_ 2600454919 reqTempOTA_BASE "The signal describes the request for the setpoint temperature changes via OTA.";
CM_ SG_ 2600454919 dStmrMngmntHoldDurOTAreq_BASE "Data set for two timers containing the holding duration of the timer requested by the OTA backend.";
CM_ BO_ 2566818901 "auxiliary Analog Information (used for urea sensor)";
CM_ SG_ 2566818901 auxiliaryTemperature1_BASIS "Auxiliary Temperature 1";
CM_ SG_ 2566818901 auxiliaryPressure1_BASIS "Auxiliary Pressure 1";
CM_ SG_ 2566818901 auxiliaryPressure2_BASIS "Auxiliary Pressure 2";
CM_ SG_ 2566818901 auxiliaryLevel_BASIS "Level measured by a sensor";
CM_ SG_ 2566818901 airHumidity_BASIS "air humidity";
CM_ SG_ 2566818901 auxiliaryTemperature3_BASIS "Auxiliary Temperature 3 (actual temperature refrigerated container)";
CM_ SG_ 2566818901 auxiliaryTemperature2_BASIS "Auxiliary temperature 2 (desired temperature refrigerated container)";
CM_ BO_ 2600454922 "CANMSG auxStatCM13";
CM_ SG_ 2600454922 auxStatCM13placeholder_BASE "Placeholder signal";
CM_ BO_ 2566845696 "Ambient Conditions";
CM_ SG_ 2566845696 barometricPressure_BASIS "Absolute air pressure of the atmosphere.";
CM_ SG_ 2566845696 ambientAirTemperature_BASIS "Temperature of air surrounding vehicle.";
CM_ SG_ 2566845696 cabInteriorTemperature_BASIS "Temperature of air inside the part of the vehicle that encloses the driver and vehicle operating controls.";
CM_ BO_ 2566847521 "CAN message dashDisplay.";
CM_ SG_ 2566847521 fuelLevel2_BASE "Ratio of volume of fuel to the total volume of fuel in the second or right-side storage container. When Fuel Level 2 is not used, Fuel Level 1 (SPN 96) represents the total fuel in all fuel storage containers.";
CM_ BO_ 2566831883 "EBC2";
CM_ SG_ 2566831883 frontAxleSpeed_BASIS "The average speed of the two front wheels. Comment: This signal are supposed to be used as a redudant signal to the ordinary vehicle speed for vehcile speeds in forward direction. The signal should detect errors in the ordinary vehicle speed signal.";
CM_ SG_ 2566831883 relatSpeedFrontAxleLeftWheel_BAS "The speed of the front axle, left wheel relative to the front axle speed, SPN 904.";
CM_ SG_ 2566831883 relatSpeedFrontAxleRightWheel_BA "The speed of the front axle, right wheel relative to the front axle speed, SPN 904.";
CM_ SG_ 2566831883 relatSpeedRearAxle1leftWheel_BAS "The speed of the rear axle #1, left wheel relative to the front axle speed, SPN 904.";
CM_ SG_ 2566831883 relatSpeedRearAxle1rightWheel_BA "The speed of the rear axle #1, right wheel relative to the front axle speed, SPN 904.";
CM_ SG_ 2566831883 relatSpeedRearAxle2leftWheel_BAS "The speed of the rear axle #2, left wheel relative to the front axle speed, SPN 904.";
CM_ SG_ 2566831883 relatSpeedRearAxle2rightWheel_BA "The speed of the rear axle #2, right wheel relative to the front axle speed, SPN 904.";
CM_ BO_ 2566767627 "Used for information on brake control.";
CM_ SG_ 2566767627 emergencyBrakingActive_BASE "Signal which indicates an emergency braking situation (ref. ECE Regulation 13 paragraph 5.2.1.31) with high deceleration values. This signal can be used to activate the hazard lights (ref ECE Regulation 48 paragraph 6.23) toindicate other road users to th";
CM_ SG_ 2566833352 vehicleABSactivePassive_T1_TO_TR "The current status of the anti-lock braking function or system. The signal shall be set active when the ABS starts to modulate the wheel brake pressure and shall be reset topassive when all wheels are in stable condition for a certain time period. The sig";
CM_ SG_ 2566833352 redWarningSignalRequest_T1_TO_TR "This signal commands the request from a towed vehicle to the commercial vehicle to activate the red warning signal, which indicates certain specified failures within the braking equipment of the towed vehicle.";
CM_ SG_ 2566833352 amberWarningSignalRequest_T1_TO_ "This signal ommands the request from a towed vehicle to the commercial vehicle to activate the amber warning signal, which indicates certain specified events within the braking equipment of the towed vehicle. A flashing warning signal can be used to signa";
CM_ SG_ 2566833352 electricalSupplyOfNonBrakingSyst "This signal indicates the current status of the supply voltage of non-braking systems.";
CM_ SG_ 2566833352 springBrakeInstalled_T1_TO_TRUCK "This signall indicates if the vehicle is equipped with one or more axles fitted with spring brakes.";
CM_ SG_ 2566833352 electrLoadProportionalFunc_T1_TO "This signal indicates if the vehicle is equipped with an electrical load proportional function.";
CM_ SG_ 2566833352 vehicleRetContrActivePassive_T1_ "The current status in all cases the retarder functionality is applied by the driver¿s demand or by other systems (e.g. brakes).";
CM_ SG_ 2566833352 vehicleType_T1_TO_TRUCK_EBS22 "The signal indicates if a vehicle is a converter dolly or a towing or towed vehicle.";
CM_ SG_ 2566833352 springBrakeEngaged_T1_TO_TRUCK "This signal indicates if the vehicle is equipped with one or more axles fitted with spring brakes.";
CM_ SG_ 2566833352 loadingRampApproachAssistance_T1 "This signall indicates if the vehicle is equipped with a load proportional function.";
CM_ SG_ 2566833352 supplylineBrakingRequest_T1_TO_T "The signal commands a request from the towed vehicle to be braked by the commercial vehicle by means of venting the pneumatic supply line.";
CM_ SG_ 2566833352 vehicleServiceBrakeActPass_T1_TO "This signal indicates the current status of the vehicle¿s service brake by observing the brake pressure.";
CM_ SG_ 2566833352 referenceRetarderTorque_T1_TO_TR "This signal indicates the 100 % reference value for all the specified indicated retarder torque parameters. It shall be specified only once and shall not change if a different retarder torque map becomes valid.";
CM_ SG_ 2566833352 automaticTowedVehicleBrake_T1_TO "Signal indicating the automatic towed vehicle braking is active/passive. This function will occur when the pneumatic supply is sufficient or not connected. This parameter should be used for driver information.";
CM_ SG_ 2566833352 vehicleElectricalSupply_T1_TO_TR "This signal indicates if the current status of the supply voltage is sufficient or insufficient for a proper braking function. This shall also include overvoltage conditions.";
CM_ BO_ 2566844160 "PGN which identifies parameters that are either measuring various pressures within the engine or identifying engine fluid levels";
CM_ BO_ 2566843904 "Engine Temperature";
CM_ SG_ 2566843904 engineCoolantTemperature_BASIS "Temperature of liquid found in engine cooling system.";
CM_ BO_ 2364539395 "Electronic Transmission Controller 1.";
CM_ SG_ 2364539395 drivelineEngaged_BASIS "Driveline engaged indicates the transmission controlled portion of the driveline is engaged sufficiently to allow a transfer of torque through the transmission. Driveline engaged is ACTIVE whenever the transmission is in gear and the clutch (if controlled";
CM_ SG_ 2364539395 kupplungsweg_BASIS "Relative Clutch Distance (not accoridng SAE); 0% is closed; SAE Signal:Requested Percent Clutch Slip";
CM_ SG_ 2364539395 engineMomentaryOverspeedEnable_B "Command signal used to indicate that the engine speed may be boosted up to the maximum engine overspeed value to accommodate transmission downshifts. The maximum time for overspeed is limited by the time defined in the engine configuration message (see PG";
CM_ SG_ 2364539395 shiftInProcess_BASIS "Indicates that the transmission is in process of shifting from the current gear to the selected gear. This state is generally ACTIVE during the entire time that the transmission controls the vehicle. This includes any transmission clutch control, all engi";
CM_ SG_ 2364539395 transmissionInputShaftSpeed_BASI "Rotational velocity of the primary shaft transferring power into the transmission. When a torque converter is present, it is the output of the torque converter.";
CM_ SG_ 2364539395 transmissionOutputShaftSpeed_BAS "Calculated speed of the transmission output shaft.";
CM_ BO_ 2365484270 "Tachograph";
CM_ SG_ 2365484270 directionIndicator_BASIS "Indicates the direction of the vehicle.";
CM_ SG_ 2365484270 tachographOutputShaftSpeed_BASIS "Calculated speed of the transmission output shaft.";
CM_ SG_ 2365484270 tachographVehicleSpeed_BASIS "Speed of the vehicle registered by the tachograph.";
CM_ SG_ 2365484270 driveRecognize_BASIS "Indicates whether motion of the vehicle is detected or not.";
CM_ SG_ 2566802471 OprtrsBlackOutIntnstySel_BASE "Operators Selection of lamp intensity in black out mode. This parameter provides the operators selected illumination intensity as a percentage of available full scale. This parameter would be typically used as a dash or instrument cluster intensity adjust";
CM_ SG_ 2566806728 tyreWheelIdentification_BASIS "It shall indicate the identification number of the tyre or wheel. The identification number shall specify the tyre or wheel position on each axle (bit 1 to bit 4) and the number of axles starting from the front of the respective towed vehicle (bit 5 to bi";
CM_ SG_ 2566806728 axleLoad_BASE "Static vertical load of a vehicle axle identified by tyre/wheel identification.";
CM_ BO_ 2565870375 "SAE Botschaft Slope Sensor Information 1000 ms  M-CAN";
CM_ BO_ 2566846467 "Transmission Fluids 1.";
CM_ SG_ 2566846467 transmissionOilTemperature_TCU "Temperature of the transmission lubricant.";
CM_ SG_ 2566846467 transmissionOilLevel_TCU "First instance of a transmission oil level indicator. Conveys the ratio of volume of transmission sump oil to recommended volume.";
CM_ BO_ 2566749489 "CAN Botschaft for Tell Tale Status Information  The Tell Tale Status information is derived from information displayed to the driver¿s dashboard. There are three possible conditions stated: Red (¿R¿), Yellow (¿Y¿), Info (¿I¿). The interpretation of the st";
CM_ SG_ 2566749489 tellTaleBlockID_BASE "Block ID of tellTaleStatus message";
CM_ SG_ 2566749489 tellTaleStatus03_BASE "tellTale status #3 according to FMS standard";
CM_ SG_ 2566749489 tellTaleStatus04_BASE "tellTale status #4 according to FMS standard";
CM_ SG_ 2566749489 tellTaleStatus05_BASE "tellTale status #5 according to FMS standard";
CM_ SG_ 2566749489 tellTaleStatus06_BASE "tellTale status #6 according to FMS standard";
CM_ SG_ 2566749489 tellTaleStatus07_BASE "tellTale status #7 according to FMS standard";
CM_ SG_ 2566749489 tellTaleStatus08_BASE "tellTale status #8 according to FMS standard";
CM_ SG_ 2566749489 tellTaleStatus09_BASE "tellTale status #9 according to FMS standard";
CM_ SG_ 2566749489 tellTaleStatus01_BASE "tellTale status #1 according to FMS standard";
CM_ SG_ 2566749489 tellTaleStatus10_BASE "tellTale status #10 according to FMS standard";
CM_ SG_ 2566749489 tellTaleStatus11_BASE "tellTale status #11 according to FMS standard";
CM_ SG_ 2566749489 tellTaleStatus12_BASE "tellTale status #12 according to FMS standard";
CM_ SG_ 2566749489 tellTaleStatus13_BASE "tellTale status #13 according to FMS standard";
CM_ SG_ 2566749489 tellTaleStatus14_BASE "tellTale status #14 according to FMS standard";
CM_ SG_ 2566749489 tellTaleStatus15_BASE "tellTale status #15 according to FMS standard";
CM_ SG_ 2566749489 tellTaleStatus02_BASE "tellTale status #2 according to FMS standard";
CM_ BO_ 2566613799 "High Voltage Bus Information PGN 64363";
CM_ SG_ 2566613799 highVtgBusEPTOAvlblty_BASE "This parameter indicates the availability of the high voltage bus to electric power take off components.";
CM_ BO_ 2365346087 "Used for suspension control information ASC7";
CM_ SG_ 2365346087 liftAxle1Status_BASE "Signal which indicates the status / load condition of lift axle / tag axle #1. Numbering of lift/tag axles starts at front axle.";
CM_ BO_ 2566767143 "Electronic Engine Controller 14";
CM_ SG_ 2566767143 fuelType_BASE "Type of fuel currently being utilized by the vehicle";
CM_ BO_ 2364641930 "Data set 2 (electrical data) for High Voltage Energy Storage Pack 1.";
CM_ SG_ 2364641930 HVESP1fastUpdateSOC_BASE "State of charge (SOC) of battery pack 1. SAE description: Indicates this High Voltage Energy Storage Pack instance state of charge. 0% means no charge remaining, 100% means the system is fully charged in terms of physical limits of this energy storage pac";
CM_ SG_ 2364641930 HVESP1HighestCellVoltage_BASE "Highest cell voltage in battery pack 1. SAE description: The highest voltage level reported by any cell in this High Voltage Energy Storage Pack instance.";
CM_ SG_ 2364641930 HVESP1lowestCellVoltage_BASE "lowest cell voltage in battery pack 1. SAE description: The lowest voltage level reported by any cell in this High Voltage Energy Storage Pack instance.";
CM_ BO_ 2364645770 "Data set 2 (electrical data) for High Voltage Energy Storage Pack 2.";
CM_ SG_ 2364645770 HVESP2fastUpdateSOC_BASE "State of charge (SOC) of battery pack 2. SAE description: Indicates this High Voltage Energy Storage Pack instance state of charge. 0% means no charge remaining, 100% means the system is fully charged in terms of physical limits of this energy storage pac";
CM_ SG_ 2364645770 HVESP2HighestCellVoltage_BASE "Highest cell voltage in battery pack 2. SAE description: The highest voltage level reported by any cell in this High Voltage Energy Storage Pack instance.";
CM_ SG_ 2364645770 HVESP2lowestCellVoltage_BASE "lowest cell voltage in battery pack 2. SAE description: The lowest voltage level reported by any cell in this High Voltage Energy Storage Pack instance.";
CM_ BO_ 2364649610 "Data set 2 (electrical data) for High Voltage Energy Storage Pack 3.";
CM_ SG_ 2364649610 HVESP3fastUpdateSOC_BASE "State of charge (SOC) of battery pack 3. SAE description: Indicates this High Voltage Energy Storage Pack instance state of charge. 0% means no charge remaining, 100% means the system is fully charged in terms of physical limits of this energy storage pac";
CM_ SG_ 2364649610 HVESP3HighestCellVoltage_BASE "Highest cell voltage in battery pack 3. SAE description: The highest voltage level reported by any cell in this High Voltage Energy Storage Pack instance.";
CM_ SG_ 2364649610 HVESP3lowestCellVoltage_BASE "lowest cell voltage in battery pack 3. SAE description: The lowest voltage level reported by any cell in this High Voltage Energy Storage Pack instance.";
CM_ BO_ 2364657290 "Data set 2 (electrical data) for High Voltage Energy Storage Pack 5.";
CM_ SG_ 2364657290 HVESP5fastUpdateSOC_BASE "State of charge (SOC) of battery pack 5. SAE description: Indicates this High Voltage Energy Storage Pack instance state of charge. 0% means no charge remaining, 100% means the system is fully charged in terms of physical limits of this energy storage pac";
CM_ SG_ 2364657290 HVESP5HighestCellVoltage_BASE "Highest cell voltage in battery pack 5. SAE description: The highest voltage level reported by any cell in this High Voltage Energy Storage Pack instance.";
CM_ SG_ 2364657290 HVESP5lowestCellVoltage_BASE "lowest cell voltage in battery pack 5. SAE description: The lowest voltage level reported by any cell in this High Voltage Energy Storage Pack instance.";
CM_ BO_ 2364675722 "Data set 2 (electrical data) for High Voltage Energy Storage Pack 7.";
CM_ SG_ 2364675722 HVESP7fastUpdateSOC_BASE "State of charge (SOC) of battery pack 7. SAE description: Indicates this High Voltage Energy Storage Pack instance state of charge. 0% means no charge remaining, 100% means the system is fully charged in terms of physical limits of this energy storage pac";
CM_ SG_ 2364675722 HVESP7HighestCellVoltage_BASE "Highest cell voltage in battery pack 1. SAE description: The highest voltage level reported by any cell in this High Voltage Energy Storage Pack instance.";
CM_ SG_ 2364675722 HVESP7lowestCellVoltage_BASE "lowest cell voltage in battery pack 7. SAE description: The lowest voltage level reported by any cell in this High Voltage Energy Storage Pack instance.";
CM_ BO_ 2364653450 "Data set 2 (electrical data) for High Voltage Energy Storage Pack 4.";
CM_ SG_ 2364653450 HVESP4fastUpdateSOC_BASE "State of charge (SOC) of battery pack 4. SAE description: Indicates this High Voltage Energy Storage Pack instance state of charge. 0% means no charge remaining, 100% means the system is fully charged in terms of physical limits of this energy storage pac";
CM_ SG_ 2364653450 HVESP4HighestCellVoltage_BASE "Highest cell voltage in battery pack 4. SAE description: The highest voltage level reported by any cell in this High Voltage Energy Storage Pack instance.";
CM_ SG_ 2364653450 HVESP4lowestCellVoltage_BASE "lowest cell voltage in battery pack 4. SAE description: The lowest voltage level reported by any cell in this High Voltage Energy Storage Pack instance.";
CM_ BO_ 2364679562 "Data set 2 (electrical data) for High Voltage Energy Storage Pack 8.";
CM_ SG_ 2364679562 HVESP8fastUpdateSOC_BASE "State of charge (SOC) of battery pack 8. SAE description: Indicates this High Voltage Energy Storage Pack instance state of charge. 0% means no charge remaining, 100% means the system is fully charged in terms of physical limits of this energy storage pac";
CM_ SG_ 2364679562 HVESP8HighestCellVoltage_BASE "Highest cell voltage in battery pack 8. SAE description: The highest voltage level reported by any cell in this High Voltage Energy Storage Pack instance.";
CM_ SG_ 2364679562 HVESP8lowestCellVoltage_BASE "lowest cell voltage in battery pack 8. SAE description: The lowest voltage level reported by any cell in this High Voltage Energy Storage Pack instance.";
CM_ BO_ 2364661130 "Data set 2 (electrical data) for High Voltage Energy Storage Pack 6.";
CM_ SG_ 2364661130 HVESP6fastUpdateSOC_BASE "State of charge (SOC) of battery pack 6. SAE description: Indicates this High Voltage Energy Storage Pack instance state of charge. 0% means no charge remaining, 100% means the system is fully charged in terms of physical limits of this energy storage pac";
CM_ SG_ 2364661130 HVESP6HighestCellVoltage_BASE "Highest cell voltage in battery pack 6. SAE description: The highest voltage level reported by any cell in this High Voltage Energy Storage Pack instance.";
CM_ SG_ 2364661130 HVESP6lowestCellVoltage_BASE "lowest cell voltage in battery pack 6. SAE description: The lowest voltage level reported by any cell in this High Voltage Energy Storage Pack instance.";
CM_ BO_ 2566840592 "This map describes the stationary behavior of the retarder.";
CM_ SG_ 2566840592 retarderType_RD "A vehicle retarder is a supplementary device to the wheel brakes for the driver to better control the vehicle. The wheel brakes used in the vehicle are not designed for continuous retarding operation. In a prolonged period of braking, the brakes can be th";
CM_ SG_ 2566840592 percentTorqueAtPoint4_RD "The torque limit that indicates the available retarder torque which can be provided by the retarder at points 3 and 4 of the retarder torque map. Please reference PGN 65249. The data is transmitted in indicated torque as a percent of the reference retarde";
CM_ SG_ 2566840592 retarderSpeedAtPeakTorqPoint5_RD "Please reference PGN 65249";
CM_ SG_ 2566840592 referenceRetarderTorque_RD "This parameter is the 100% reference value for all defined indicated retarder torque parameters. It is only defined once and doesn't change if a different retarder torque map becomes valid.";
CM_ SG_ 2566840592 percentTorqAtPeakTorqPoint5_RD "The torque limit that indicates the available retarder torque which can be provided by the retarder at point 5 of the retarder torque map. Please reference PGN 65249. The data is transmitted in indicated torque as a percent of the reference retarder torqu";
CM_ SG_ 2566840592 retarderSpeedAtIdlePoint1_RD "Please reference PGN 65249";
CM_ SG_ 2566840592 percentTorqueAtIdlePoint1_RD "The torque limit that indicates the available retarder torque which can be provided by the retarder at idle speed. The data is transmitted in indicated torque as a percent of the reference retarder torque. Please reference PGN 65249.";
CM_ SG_ 2566840592 retarderLocation_RD "This parameter defines whether the ¿torque/speed curve¿ defined by the retarder configuration message (PGN 65249) is dependent on engine rpm, output shaft rpm, or other parameter.";
CM_ SG_ 2566840592 maximumRetarderSpeedPoint2_RD "Maximum speed of retarder (Please reference PGN 65249).";
CM_ SG_ 2566840592 percentTorqueAtMaxSpeedPoint2_RD "The torque limit that indicates the available retarder torque which can be provided by the retarder at its maximum speed. Please reference PGN 65249. The data is transmitted in indicated torque as a percent of the reference retarder torque.";
CM_ SG_ 2566840592 retarderSpeedAtPoint3_RD "Retarder speed of point 3 of the engine retarder torque map. Please reference PGN 65249.";
CM_ SG_ 2566840592 retarderControlMethod_RD "This parameter identifies the number of steps used by the retarder.";
CM_ SG_ 2566840592 percentTorqueAtPoint3_RD "The torque limit that indicates the available retarder torque which can be provided by the retarder at points 3 and 4 of the retarder torque map. Please reference PGN 65249. The data is transmitted in indicated torque as a percent of the reference retarde";
CM_ SG_ 2566840592 retarderSpeedAtPoint4_RD "Retarder speed of point 4 of the engine retarder torque map. Please reference PGN 65249.";
CM_ BO_ 2566847248 "Retarder fluids.";
CM_ SG_ 2566847248 drivelineRetOverheatIndicator_RD "Signal from the driveline retarder indicating that its fluid temperature is above normal acceptable limits, and as a result, retarder operation may be altered or restricted. The indicator is typically a lamp. Distinctions in meaning between the continuous";
CM_ SG_ 2566847248 hydraulicOilTemperature_RD "Temperature of oil found in a hydraulic retarder.";
CM_ BO_ 2566698791 "Vehicle Electrical Power #4";
CM_ SG_ 2566698791 hybridBatPackRemCharge_BASE "Indicates the hybrid battery pack remaining charge. 0% means no charge remaining, 100% means full charge remaining.";
CM_ BO_ 2566545546 "CANMSG EVDCCIP PG description Optional information on the present charge cycle that may be sent to the EVSE from the EV for display purposes";
CM_ SG_ 2566545546 EVfullChargeTimeRemaining_BASE "Remaining time to complete full charging. (SAE signal - CANMSG EVDCCIP)";
CM_ BO_ 2600407299 "prop. message for the transmission of customer-specific signals";
CM_ SG_ 2600407299 maxCustEnergyTES_BASE "The maximum possible Traction Energy Storage (TES) energy that is usable by the customer.";
CM_ SG_ 2600407299 activationStateHVHTES_BASE "Indicates if the HVH (High Voltage Heater) is activated or not.";
CM_ SG_ 2600407299 activationStateCoolSysTES_BASE "Indicates if the installed cooling system /device is activated or not.";
CM_ BO_ 2600407300 "prop. message for the transmission of customer-specific signals";
CM_ SG_ 2600407300 totalEnergyConsumption_BASE "overall energy consumption over the vehicle life";
CM_ SG_ 2600407300 HVESSintakeCoolantTemp_BASE "The temperature of liquid coolant as it enters the High Voltage Energy Storage System (or Pack 1 in systems with only one pack). SAE signal";
CM_ SG_ 2600407300 drvSysActv_BASE "The signal describes whether the drive system is ready for operation.";
CM_ BO_ 2600407297 "prop. message for the transmission of customer-specific signals";
CM_ SG_ 2600407297 HVESSstateOfHealth_BASE "This signal represents the expected remaining Life of the High Voltage Energy Storage System in percent. 100% Begin of Life 0% End of Life SAE-SPN: 8121";
CM_ SG_ 2600407297 HVESSmaxPackSOC_BASE "State of charge (SOC) of the highest charged pack of the complete high-voltage battery system.";
CM_ SG_ 2600407297 HVESSminPackSOC_BASE "State of charge (SOC) of the lowest charged pack of the complete high-voltage battery system.";
CM_ BO_ 2600407301 "prop. message for the transmission of customer-specific signals";
CM_ SG_ 2600407301 reqInsideTemp1_BASE "Requested inside temperature in a solobus or in the rear of the vehicle of an articulated bus.";
CM_ SG_ 2600407301 reqInsideTemp2_BASE "Requested inside temperature in the front of the vehicle of an articulated bus.";
CM_ BO_ 2565903754 "CANMSG HVESSD6 PGN description Data set 6 (external or interface data) for High Voltage Energy Storage System (or Pack 1 in systems with only one pack).";
CM_ SG_ 2565903754 HVESSintakeCoolantTemp_BASE "The temperature of liquid coolant as it enters the High Voltage Energy Storage System (or Pack 1 in systems with only one pack). SAE signal";
CM_ SG_ 2565903754 HVESStemperature_BASE "The temperature of High Voltage Energy Storage System (or Pack 1 in systems with only one pack). The value may be determined from a unique sensor specifically for this purpose, or by aggregating various temperature sensor readings within the system.";
CM_ SG_ 2566866977 lightSwitchReason_BASE "This signal indicates which ambient conditions have been detected by the light sensor";
CM_ SG_ 2566771850 oprtnKeySwIgnPow_BASE "Indicates that the ignition state of the operator key switch is active. SAE-SPN: 10145";
CM_ SG_ 2364610442 lowSidePowerDCDC_BASE "Indicates the measured SLI battery or low side power measured at the DC/DC Converter. The low side power is positive if the converter is charging the SLI battery from the HV battery (i.e. Buck Mode). The low side power is negative if the converter is char";
CM_ SG_ 2364579978 HVESSdischgEnCpcty_BASE "The amount of stored electrical energy in High Voltage Energy Storage System (or Pack 1 in systems with only one pack)";
CM_ BO_ 2566842094 "Time/Date";
CM_ SG_ 2566842094 seconds_BASIS "The seconds component of the current time of day.";
CM_ SG_ 2566842094 hours_BASIS "The hour component of the current time of day.";
CM_ SG_ 2566842094 month_BASIS "The month component of the current calendar date.";
CM_ SG_ 2566842094 day_BASIS "The day component of the current calendar date.";
CM_ SG_ 2566842094 year_BASIS "The year component of the current calendar date.";
CM_ SG_ 2566842094 localMinuteOffset_BASIS "The minute component of the offset between the UTC time and date and a local time zone time and date.";
CM_ SG_ 2566842094 localHourOffset_BASIS "The hour component of the offset between the UTC (Universal Time Coordinate) time and date and a local time zone time and date.";
CM_ SG_ 2566842094 minutes_BASIS "The minutes component of the current time of day.";
CM_ BO_ 2583638092 "proprietary CAN message appControlInterface / VAR1 Variant for MMT3  This OnEvent CAN message must not be sent faster than every 100ms.";
CM_ SG_ 2583638092 appFrameworkAppID_BASE "ID of an specific App. 0 is not an valid AppID (default value).";
CM_ SG_ 2583638092 appFrameworkAppState_BASE "State of an specific App.";
CM_ SG_ 2600422183 infoEmgcyShutOff_BASE "Signal contains information as to whether the battery emergency off was requested or not.";
CM_ SG_ 2600422183 egyModeHVAC_BASE "currently required energy mode of the HVAC";
CM_ SG_ 2600422183 CVM13cntE2E_BASE "counter of end-to-end communication protection The counter prevents other ECUs from reacting to a faulty transmission of the PGN and serves as a safety mechanism. The counter is being incremented by 1 for every sent message, starting with 0. (0 follows ";
CM_ SG_ 2600422183 CVM13chkE2E_BASE "checksum of end-to-end communication protection The checksum is used to verify the signal path from the CVM2-ECU to other ECUs.The 4 bit checksum is the sum of the high nibble and the low nibble of the sum of the identifier, the first 7 data bytes and the";
CM_ BO_ 2600460311 "Proprietary message RTinst1 for requests of remote tester texts according to SOA concept and ServiceSpec_RemoteTesterFeatureList";
CM_ SG_ 2600460311 rmtTstrInstallMsgHeaderReq_BASE "Request header according to service specification RemoteTesterFeatureList Please refer also to: Service Specification for RemoteTesterFeatureList (ServiceSpec_RemoteTesterFeatureList.pdf)";
CM_ SG_ 2600460311 rmtTstrInstallJobIdReq_BASE "RemoteTester JobId contained in the request of the RemoteTesterFeatureList client. Used in the following requests: RemoteTesterFeatureList_GetJobId.jobId: Corresponding status signal must be set to not available in this request because the job ID is not";
CM_ SG_ 2600460311 rmtTstrInstallListIdxReq_BASE "RemoteTester list index contained in the request of the RemoteTesterFeatureList client.Used in the following requests: RemoteTesterFeatureList_GetJobId.listIndex: Index of an element in the list of remote tester jobs. RemoteTesterFeatureList_GetTitles.lis";
CM_ SG_ 2600462375 selectedLanguage_BASE "This signal contains the selected language in the vehicle.";
CM_ BO_ 2364547840 "This message contains SCR dosing system information for aftertreatment system 1 (or bank 1). See PGN 64833 for more information. (MAN proprietary, as cycle is set to 5000 ms)";
CM_ BO_ 2566832622 "High Resolution Vehicle Distance.";
CM_ SG_ 2566832622 highResolutionTotalVehDistance_B "Accumulated distance traveled by the vehicle during its operation.";
CM_ SG_ 2566832622 highResolutionTripDistance_BASIS "Distance traveled during all or part of a journey.";
CM_ BO_ 2364642442 "Data set 4 (electrical data) for High Voltage Energy Storage Pack 1.";
CM_ SG_ 2364642442 HVESP1dischargeCapacity_BASE "Discharge capacity of battery pack 1. SAE description: The amount of stored electrical charge in this High Voltage Energy Storage Pack instance that is available for use by the hybrid system, i.e. how full is the tank.";
CM_ BO_ 2364646282 "Data set 4 (electrical data) for High Voltage Energy Storage Pack 2.";
CM_ SG_ 2364646282 HVESP2dischargeCapacity_BASE "Discharge capacity of battery pack 2. SAE description: The amount of stored electrical charge in this High Voltage Energy Storage Pack instance that is available for use by the hybrid system, i.e. how full is the tank.";
CM_ BO_ 2364650122 "Data set 4 (electrical data) for High Voltage Energy Storage Pack 3.";
CM_ SG_ 2364650122 HVESP3dischargeCapacity_BASE "Discharge capacity of battery pack 3. SAE description: The amount of stored electrical charge in this High Voltage Energy Storage Pack instance that is available for use by the hybrid system, i.e. how full is the tank.";
CM_ BO_ 2364661642 "Data set 4 (electrical data) for High Voltage Energy Storage Pack 6.";
CM_ SG_ 2364661642 HVESP6dischargeCapacity_BASE "Discharge capacity of battery pack 6. SAE description: The amount of stored electrical charge in this High Voltage Energy Storage Pack instance that is available for use by the hybrid system, i.e. how full is the tank.";
CM_ BO_ 2364653962 "Data set 4 (electrical data) for High Voltage Energy Storage Pack 4.";
CM_ SG_ 2364653962 HVESP4dischargeCapacity_BASE "Discharge capacity of battery pack 4. SAE description: The amount of stored electrical charge in this High Voltage Energy Storage Pack instance that is available for use by the hybrid system, i.e. how full is the tank.";
CM_ BO_ 2364657802 "Data set 4 (electrical data) for High Voltage Energy Storage Pack 5.";
CM_ SG_ 2364657802 HVESP5dischargeCapacity_BASE "Discharge capacity of battery pack 5. SAE description: The amount of stored electrical charge in this High Voltage Energy Storage Pack instance that is available for use by the hybrid system, i.e. how full is the tank.";
CM_ BO_ 2364676234 "Data set 4 (electrical data) for High Voltage Energy Storage Pack 7.";
CM_ SG_ 2364676234 HVESP7dischargeCapacity_BASE "Discharge capacity of battery pack 7. SAE description: The amount of stored electrical charge in this High Voltage Energy Storage Pack instance that is available for use by the hybrid system, i.e. how full is the tank.";
CM_ BO_ 2364680074 "Data set 4 (electrical data) for High Voltage Energy Storage Pack 8.";
CM_ SG_ 2364680074 HVESP8dischargeCapacity_BASE "Discharge capacity of battery pack 8. SAE description: The amount of stored electrical charge in this High Voltage Energy Storage Pack instance that is available for use by the hybrid system, i.e. how full is the tank.";
CM_ BO_ 2566876928 "proprietary message containing information about homologation relevant vehicle dimensions";
CM_ SG_ 2566876928 bodyLength_BASE "Homologation relevant length of the vehicle";
CM_ SG_ 2566876928 bodyWidth_BASE "Homologation relevant width of the vehicle";
CM_ SG_ 2566876928 bodyHeight_BASE "Homologation relevant height of the vehicle";
CM_ SG_ 2566876928 passengerCapacity_BASE "Homologation relevant maximum number of passengers that can fit in the vehicle.";
CM_ SG_ 2600455183 BattPack4ActTemp_BASE "Actual battery temperature on pack-level";
CM_ SG_ 2600455183 BattPack4Curr_BASE "Actual battery current on Pack-level";
CM_ SG_ 2600455183 BattPack4TechSoC_BASE "Actual technical SoC on Pack-level";
CM_ SG_ 2600455173 BattPack2InterResistDisch_BASE "internal resistance discharge on Pack-level";
CM_ SG_ 2600455173 BattPack2InterResistCh_BASE "internal resistance charge on Pack-level";
CM_ SG_ 2600455173 BattPack2MaxTheorEnergy_BASE "Maximum theoretical energy on Pack-level";
CM_ SG_ 2600455173 BattPack2Vltg_BASE "Actual battery voltage on Pack-level";
CM_ SG_ 2600455173 BattPack2ActState_BASE "Actual battery State on Pack-level";
CM_ SG_ 2600455181 BattPack2ActTemp_BASE "Actual battery temperature on pack-level";
CM_ SG_ 2600455181 BattPack2Curr_BASE "Actual battery current on Pack-level";
CM_ SG_ 2600455181 BattPack2TechSoC_BASE "Actual technical SoC on Pack-level";
CM_ SG_ 2600455177 BattPack6InterResistDisch_BASE "internal resistance discharge on Pack-level";
CM_ SG_ 2600455177 BattPack6InterResistCh_BASE "internal resistance charge on Pack-level";
CM_ SG_ 2600455177 BattPack6MaxTheorEnergy_BASE "Maximum theoretical energy on Pack-level";
CM_ SG_ 2600455177 BattPack6Vltg_BASE "Actual battery voltage on Pack-level";
CM_ SG_ 2600455177 BattPack6ActState_BASE "Actual battery State on Pack-level";
CM_ SG_ 2600455185 BattPack6ActTemp_BASE "Actual battery temperature on pack-level";
CM_ SG_ 2600455185 BattPack6Curr_BASE "Actual battery current on Pack-level";
CM_ SG_ 2600455185 BattPack6TechSoC_BASE "Actual technical SoC on Pack-level";
CM_ SG_ 2600455172 BattPack1InterResistDisch_BASE "internal resistance discharge on Pack-level";
CM_ SG_ 2600455172 BattPack1InterResistCh_BASE "internal resistance charge on Pack-level";
CM_ SG_ 2600455172 BattPack1MaxTheorEnergy_BASE "Maximum theoretical energy on Pack-level";
CM_ SG_ 2600455172 BattPack1Vltg_BASE "Actual battery voltage on Pack-level";
CM_ SG_ 2600455172 BattPack1ActState_BASE "Actual battery State on Pack-level";
CM_ SG_ 2600455182 BattPack3ActTemp_BASE "Actual battery temperature on pack-level";
CM_ SG_ 2600455182 BattPack3Curr_BASE "Actual battery current on Pack-level";
CM_ SG_ 2600455182 BattPack3TechSoC_BASE "Actual technical SoC on Pack-level";
CM_ SG_ 2600455179 BattPack8InterResistDisch_BASE "internal resistance discharge on Pack-level";
CM_ SG_ 2600455179 BattPack8InterResistCh_BASE "internal resistance charge on Pack-level";
CM_ SG_ 2600455179 BattPack8MaxTheorEnergy_BASE "Maximum theoretical energy on Pack-level";
CM_ SG_ 2600455179 BattPack8Vltg_BASE "Actual battery voltage on Pack-level";
CM_ SG_ 2600455179 BattPack8ActState_BASE "Actual battery State on Pack-level";
CM_ SG_ 2600455178 BattPack7InterResistDisch_BASE "internal resistance discharge on Pack-level";
CM_ SG_ 2600455178 BattPack7InterResistCh_BASE "internal resistance charge on Pack-level";
CM_ SG_ 2600455178 BattPack7MaxTheorEnergy_BASE "Maximum theoretical energy on Pack-level";
CM_ SG_ 2600455178 BattPack7Vltg_BASE "Actual battery voltage on Pack-level";
CM_ SG_ 2600455178 BattPack7ActState_BASE "Actual battery State on Pack-level";
CM_ SG_ 2600455176 BattPack5InterResistDisch_BASE "internal resistance discharge on Pack-level";
CM_ SG_ 2600455176 BattPack5InterResistCh_BASE "internal resistance charge on Pack-level";
CM_ SG_ 2600455176 BattPack5MaxTheorEnergy_BASE "Maximum theoretical energy on Pack-level";
CM_ SG_ 2600455176 BattPack5Vltg_BASE "Actual battery voltage on Pack-level";
CM_ SG_ 2600455176 BattPack5ActState_BASE "Actual battery State on Pack-level";
CM_ SG_ 2600455180 BattPack1ActTemp_BASE "Actual battery temperature on pack-level";
CM_ SG_ 2600455180 BattPack1Curr_BASE "Actual battery current on Pack-level";
CM_ SG_ 2600455180 BattPack1TechSoC_BASE "Actual technical SoC on Pack-level";
CM_ SG_ 2600455186 BattPack7ActTemp_BASE "Actual battery temperature on pack-level";
CM_ SG_ 2600455186 BattPack7Curr_BASE "Actual battery current on Pack-level";
CM_ SG_ 2600455186 BattPack7TechSoC_BASE "Actual technical SoC on Pack-level";
CM_ SG_ 2600455171 stateMultiTES_BASE "Indicates the number of connected Single-TES relating to the number of Single-TES in the Multi-TES System";
CM_ SG_ 2600455184 BattPack5ActTemp_BASE "Actual battery temperature on pack-level";
CM_ SG_ 2600455184 BattPack5Curr_BASE "Actual battery current on Pack-level";
CM_ SG_ 2600455184 BattPack5TechSoC_BASE "Actual technical SoC on Pack-level";
CM_ SG_ 2600455175 BattPack4InterResistDisch_BASE "internal resistance discharge on Pack-level";
CM_ SG_ 2600455175 BattPack4InterResistCh_BASE "internal resistance charge on Pack-level";
CM_ SG_ 2600455175 BattPack4MaxTheorEnergy_BASE "Maximum theoretical energy on Pack-level";
CM_ SG_ 2600455175 BattPack4Vltg_BASE "Actual battery voltage on Pack-level";
CM_ SG_ 2600455175 BattPack4ActState_BASE "Actual battery State on Pack-level";
CM_ SG_ 2600455187 BattPack8ActTemp_BASE "Actual battery temperature on pack-level";
CM_ SG_ 2600455187 BattPack8Curr_BASE "Actual battery current on Pack-level";
CM_ SG_ 2600455187 BattPack8TechSoC_BASE "Actual technical SoC on Pack-level";
CM_ SG_ 2600455174 BattPack3InterResistDisch_BASE "internal resistance discharge on Pack-level";
CM_ SG_ 2600455174 BattPack3InterResistCh_BASE "internal resistance charge on Pack-level";
CM_ SG_ 2600455174 BattPack3MaxTheorEnergy_BASE "Maximum theoretical energy on Pack-level";
CM_ SG_ 2600455174 BattPack3Vltg_BASE "Actual battery voltage on Pack-level";
CM_ SG_ 2600455174 BattPack3ActState_BASE "Actual battery State on Pack-level";
BA_DEF_ SG_  "SigType" ENUM  "DEFAULT","RANGE","RANGESIGNED","ASCII","DISCRETE","CONTROL","REFERENCEPGN","DTC","STRINGDELIMITER","STRINGLENGTH","STRINGLENGTHCONTROL","vector_leerstring";
BA_DEF_ SG_  "GenSigSendType" ENUM  "Cyclic","OnWrite","reserved","OnChange","reserved","reserved","reserved","NoSigSendType";
BA_DEF_ BO_  "VFrameFormat" ENUM  "CAN Standard","CAN Extended","reserved","J1939PG","reserved","reserved","reserved","reserved","reserved","reserved","reserved","reserved","reserved","reserved","StandardCAN_FD","ExtendedCAN_FD","vector_leerstring";
BA_DEF_ BO_  "GenMsgSendType" ENUM  "cyclic","reserved","cyclicIfActive","reserved","reserved","reserved","reserved","reserved","noMsgSendType","vector_leerstring";
BA_DEF_ BO_  "GenMsgCycleTime" INT 0 3600000;
BA_DEF_ BO_  "GenMsgStartDelayTime" INT 0 0;
BA_DEF_ BO_  "GenMsgILSupport" ENUM  "No","Yes","vector_leerstring";
BA_DEF_ SG_  "SystemSignalLongSymbol" STRING ;
BA_DEF_ BO_  "SystemMessageLongSymbol" STRING ;
BA_DEF_DEF_  "SigType" "DEFAULT";
BA_DEF_DEF_  "VFrameFormat" "CAN Extended";
BA_DEF_DEF_  "GenMsgSendType" "noMsgSendType";
BA_DEF_DEF_  "GenMsgCycleTime" 1000;
BA_DEF_DEF_  "GenMsgStartDelayTime" 0;
BA_DEF_DEF_  "GenMsgILSupport" "Yes";
BA_DEF_DEF_  "SystemSignalLongSymbol" "";
BA_DEF_DEF_  "GenSigSendType" "NoSigSendType";

BA_ "GenMsgILSupport" BO_ 2600460568 0;
BA_ "VFrameFormat" BO_ 2600460568 3;

BA_ "GenMsgILSupport" BO_ 2566834939 0;
BA_ "VFrameFormat" BO_ 2566834939 3;

BA_ "GenMsgILSupport" BO_ 2566535765 0;
BA_ "GenMsgSendType" BO_ 2566535765 0;
BA_ "GenMsgCycleTime" BO_ 2566535765 100;

BA_ "GenMsgILSupport" BO_ 2566896981 0;
BA_ "GenMsgSendType" BO_ 2566896981 0;
BA_ "GenMsgCycleTime" BO_ 2566896981 100;

BA_ "GenMsgILSupport" BO_ 2566897041 0;
BA_ "GenMsgSendType" BO_ 2566897041 0;
BA_ "GenMsgCycleTime" BO_ 2566897041 100;

BA_ "GenMsgILSupport" BO_ 2566897040 0;
BA_ "GenMsgSendType" BO_ 2566897040 0;
BA_ "GenMsgCycleTime" BO_ 2566897040 100;

BA_ "GenMsgILSupport" BO_ 2600454919 0;
BA_ "GenMsgSendType" BO_ 2600454919 0;
BA_ "VFrameFormat" BO_ 2600454919 3;

BA_ "GenMsgILSupport" BO_ 2566818901 0;
BA_ "GenMsgSendType" BO_ 2566818901 0;

BA_ "GenMsgILSupport" BO_ 2600454922 0;
BA_ "GenMsgSendType" BO_ 2600454922 0;
BA_ "GenMsgCycleTime" BO_ 2600454922 10000;
BA_ "VFrameFormat" BO_ 2600454922 3;

BA_ "GenMsgSendType" BO_ 2566845696 0;
BA_ "GenMsgStartDelayTime" BO_ 2566845696 30;

BA_ "GenMsgSendType" BO_ 2566805807 0;
BA_ "GenMsgCycleTime" BO_ 2566805807 100;

BA_ "GenMsgSendType" BO_ 2566838781 0;

BA_ "GenMsgILSupport" BO_ 2563833623 0;
BA_ "GenMsgCycleTime" BO_ 2563833623 5000;

BA_ "GenMsgSendType" BO_ 2566843687 0;
BA_ "GenMsgStartDelayTime" BO_ 2566843687 40;
BA_ "SystemMessageLongSymbol" BO_ 2566843687 "cruiseControlVehicleSpeedSetup_VAR1";
BA_ "GenMsgSendType" BO_ 2566847521 0;

BA_ "GenMsgSendType" BO_ 2566759916 0;
BA_ "GenMsgCycleTime" BO_ 2566759916 100;

BA_ "GenMsgILSupport" BO_ 2566810606 0;
BA_ "GenMsgSendType" BO_ 2566810606 0;
BA_ "GenMsgCycleTime" BO_ 2566810606 10000;
BA_ "VFrameFormat" BO_ 2566810606 3;

BA_ "GenMsgSendType" BO_ 2566831883 0;
BA_ "GenMsgCycleTime" BO_ 2566831883 20;

BA_ "GenMsgSendType" BO_ 2566767627 0;
BA_ "GenMsgCycleTime" BO_ 2566767627 100;

BA_ "GenMsgSendType" BO_ 2566833352 0;
BA_ "GenMsgCycleTime" BO_ 2566833352 100;

BA_ "GenMsgSendType" BO_ 2566844160 0;
BA_ "GenMsgCycleTime" BO_ 2566844160 500;
BA_ "GenMsgStartDelayTime" BO_ 2566844160 10;

BA_ "GenMsgSendType" BO_ 2566841639 0;
BA_ "GenMsgStartDelayTime" BO_ 2566841639 60;

BA_ "GenMsgSendType" BO_ 2566843904 0;
BA_ "GenMsgStartDelayTime" BO_ 2566843904 70;

BA_ "GenMsgSendType" BO_ 2364539395 0;
BA_ "GenMsgCycleTime" BO_ 2364539395 10;

BA_ "GenMsgSendType" BO_ 2633880061 0;
BA_ "GenMsgCycleTime" BO_ 2633880061 10000;
BA_ "SystemMessageLongSymbol" BO_ 2633880061 "FMSstandardInterfaceIdentity_BASE";
BA_ "GenMsgSendType" BO_ 2566842663 0;

BA_ "GenMsgSendType" BO_ 2566719744 0;
BA_ "SystemMessageLongSymbol" BO_ 2566719744 "highResolutionFuelConsumption_BASE";
BA_ "GenMsgSendType" BO_ 2566844967 0;
BA_ "GenMsgCycleTime" BO_ 2566844967 100;
BA_ "GenMsgStartDelayTime" BO_ 2566844967 80;

BA_ "GenMsgILSupport" BO_ 2365443111 0;
BA_ "SystemMessageLongSymbol" BO_ 2365443111 "operatorsExtLightControlsMessage_VAR2";
BA_ "GenMsgSendType" BO_ 2566805053 0;
BA_ "GenMsgStartDelayTime" BO_ 2566805053 10;

BA_ "GenMsgSendType" BO_ 2365484270 0;
BA_ "GenMsgCycleTime" BO_ 2365484270 50;

BA_ "GenMsgILSupport" BO_ 2566802471 0;
BA_ "GenMsgCycleTime" BO_ 2566802471 500;

BA_ "GenMsgSendType" BO_ 2566806728 0;
BA_ "GenMsgCycleTime" BO_ 2566806728 100;

BA_ "GenMsgSendType" BO_ 2565870375 0;

BA_ "GenMsgSendType" BO_ 2566846467 0;

BA_ "GenMsgSendType" BO_ 2566749489 0;
BA_ "VFrameFormat" BO_ 2566749489 3;

BA_ "GenMsgSendType" BO_ 2566803262 0;
BA_ "GenMsgCycleTime" BO_ 2566803262 100;

BA_ "GenMsgILSupport" BO_ 2566613799 0;

BA_ "GenMsgILSupport" BO_ 2365346087 0;
BA_ "GenMsgSendType" BO_ 2365346087 0;

BA_ "GenMsgSendType" BO_ 2566827275 0;
BA_ "GenMsgCycleTime" BO_ 2566827275 100;

BA_ "GenMsgSendType" BO_ 2566767143 0;
BA_ "GenMsgCycleTime" BO_ 2566767143 10000;

BA_ "GenMsgILSupport" BO_ 2364641930 0;
BA_ "GenMsgSendType" BO_ 2364641930 0;

BA_ "GenMsgILSupport" BO_ 2364645770 0;
BA_ "GenMsgSendType" BO_ 2364645770 0;

BA_ "GenMsgILSupport" BO_ 2364649610 0;
BA_ "GenMsgSendType" BO_ 2364649610 0;

BA_ "GenMsgILSupport" BO_ 2364657290 0;
BA_ "GenMsgSendType" BO_ 2364657290 0;

BA_ "GenMsgILSupport" BO_ 2364675722 0;
BA_ "GenMsgSendType" BO_ 2364675722 0;

BA_ "GenMsgILSupport" BO_ 2364653450 0;
BA_ "GenMsgSendType" BO_ 2364653450 0;

BA_ "GenMsgILSupport" BO_ 2364679562 0;
BA_ "GenMsgSendType" BO_ 2364679562 0;

BA_ "GenMsgILSupport" BO_ 2364661130 0;
BA_ "GenMsgSendType" BO_ 2364661130 0;

BA_ "GenMsgILSupport" BO_ 2566840592 0;
BA_ "GenMsgSendType" BO_ 2566840592 0;
BA_ "GenMsgCycleTime" BO_ 2566840592 5000;
BA_ "VFrameFormat" BO_ 2566840592 3;

BA_ "GenMsgSendType" BO_ 2566847248 0;

BA_ "GenMsgSendType" BO_ 2566698791 0;
BA_ "GenMsgCycleTime" BO_ 2566698791 10000;

BA_ "GenMsgILSupport" BO_ 2566545546 0;
BA_ "GenMsgSendType" BO_ 2566545546 0;

BA_ "GenMsgILSupport" BO_ 2600407299 0;
BA_ "GenMsgSendType" BO_ 2600407299 0;
BA_ "GenMsgCycleTime" BO_ 2600407299 10000;
BA_ "VFrameFormat" BO_ 2600407299 3;

BA_ "GenMsgILSupport" BO_ 2600407300 0;
BA_ "GenMsgSendType" BO_ 2600407300 0;
BA_ "VFrameFormat" BO_ 2600407300 3;

BA_ "GenMsgILSupport" BO_ 2600407297 0;
BA_ "GenMsgSendType" BO_ 2600407297 0;
BA_ "VFrameFormat" BO_ 2600407297 3;

BA_ "GenMsgILSupport" BO_ 2600407301 0;
BA_ "GenMsgSendType" BO_ 2600407301 0;
BA_ "VFrameFormat" BO_ 2600407301 3;

BA_ "GenMsgILSupport" BO_ 2565903754 0;
BA_ "GenMsgSendType" BO_ 2565903754 0;

BA_ "GenMsgSendType" BO_ 2566866977 0;

BA_ "GenMsgILSupport" BO_ 2566771850 0;
BA_ "GenMsgCycleTime" BO_ 2566771850 10000;

BA_ "GenMsgSendType" BO_ 2364610442 0;
BA_ "GenMsgCycleTime" BO_ 2364610442 100;

BA_ "GenMsgSendType" BO_ 2364579978 0;
BA_ "GenMsgCycleTime" BO_ 2364579978 100;

BA_ "GenMsgILSupport" BO_ 2633935883 0;
BA_ "GenMsgCycleTime" BO_ 2633935883 0;

BA_ "GenMsgSendType" BO_ 2566842094 0;
BA_ "GenMsgStartDelayTime" BO_ 2566842094 30;

BA_ "GenMsgILSupport" BO_ 2583638092 0;
BA_ "GenMsgCycleTime" BO_ 2583638092 0;

BA_ "GenMsgILSupport" BO_ 2564488174 0;
BA_ "GenMsgCycleTime" BO_ 2564488174 0;

BA_ "GenMsgILSupport" BO_ 2564430062 0;
BA_ "GenMsgCycleTime" BO_ 2564430062 0;

BA_ "GenMsgILSupport" BO_ 2600422183 0;

BA_ "GenMsgILSupport" BO_ 2600460311 0;
BA_ "GenMsgCycleTime" BO_ 2600460311 0;
BA_ "VFrameFormat" BO_ 2600460311 3;

BA_ "GenMsgILSupport" BO_ 2600462375 0;
BA_ "GenMsgCycleTime" BO_ 2600462375 5000;

BA_ "GenMsgSendType" BO_ 2364547840 0;
BA_ "GenMsgCycleTime" BO_ 2364547840 5000;

BA_ "GenMsgSendType" BO_ 2600403716 0;
BA_ "GenMsgCycleTime" BO_ 2600403716 50;

BA_ "GenMsgSendType" BO_ 2566832622 0;
BA_ "SystemMessageLongSymbol" BO_ 2566832622 "highResolutionVehicleDistance_BASIS";
BA_ "GenMsgILSupport" BO_ 2566864167 0;
BA_ "GenMsgCycleTime" BO_ 2566864167 0;

BA_ "GenMsgILSupport" BO_ 2364642442 0;
BA_ "GenMsgSendType" BO_ 2364642442 0;
BA_ "GenMsgCycleTime" BO_ 2364642442 10000;

BA_ "GenMsgILSupport" BO_ 2364646282 0;
BA_ "GenMsgSendType" BO_ 2364646282 0;
BA_ "GenMsgCycleTime" BO_ 2364646282 10000;

BA_ "GenMsgILSupport" BO_ 2364650122 0;
BA_ "GenMsgSendType" BO_ 2364650122 0;
BA_ "GenMsgCycleTime" BO_ 2364650122 10000;

BA_ "GenMsgILSupport" BO_ 2364661642 0;
BA_ "GenMsgSendType" BO_ 2364661642 0;
BA_ "GenMsgCycleTime" BO_ 2364661642 10000;

BA_ "GenMsgILSupport" BO_ 2364653962 0;
BA_ "GenMsgSendType" BO_ 2364653962 0;
BA_ "GenMsgCycleTime" BO_ 2364653962 10000;

BA_ "GenMsgILSupport" BO_ 2364657802 0;
BA_ "GenMsgSendType" BO_ 2364657802 0;
BA_ "GenMsgCycleTime" BO_ 2364657802 10000;

BA_ "GenMsgILSupport" BO_ 2364676234 0;
BA_ "GenMsgSendType" BO_ 2364676234 0;
BA_ "GenMsgCycleTime" BO_ 2364676234 10000;

BA_ "GenMsgILSupport" BO_ 2364680074 0;
BA_ "GenMsgSendType" BO_ 2364680074 0;
BA_ "GenMsgCycleTime" BO_ 2364680074 10000;

BA_ "GenMsgSendType" BO_ 2566749184 0;

BA_ "GenMsgSendType" BO_ 2566769953 0;
BA_ "GenMsgCycleTime" BO_ 2566769953 200;
BA_ "SystemMessageLongSymbol" BO_ 2566769953 "operatorWiperAndWasherCtrlMsg_BASE";
BA_ "GenMsgSendType" BO_ 2566837553 0;

BA_ "GenMsgSendType" BO_ 2566805551 0;
BA_ "GenMsgCycleTime" BO_ 2566805551 100;

BA_ "GenMsgSendType" BO_ 2566803180 0;
BA_ "GenMsgCycleTime" BO_ 2566803180 100;

BA_ "GenMsgILSupport" BO_ 2566876928 0;
BA_ "GenMsgSendType" BO_ 2566876928 0;
BA_ "GenMsgCycleTime" BO_ 2566876928 10000;
BA_ "VFrameFormat" BO_ 2566876928 3;

BA_ "GenMsgILSupport" BO_ 2566842151 0;
BA_ "GenMsgCycleTime" BO_ 2566842151 0;

BA_ "GenMsgILSupport" BO_ 2600455183 0;
BA_ "GenMsgSendType" BO_ 2600455183 0;

BA_ "GenMsgILSupport" BO_ 2600455173 0;
BA_ "GenMsgSendType" BO_ 2600455173 0;

BA_ "GenMsgILSupport" BO_ 2600455181 0;
BA_ "GenMsgSendType" BO_ 2600455181 0;

BA_ "GenMsgILSupport" BO_ 2600455177 0;
BA_ "GenMsgSendType" BO_ 2600455177 0;

BA_ "GenMsgILSupport" BO_ 2600455185 0;
BA_ "GenMsgSendType" BO_ 2600455185 0;

BA_ "GenMsgILSupport" BO_ 2600455172 0;
BA_ "GenMsgSendType" BO_ 2600455172 0;

BA_ "GenMsgILSupport" BO_ 2600455182 0;
BA_ "GenMsgSendType" BO_ 2600455182 0;

BA_ "GenMsgILSupport" BO_ 2600455179 0;
BA_ "GenMsgSendType" BO_ 2600455179 0;

BA_ "GenMsgILSupport" BO_ 2600455178 0;
BA_ "GenMsgSendType" BO_ 2600455178 0;

BA_ "GenMsgILSupport" BO_ 2600455176 0;
BA_ "GenMsgSendType" BO_ 2600455176 0;

BA_ "GenMsgILSupport" BO_ 2600455180 0;
BA_ "GenMsgSendType" BO_ 2600455180 0;

BA_ "GenMsgILSupport" BO_ 2600455186 0;
BA_ "GenMsgSendType" BO_ 2600455186 0;

BA_ "GenMsgILSupport" BO_ 2600455171 0;
BA_ "GenMsgSendType" BO_ 2600455171 0;

BA_ "GenMsgILSupport" BO_ 2600455184 0;
BA_ "GenMsgSendType" BO_ 2600455184 0;

BA_ "GenMsgILSupport" BO_ 2600455175 0;
BA_ "GenMsgSendType" BO_ 2600455175 0;

BA_ "GenMsgILSupport" BO_ 2600455187 0;
BA_ "GenMsgSendType" BO_ 2600455187 0;

BA_ "GenMsgILSupport" BO_ 2600455174 0;
BA_ "GenMsgSendType" BO_ 2600455174 0;

BA_ "GenMsgSendType" BO_ 2566846247 0;
BA_ "GenMsgStartDelayTime" BO_ 2566846247 30;

BA_ "GenMsgILSupport" BO_ 2566843630 0;
BA_ "GenMsgSendType" BO_ 2566843630 0;
BA_ "GenMsgCycleTime" BO_ 2566843630 10000;
BA_ "VFrameFormat" BO_ 2566843630 3;
BA_ "SystemSignalLongSymbol" SG_ 2566834939 flashMalFunctionalIndicatorLamp_ "flashMalFunctionalIndicatorLamp_CM4_SAE";
BA_ "SystemSignalLongSymbol" SG_ 2566535765 activeDischargeRequest_ePTO1_BAS "activeDischargeRequest_ePTO1_BASE";
BA_ "SystemSignalLongSymbol" SG_ 2566805807 relativeLevelFrontAxleRight_BASI "relativeLevelFrontAxleRight_BASIS";
BA_ "SystemSignalLongSymbol" SG_ 2566838781 Kuehlwassertemperaturwarnung_BAS "Kuehlwassertemperaturwarnung_BASIS";
BA_ "SystemSignalLongSymbol" SG_ 2566847521 engineFuelFilterDiffPressure_BAS "engineFuelFilterDiffPressure_BASIS";
BA_ "SystemSignalLongSymbol" SG_ 2566847521 engineOilFilterDiffPressure_BASI "engineOilFilterDiffPressure_BASIS";
BA_ "SystemSignalLongSymbol" SG_ 2566831883 relatSpeedFrontAxleLeftWheel_BAS "relatSpeedFrontAxleLeftWheel_BASIS";
BA_ "SystemSignalLongSymbol" SG_ 2566831883 relatSpeedFrontAxleRightWheel_BA "relatSpeedFrontAxleRightWheel_BASIS";
BA_ "SystemSignalLongSymbol" SG_ 2566831883 relatSpeedRearAxle1leftWheel_BAS "relatSpeedRearAxle1leftWheel_BASIS";
BA_ "SystemSignalLongSymbol" SG_ 2566831883 relatSpeedRearAxle1rightWheel_BA "relatSpeedRearAxle1rightWheel_BASIS";
BA_ "SystemSignalLongSymbol" SG_ 2566831883 relatSpeedRearAxle2leftWheel_BAS "relatSpeedRearAxle2leftWheel_BASIS";
BA_ "SystemSignalLongSymbol" SG_ 2566831883 relatSpeedRearAxle2rightWheel_BA "relatSpeedRearAxle2rightWheel_BASIS";
BA_ "SystemSignalLongSymbol" SG_ 2566767627 parkBrakeActuatorFullyActivated_ "parkBrakeActuatorFullyActivated_BASE";
BA_ "SystemSignalLongSymbol" SG_ 2566833352 vehicleABSactivePassive_T1_TO_TR "vehicleABSactivePassive_T1_TO_TRUCK_EBS22";
BA_ "SystemSignalLongSymbol" SG_ 2566833352 redWarningSignalRequest_T1_TO_TR "redWarningSignalRequest_T1_TO_TRUCK";
BA_ "SystemSignalLongSymbol" SG_ 2566833352 amberWarningSignalRequest_T1_TO_ "amberWarningSignalRequest_T1_TO_TRUCK";
BA_ "SystemSignalLongSymbol" SG_ 2566833352 electricalSupplyOfNonBrakingSyst "electricalSupplyOfNonBrakingSystems_T1_TO_TRUCK";
BA_ "SystemSignalLongSymbol" SG_ 2566833352 electrLoadProportionalFunc_T1_TO "electrLoadProportionalFunc_T1_TO_TRUCK";
BA_ "SystemSignalLongSymbol" SG_ 2566833352 vehicleRetContrActivePassive_T1_ "vehicleRetContrActivePassive_T1_TO_TRUCK_EBS22";
BA_ "SystemSignalLongSymbol" SG_ 2566833352 loadingRampApproachAssistance_T1 "loadingRampApproachAssistance_T1_TO_TRUCK";
BA_ "SystemSignalLongSymbol" SG_ 2566833352 supplylineBrakingRequest_T1_TO_T "supplylineBrakingRequest_T1_TO_TRUCK";
BA_ "SystemSignalLongSymbol" SG_ 2566833352 vehicleServiceBrakeActPass_T1_TO "vehicleServiceBrakeActPass_T1_TO_TRUCK_EBS22";
BA_ "SystemSignalLongSymbol" SG_ 2566833352 referenceRetarderTorque_T1_TO_TR "referenceRetarderTorque_T1_TO_TRUCK";
BA_ "SystemSignalLongSymbol" SG_ 2566833352 automaticTowedVehicleBrake_T1_TO "automaticTowedVehicleBrake_T1_TO_TRUCK_EBS22";
BA_ "SystemSignalLongSymbol" SG_ 2566833352 vehicleElectricalSupply_T1_TO_TR "vehicleElectricalSupply_T1_TO_TRUCK";
BA_ "SystemSignalLongSymbol" SG_ 2566841639 engineTotalHoursOfOperation_BASI "engineTotalHoursOfOperation_BASIS";
BA_ "SystemSignalLongSymbol" SG_ 2566843904 engineTurbochargerOilTemperature "engineTurbochargerOilTemperature_BASE";
BA_ "SystemSignalLongSymbol" SG_ 2566843904 engineIntercoolerTemperature_BAS "engineIntercoolerTemperature_BASIS";
BA_ "SystemSignalLongSymbol" SG_ 2566843904 engIntercoolerThermostatOpening_ "engIntercoolerThermostatOpening_BASE";
BA_ "SystemSignalLongSymbol" SG_ 2364539395 torqueConverterLockupEngaged_BAS "torqueConverterLockupEngaged_BASIS";
BA_ "SystemSignalLongSymbol" SG_ 2364539395 engineMomentaryOverspeedEnable_B "engineMomentaryOverspeedEnable_BASIS";
BA_ "SystemSignalLongSymbol" SG_ 2364539395 transmissionInputShaftSpeed_BASI "transmissionInputShaftSpeed_BASIS";
BA_ "SystemSignalLongSymbol" SG_ 2364539395 transmissionOutputShaftSpeed_BAS "transmissionOutputShaftSpeed_BASIS";
BA_ "SystemSignalLongSymbol" SG_ 2633880061 FMSstandardDiagnosticsSupported_ "FMSstandardDiagnosticsSupported_BASE";
BA_ "SystemSignalLongSymbol" SG_ 2633880061 FMSstandardRequestsSupported_BAS "FMSstandardRequestsSupported_BASE";
BA_ "SystemSignalLongSymbol" SG_ 2633880061 FMSstandardSWversionSupported_BA "FMSstandardSWversionSupported_BASE";
BA_ "SystemSignalLongSymbol" SG_ 2566719744 highResolutionEngineTripFuel_BAS "highResolutionEngineTripFuel_BASE";
BA_ "SystemSignalLongSymbol" SG_ 2566844967 engineInstantaneousFuelEconomy_B "engineInstantaneousFuelEconomy_BASIS";
BA_ "SystemSignalLongSymbol" SG_ 2633935883 brakeLineRemainFrontAxleLeftW_BA "brakeLineRemainFrontAxleLeftW_BASIS";
BA_ "SystemSignalLongSymbol" SG_ 2633935883 brakeLineRemainRearAxle1leftW_BA "brakeLineRemainRearAxle1leftW_BASIS";
BA_ "SystemSignalLongSymbol" SG_ 2633935883 brakeLineRemainRearAxle1rightW_B "brakeLineRemainRearAxle1rightW_BASIS";
BA_ "SystemSignalLongSymbol" SG_ 2633935883 brakeLineRemainRearAxle2leftW_BA "brakeLineRemainRearAxle2leftW_BASIS";
BA_ "SystemSignalLongSymbol" SG_ 2633935883 brakeLineRemainRearAxle2rightW_B "brakeLineRemainRearAxle2rightW_BASIS";
BA_ "SystemSignalLongSymbol" SG_ 2633935883 brakeLineRemainRearAxle3leftW_BA "brakeLineRemainRearAxle3leftW_BASIS";
BA_ "SystemSignalLongSymbol" SG_ 2633935883 brakeLineRemainRearAxle3rightW_B "brakeLineRemainRearAxle3rightW_BASIS";
BA_ "SystemSignalLongSymbol" SG_ 2633935883 brakeLineRemainFrontAxleRightW_B "brakeLineRemainFrontAxleRightW_BASIS";
BA_ "SystemSignalLongSymbol" SG_ 2566832622 highResolutionTotalVehDistance_B "highResolutionTotalVehDistance_BASIS";
BA_ "SystemSignalLongSymbol" SG_ 2566749184 DPFactvRgnrtnInhDue2LowExhGasTmp "DPFactvRgnrtnInhDue2LowExhGasTmp_BASE";
BA_ "SystemSignalLongSymbol" SG_ 2566749184 DPFactvRgnrtnInhDue2SysFaultActv "DPFactvRgnrtnInhDue2SysFaultActv_BASE";
BA_ "SystemSignalLongSymbol" SG_ 2566749184 DPFactvRgnrtnInhDue2EngNotWarmUp "DPFactvRgnrtnInhDue2EngNotWarmUp_BASE";
BA_ "SystemSignalLongSymbol" SG_ 2566749184 exhaustSysHighTempLampCommand_BA "exhaustSysHighTempLampCommand_BASE";
BA_ "SystemSignalLongSymbol" SG_ 2566749184 DPFpassiveRegenerationStatus_BAS "DPFpassiveRegenerationStatus_BASE";
BA_ "SystemSignalLongSymbol" SG_ 2566769953 frontOperatorWiperDelayControl_B "frontOperatorWiperDelayControl_BASE";
BA_ "SystemSignalLongSymbol" SG_ 2566769953 frontNonoperatorWiperDelayCtrl_B "frontNonoperatorWiperDelayCtrl_BASE";
BA_ "SystemSignalLongSymbol" SG_ 2566769953 frontNonoperatorWasherSwitch_BAS "frontNonoperatorWasherSwitch_BASE";
BA_ "SystemSignalLongSymbol" SG_ 2566805551 bellowPressureFrontAxleLeft_ASC4 "bellowPressureFrontAxleLeft_ASC4_SSC1";
BA_ "SystemSignalLongSymbol" SG_ 2566805551 bellowPressureFrontAxleRight_ASC "bellowPressureFrontAxleRight_ASC4_SSC1";
BA_ "SystemSignalLongSymbol" SG_ 2566805551 bellowPressureRearAxleLeft_ASC4_ "bellowPressureRearAxleLeft_ASC4_SSC1";
BA_ "SystemSignalLongSymbol" SG_ 2566805551 bellowPressureRearAxleRight_ASC4 "bellowPressureRearAxleRight_ASC4_SSC1";
BA_ "GenSigSendType" SG_ 2600460568 rmtTstrBattCurrentOTA_BASE 0;
BA_ "GenSigSendType" SG_ 2600460568 rmtTstrInstallProgressBar_BASE 0;
BA_ "GenSigSendType" SG_ 2600460568 rmtTstrDispCondC1gearNeut_BASE 0;
BA_ "GenSigSendType" SG_ 2600460568 rmtTstrDispCondC1VehSpd_BASE 0;
BA_ "GenSigSendType" SG_ 2600460568 rmtTstrDispCondC1ParkBrake_BASE 0;
BA_ "GenSigSendType" SG_ 2600460568 rmtTstrDispCondC1engSpd_BASE 0;
BA_ "GenSigSendType" SG_ 2600460568 rmtTstrDispCondIgnition_BASE 0;
BA_ "GenSigSendType" SG_ 2600460568 rmtTstrDispCondOBD_BASE 0;
BA_ "GenSigSendType" SG_ 2600460568 rmtTstrDispICLreset_BASE 0;
BA_ "GenSigSendType" SG_ 2600460568 rmtTstrDispUpdateAvail_BASE 0;
BA_ "GenSigSendType" SG_ 2600460568 rmtTstrInstallNumOfJobs_BASE 0;
BA_ "GenSigSendType" SG_ 2600460568 rmtTstrInstallTxtUpdToggle_BASE 0;
BA_ "GenSigSendType" SG_ 2600460568 rmtTstrDispCondEPTO_BASE 0;
BA_ "GenSigSendType" SG_ 2600460568 rmtTstrDispCond24VBattChrg_BASE 0;
BA_ "GenSigSendType" SG_ 2600460568 rmtTstrDispCondSecCerts_BASE 0;
BA_ "GenSigSendType" SG_ 2600460568 rmtTstrDispCondCurrent_BASE 0;
BA_ "GenSigSendType" SG_ 2600460568 rmtTstrDispAllowDriverExit_BASE 0;
BA_ "GenSigSendType" SG_ 2600460568 rmtTstrDispCondExtrnlChrg_BASE 0;
BA_ "GenSigSendType" SG_ 2600460568 rmtTstrOverrideCl15_BASE 0;
BA_ "GenSigSendType" SG_ 2600460568 rmtTstrInstallEstTotTime_VAR1 0;
BA_ "GenSigSendType" SG_ 2566834939 protectLampStatus_CM4_SAE 0;
BA_ "GenSigSendType" SG_ 2566834939 flashAmberWarningLamp_CM4_SAE 0;
BA_ "GenSigSendType" SG_ 2566834939 SPN_high_reserved03_CM4_SAE 0;
BA_ "GenSigSendType" SG_ 2566834939 OcC_03_CM4_SAE 0;
BA_ "GenSigSendType" SG_ 2566834939 CM_03_CM4_SAE 0;
BA_ "GenSigSendType" SG_ 2566834939 SPN_04_CM4_SAE 0;
BA_ "GenSigSendType" SG_ 2566834939 flashRedStopLamp_CM4_SAE 0;
BA_ "GenSigSendType" SG_ 2566834939 FMI_04_CM4_SAE 0;
BA_ "GenSigSendType" SG_ 2566834939 SPN_high_reserved04_CM4_SAE 0;
BA_ "GenSigSendType" SG_ 2566834939 OcC_04_CM4_SAE 0;
BA_ "GenSigSendType" SG_ 2566834939 flashMalFunctionalIndicatorLamp_ 0;
BA_ "GenSigSendType" SG_ 2566834939 CM_04_CM4_SAE 0;
BA_ "GenSigSendType" SG_ 2566834939 SPN_05_CM4_SAE 0;
BA_ "GenSigSendType" SG_ 2566834939 SPN_01_CM4_SAE 0;
BA_ "GenSigSendType" SG_ 2566834939 FMI_05_CM4_SAE 0;
BA_ "GenSigSendType" SG_ 2566834939 SPN_high_reserved05_CM4_SAE 0;
BA_ "GenSigSendType" SG_ 2566834939 OcC_05_CM4_SAE 0;
BA_ "GenSigSendType" SG_ 2566834939 CM_05_CM4_SAE 0;
BA_ "GenSigSendType" SG_ 2566834939 SPN_06_CM4_SAE 0;
BA_ "GenSigSendType" SG_ 2566834939 FMI_06_CM4_SAE 0;
BA_ "GenSigSendType" SG_ 2566834939 SPN_high_reserved06_CM4_SAE 0;
BA_ "GenSigSendType" SG_ 2566834939 amberWarningLamp_CM4_SAE 0;
BA_ "GenSigSendType" SG_ 2566834939 OcC_06_CM4_SAE 0;
BA_ "GenSigSendType" SG_ 2566834939 CM_06_CM4_SAE 0;
BA_ "GenSigSendType" SG_ 2566834939 SPN_07_CM4_SAE 0;
BA_ "GenSigSendType" SG_ 2566834939 FMI_07_CM4_SAE 0;
BA_ "GenSigSendType" SG_ 2566834939 SPN_high_reserved07_CM4_SAE 0;
BA_ "GenSigSendType" SG_ 2566834939 OcC_07_CM4_SAE 0;
BA_ "GenSigSendType" SG_ 2566834939 CM_07_CM4_SAE 0;
BA_ "GenSigSendType" SG_ 2566834939 SPN_08_CM4_SAE 0;
BA_ "GenSigSendType" SG_ 2566834939 FMI_08_CM4_SAE 0;
BA_ "GenSigSendType" SG_ 2566834939 SPN_high_reserved08_CM4_SAE 0;
BA_ "GenSigSendType" SG_ 2566834939 OcC_08_CM4_SAE 0;
BA_ "GenSigSendType" SG_ 2566834939 CM_08_CM4_SAE 0;
BA_ "GenSigSendType" SG_ 2566834939 SPN_09_CM4_SAE 0;
BA_ "GenSigSendType" SG_ 2566834939 FMI_09_CM4_SAE 0;
BA_ "GenSigSendType" SG_ 2566834939 SPN_high_reserved09_CM4_SAE 0;
BA_ "GenSigSendType" SG_ 2566834939 OcC_09_CM4_SAE 0;
BA_ "GenSigSendType" SG_ 2566834939 CM_09_CM4_SAE 0;
BA_ "GenSigSendType" SG_ 2566834939 SPN_10_CM4_SAE 0;
BA_ "GenSigSendType" SG_ 2566834939 FMI_01_CM4_SAE 0;
BA_ "GenSigSendType" SG_ 2566834939 FMI_10_CM4_SAE 0;
BA_ "GenSigSendType" SG_ 2566834939 SPN_high_reserved10_CM4_SAE 0;
BA_ "GenSigSendType" SG_ 2566834939 OcC_10_CM4_SAE 0;
BA_ "GenSigSendType" SG_ 2566834939 CM_10_CM4_SAE 0;
BA_ "GenSigSendType" SG_ 2566834939 SPN_high_reserved01_CM4_SAE 0;
BA_ "GenSigSendType" SG_ 2566834939 redStopLamp_CM4_SAE 0;
BA_ "GenSigSendType" SG_ 2566834939 OcC_01_CM4_SAE 0;
BA_ "GenSigSendType" SG_ 2566834939 CM_01_CM4_SAE 0;
BA_ "GenSigSendType" SG_ 2566834939 SPN_02_CM4_SAE 0;
BA_ "GenSigSendType" SG_ 2566834939 malfunctionIndicatorLamp_CM4_SAE 0;
BA_ "GenSigSendType" SG_ 2566834939 FMI_02_CM4_SAE 0;
BA_ "GenSigSendType" SG_ 2566834939 SPN_high_reserved02_CM4_SAE 0;
BA_ "GenSigSendType" SG_ 2566834939 OcC_02_CM4_SAE 0;
BA_ "GenSigSendType" SG_ 2566834939 CM_02_CM4_SAE 0;
BA_ "GenSigSendType" SG_ 2566834939 flashProtectLampStatus_CM4_SAE 0;
BA_ "GenSigSendType" SG_ 2566834939 SPN_03_CM4_SAE 0;
BA_ "GenSigSendType" SG_ 2566834939 FMI_03_CM4_SAE 0;
BA_ "GenSigSendType" SG_ 2566535765 ePTODE1_CRC_BASE 0;
BA_ "GenSigSendType" SG_ 2566535765 enableSwitchePTO1_BASE 0;
BA_ "GenSigSendType" SG_ 2566535765 engageConsent_ePTO1_BASE 0;
BA_ "GenSigSendType" SG_ 2566535765 engageStatus_ePTO1_BASE 0;
BA_ "GenSigSendType" SG_ 2566535765 emrgncyDeenSw_ePTO1_BASE 0;
BA_ "GenSigSendType" SG_ 2566535765 systemRdnss_ePTO1_BASE 0;
BA_ "GenSigSendType" SG_ 2566535765 errorIndicator_ePTO1_BASE 0;
BA_ "GenSigSendType" SG_ 2566535765 activeDischargeRequest_ePTO1_BAS 0;
BA_ "GenSigSendType" SG_ 2566535765 ePTODE1_Count_BASE 0;
BA_ "GenSigSendType" SG_ 2566896981 ASP2_CRC8_BASE 0;
BA_ "GenSigSendType" SG_ 2566896981 bobuWiperFrontReq_BASE 0;
BA_ "GenSigSendType" SG_ 2566896981 bobuFlashLightReq_BASE 0;
BA_ "GenSigSendType" SG_ 2566896981 rightTurnSignalLightsCmd_BASE 0;
BA_ "GenSigSendType" SG_ 2566896981 leftTurnSignalLightsCmd_BASE 0;
BA_ "GenSigSendType" SG_ 2566896981 haltBrakeSwitch_BASIS 0;
BA_ "GenSigSendType" SG_ 2566896981 parkBrkAppReqBB_BASE 0;
BA_ "GenSigSendType" SG_ 2566896981 parkBrkRlsReqBB_BASE 0;
BA_ "GenSigSendType" SG_ 2566896981 parkBrkRlsInhibitBB_BASE 0;
BA_ "GenSigSendType" SG_ 2566896981 bobuAlarmDriveLvl_BASE 0;
BA_ "GenSigSendType" SG_ 2566896981 ASP2__cnt_BASE 0;
BA_ "GenSigSendType" SG_ 2566897041 ASP2_CRC8_BASE 0;
BA_ "GenSigSendType" SG_ 2566897041 bobuWiperFrontReq_BASE 0;
BA_ "GenSigSendType" SG_ 2566897041 bobuFlashLightReq_BASE 0;
BA_ "GenSigSendType" SG_ 2566897041 rightTurnSignalLightsCmd_BASE 0;
BA_ "GenSigSendType" SG_ 2566897041 leftTurnSignalLightsCmd_BASE 0;
BA_ "GenSigSendType" SG_ 2566897041 haltBrakeSwitch_BASIS 0;
BA_ "GenSigSendType" SG_ 2566897041 parkBrkAppReqBB_BASE 0;
BA_ "GenSigSendType" SG_ 2566897041 parkBrkRlsReqBB_BASE 0;
BA_ "GenSigSendType" SG_ 2566897041 parkBrkRlsInhibitBB_BASE 0;
BA_ "GenSigSendType" SG_ 2566897041 bobuAlarmDriveLvl_BASE 0;
BA_ "GenSigSendType" SG_ 2566897041 ASP2__cnt_BASE 0;
BA_ "GenSigSendType" SG_ 2566897040 ASP2_CRC8_BASE 0;
BA_ "GenSigSendType" SG_ 2566897040 bobuWiperFrontReq_BASE 0;
BA_ "GenSigSendType" SG_ 2566897040 bobuFlashLightReq_BASE 0;
BA_ "GenSigSendType" SG_ 2566897040 rightTurnSignalLightsCmd_BASE 0;
BA_ "GenSigSendType" SG_ 2566897040 leftTurnSignalLightsCmd_BASE 0;
BA_ "GenSigSendType" SG_ 2566897040 haltBrakeSwitch_BASIS 0;
BA_ "GenSigSendType" SG_ 2566897040 parkBrkAppReqBB_BASE 0;
BA_ "GenSigSendType" SG_ 2566897040 parkBrkRlsReqBB_BASE 0;
BA_ "GenSigSendType" SG_ 2566897040 parkBrkRlsInhibitBB_BASE 0;
BA_ "GenSigSendType" SG_ 2566897040 bobuAlarmDriveLvl_BASE 0;
BA_ "GenSigSendType" SG_ 2566897040 ASP2__cnt_BASE 0;
BA_ "GenSigSendType" SG_ 2600454919 dStmrMngmntDaysOTAreq_BASE 0;
BA_ "GenSigSendType" SG_ 2600454919 dStmrMngmntTmrSettgsOTAreq_BASE 0;
BA_ "GenSigSendType" SG_ 2600454919 tmrMngmntTimerIndexOTAreq_BASE 0;
BA_ "GenSigSendType" SG_ 2600454919 reqVehPrkChangeOTA_BASE 0;
BA_ "GenSigSendType" SG_ 2600454919 dStmrMngmntTrgtTimeOTAreq_BASE 0;
BA_ "GenSigSendType" SG_ 2600454919 reqTempStageOTA_BASE 0;
BA_ "GenSigSendType" SG_ 2600454919 reqTempOTA_BASE 0;
BA_ "GenSigSendType" SG_ 2600454919 dStmrMngmntHoldDurOTAreq_BASE 0;
BA_ "GenSigSendType" SG_ 2566818901 auxiliaryTemperature1_BASIS 0;
BA_ "GenSigSendType" SG_ 2566818901 auxiliaryPressure1_BASIS 0;
BA_ "GenSigSendType" SG_ 2566818901 auxiliaryPressure2_BASIS 0;
BA_ "GenSigSendType" SG_ 2566818901 auxiliaryLevel_BASIS 0;
BA_ "GenSigSendType" SG_ 2566818901 airHumidity_BASIS 0;
BA_ "GenSigSendType" SG_ 2566818901 auxiliaryTemperature3_BASIS 0;
BA_ "GenSigSendType" SG_ 2566818901 auxiliaryTemperature2_BASIS 0;
BA_ "GenSigSendType" SG_ 2600454922 auxStatCM13placeholder_BASE 0;
BA_ "GenSigSendType" SG_ 2566845696 barometricPressure_BASIS 0;
BA_ "GenSigSendType" SG_ 2566845696 ambientAirTemperature_BASIS 0;
BA_ "GenSigSendType" SG_ 2566845696 cabInteriorTemperature_BASIS 0;
BA_ "GenSigSendType" SG_ 2566805807 relativeLevelFrontAxleLeft_BASIS 0;
BA_ "GenSigSendType" SG_ 2566805807 relativeLevelFrontAxleRight_BASI 0;
BA_ "GenSigSendType" SG_ 2566805807 relativeLevelRearAxleLeft_BASIS 0;
BA_ "GenSigSendType" SG_ 2566805807 relativeLevelRearAxleRight_BASIS 0;
BA_ "GenSigSendType" SG_ 2566838781 Kuehlwassertemperaturwarnung_BAS 0;
BA_ "GenSigSendType" SG_ 2566838781 Oeldruckwarnung_BASIS 0;
BA_ "GenSigSendType" SG_ 2563833623 illuminationBrightness_BASIS 0;
BA_ "GenSigSendType" SG_ 2566843687 maximumVehicleSpeedLimit_BASIS 0;
BA_ "GenSigSendType" SG_ 2566843687 CClowSetLimitSpeed_BASIS 0;
BA_ "GenSigSendType" SG_ 2566843687 CChighSetLimitSpeed_BASIS 0;
BA_ "GenSigSendType" SG_ 2566847521 washerFluidLevel_BASIS 0;
BA_ "GenSigSendType" SG_ 2566847521 engineFuelFilterDiffPressure_BAS 0;
BA_ "GenSigSendType" SG_ 2566847521 engineOilFilterDiffPressure_BASI 0;
BA_ "GenSigSendType" SG_ 2566847521 cargoAmbientTemperature_BASIS 0;
BA_ "GenSigSendType" SG_ 2566847521 fuelLevel2_BASE 0;
BA_ "GenSigSendType" SG_ 2566847521 fuelLevel_BASIS 0;
BA_ "GenSigSendType" SG_ 2566759916 lockStatusOfDoor1_BASIS 0;
BA_ "GenSigSendType" SG_ 2566759916 enableStatusOfDoor2_BASIS 0;
BA_ "GenSigSendType" SG_ 2566759916 lockStatusOfDoor3_BASIS 0;
BA_ "GenSigSendType" SG_ 2566759916 openStatusOfDoor3_BASIS 0;
BA_ "GenSigSendType" SG_ 2566759916 enableStatusOfDoor3_BASIS 0;
BA_ "GenSigSendType" SG_ 2566759916 lockStatusOfDoor4_BASIS 0;
BA_ "GenSigSendType" SG_ 2566759916 openStatusOfDoor1_BASIS 0;
BA_ "GenSigSendType" SG_ 2566759916 openStatusOfDoor4_BASIS 0;
BA_ "GenSigSendType" SG_ 2566759916 enableStatusOfDoor4_BASIS 0;
BA_ "GenSigSendType" SG_ 2566759916 lockStatusOfDoor5_BASIS 0;
BA_ "GenSigSendType" SG_ 2566759916 openStatusOfDoor5_BASIS 0;
BA_ "GenSigSendType" SG_ 2566759916 enableStatusOfDoor5_BASIS 0;
BA_ "GenSigSendType" SG_ 2566759916 lockStatusOfDoor6_BASIS 0;
BA_ "GenSigSendType" SG_ 2566759916 openStatusOfDoor6_BASIS 0;
BA_ "GenSigSendType" SG_ 2566759916 enableStatusOfDoor6_BASIS 0;
BA_ "GenSigSendType" SG_ 2566759916 lockStatusOfDoor7_BASIS 0;
BA_ "GenSigSendType" SG_ 2566759916 openStatusOfDoor7_BASIS 0;
BA_ "GenSigSendType" SG_ 2566759916 enableStatusOfDoor1_BASIS 0;
BA_ "GenSigSendType" SG_ 2566759916 enableStatusOfDoor7_BASIS 0;
BA_ "GenSigSendType" SG_ 2566759916 lockStatusOfDoor8_BASIS 0;
BA_ "GenSigSendType" SG_ 2566759916 openStatusOfDoor8_BASIS 0;
BA_ "GenSigSendType" SG_ 2566759916 enableStatusOfDoor8_BASIS 0;
BA_ "GenSigSendType" SG_ 2566759916 lockStatusOfDoor9_BASIS 0;
BA_ "GenSigSendType" SG_ 2566759916 openStatusOfDoor9_BASIS 0;
BA_ "GenSigSendType" SG_ 2566759916 enableStatusOfDoor9_BASIS 0;
BA_ "GenSigSendType" SG_ 2566759916 lockStatusOfDoor10_BASIS 0;
BA_ "GenSigSendType" SG_ 2566759916 openStatusOfDoor10_BASIS 0;
BA_ "GenSigSendType" SG_ 2566759916 enableStatusOfDoor10_BASIS 0;
BA_ "GenSigSendType" SG_ 2566759916 lockStatusOfDoor2_BASIS 0;
BA_ "GenSigSendType" SG_ 2566759916 openStatusOfDoor2_BASIS 0;
BA_ "GenSigSendType" SG_ 2566810606 driverIdentification_BASE 0;
BA_ "GenSigSendType" SG_ 2566831883 frontAxleSpeed_BASIS 0;
BA_ "GenSigSendType" SG_ 2566831883 relatSpeedFrontAxleLeftWheel_BAS 0;
BA_ "GenSigSendType" SG_ 2566831883 relatSpeedFrontAxleRightWheel_BA 0;
BA_ "GenSigSendType" SG_ 2566831883 relatSpeedRearAxle1leftWheel_BAS 0;
BA_ "GenSigSendType" SG_ 2566831883 relatSpeedRearAxle1rightWheel_BA 0;
BA_ "GenSigSendType" SG_ 2566831883 relatSpeedRearAxle2leftWheel_BAS 0;
BA_ "GenSigSendType" SG_ 2566831883 relatSpeedRearAxle2rightWheel_BA 0;
BA_ "GenSigSendType" SG_ 2566767627 brakeTemperatureWarning_BASE 0;
BA_ "GenSigSendType" SG_ 2566767627 XBRsystemState_BASIS 0;
BA_ "GenSigSendType" SG_ 2566767627 XBRactiveControlMode_BASIS 0;
BA_ "GenSigSendType" SG_ 2566767627 XBRaccelerationLimit_BASIS 0;
BA_ "GenSigSendType" SG_ 2566767627 haltBrakeMode_BASIS 0;
BA_ "GenSigSendType" SG_ 2566767627 parkBrakeActuatorFullyActivated_ 0;
BA_ "GenSigSendType" SG_ 2566767627 emergencyBrakingActive_BASE 0;
BA_ "GenSigSendType" SG_ 2566767627 hillHolderMode_BASIS 0;
BA_ "GenSigSendType" SG_ 2566767627 foundationBrakeUse_BASIS 0;
BA_ "GenSigSendType" SG_ 2566833352 vehicleABSactivePassive_T1_TO_TR 0;
BA_ "GenSigSendType" SG_ 2566833352 redWarningSignalRequest_T1_TO_TR 0;
BA_ "GenSigSendType" SG_ 2566833352 amberWarningSignalRequest_T1_TO_ 0;
BA_ "GenSigSendType" SG_ 2566833352 electricalSupplyOfNonBrakingSyst 0;
BA_ "GenSigSendType" SG_ 2566833352 springBrakeInstalled_T1_TO_TRUCK 0;
BA_ "GenSigSendType" SG_ 2566833352 electrLoadProportionalFunc_T1_TO 0;
BA_ "GenSigSendType" SG_ 2566833352 vehicleRetContrActivePassive_T1_ 0;
BA_ "GenSigSendType" SG_ 2566833352 vehicleType_T1_TO_TRUCK_EBS22 0;
BA_ "GenSigSendType" SG_ 2566833352 springBrakeEngaged_T1_TO_TRUCK 0;
BA_ "GenSigSendType" SG_ 2566833352 loadingRampApproachAssistance_T1 0;
BA_ "GenSigSendType" SG_ 2566833352 supplylineBrakingRequest_T1_TO_T 0;
BA_ "GenSigSendType" SG_ 2566833352 stopLampsRequest_BASE 0;
BA_ "GenSigSendType" SG_ 2566833352 electricCtrlLineBrkngSuprt_BASE 0;
BA_ "GenSigSendType" SG_ 2566833352 axleLoadSum_T1_TO_TRUCK 0;
BA_ "GenSigSendType" SG_ 2566833352 vehicleServiceBrakeActPass_T1_TO 0;
BA_ "GenSigSendType" SG_ 2566833352 referenceRetarderTorque_T1_TO_TR 0;
BA_ "GenSigSendType" SG_ 2566833352 automaticTowedVehicleBrake_T1_TO 0;
BA_ "GenSigSendType" SG_ 2566833352 vehicleElectricalSupply_T1_TO_TR 0;
BA_ "GenSigSendType" SG_ 2566844160 engineFuelDeliveryPressure_BASIS 0;
BA_ "GenSigSendType" SG_ 2566844160 engineOilLevel_BASIS 0;
BA_ "GenSigSendType" SG_ 2566844160 engineOilPressure_BASIS 0;
BA_ "GenSigSendType" SG_ 2566844160 engineCoolantPressure_BASE 0;
BA_ "GenSigSendType" SG_ 2566841639 engineTotalHoursOfOperation_BASI 0;
BA_ "GenSigSendType" SG_ 2566841639 engineTotalRevolutions_BASIS 0;
BA_ "GenSigSendType" SG_ 2566843904 engineCoolantTemperature_BASIS 0;
BA_ "GenSigSendType" SG_ 2566843904 engineOilTemperature1_BASIS 0;
BA_ "GenSigSendType" SG_ 2566843904 engineTurbochargerOilTemperature 0;
BA_ "GenSigSendType" SG_ 2566843904 engineIntercoolerTemperature_BAS 0;
BA_ "GenSigSendType" SG_ 2566843904 engIntercoolerThermostatOpening_ 0;
BA_ "GenSigSendType" SG_ 2566843904 engineFuelTemperature_BASIS 0;
BA_ "GenSigSendType" SG_ 2364539395 drivelineEngaged_BASIS 0;
BA_ "GenSigSendType" SG_ 2364539395 torqueConverterLockupEngaged_BAS 0;
BA_ "GenSigSendType" SG_ 2364539395 kupplungsweg_BASIS 0;
BA_ "GenSigSendType" SG_ 2364539395 engineMomentaryOverspeedEnable_B 0;
BA_ "GenSigSendType" SG_ 2364539395 progressiveShiftDisable_BASIS 0;
BA_ "GenSigSendType" SG_ 2364539395 PTO2permission_BASIS 0;
BA_ "GenSigSendType" SG_ 2364539395 PTO1permission_BASIS 0;
BA_ "GenSigSendType" SG_ 2364539395 shiftInProcess_BASIS 0;
BA_ "GenSigSendType" SG_ 2364539395 transmissionInputShaftSpeed_BASI 0;
BA_ "GenSigSendType" SG_ 2364539395 transmissionOutputShaftSpeed_BAS 0;
BA_ "GenSigSendType" SG_ 2633880061 FMSstandardDiagnosticsSupported_ 0;
BA_ "GenSigSendType" SG_ 2633880061 FMSstandardRequestsSupported_BAS 0;
BA_ "GenSigSendType" SG_ 2633880061 FMSstandardSWversionSupported_BA 0;
BA_ "GenSigSendType" SG_ 2566842663 engineTripFuel_BASIS 0;
BA_ "GenSigSendType" SG_ 2566842663 engineTotalFuelUsed_BASIS 0;
BA_ "GenSigSendType" SG_ 2566719744 highResolutionEngineTripFuel_BAS 0;
BA_ "GenSigSendType" SG_ 2566719744 HRengineTotalFuelUsed_BASE 0;
BA_ "GenSigSendType" SG_ 2566844967 engineFuelRate_BASIS 0;
BA_ "GenSigSendType" SG_ 2566844967 engineInstantaneousFuelEconomy_B 0;
BA_ "GenSigSendType" SG_ 2566844967 engineAverageFuelEconomy_BASIS 0;
BA_ "GenSigSendType" SG_ 2365443111 turnSignalSwitch_BASE 0;
BA_ "GenSigSendType" SG_ 2566805053 catalystTankLevel_BASIS 0;
BA_ "GenSigSendType" SG_ 2566805053 temperatureReagentInTank_BASIS 0;
BA_ "GenSigSendType" SG_ 2365484270 driver1workingState_BASIS 0;
BA_ "GenSigSendType" SG_ 2365484270 driverCard1_BASIS 0;
BA_ "GenSigSendType" SG_ 2365484270 overspeed_BASIS 0;
BA_ "GenSigSendType" SG_ 2365484270 driver2timeRelatedStates_BASIS 0;
BA_ "GenSigSendType" SG_ 2365484270 driverCard2_BASIS 0;
BA_ "GenSigSendType" SG_ 2365484270 systemEvent_BASIS 0;
BA_ "GenSigSendType" SG_ 2365484270 handlingInformation_BASIS 0;
BA_ "GenSigSendType" SG_ 2365484270 tachographPerformance_BASIS 0;
BA_ "GenSigSendType" SG_ 2365484270 driver2workingState_BASIS 0;
BA_ "GenSigSendType" SG_ 2365484270 directionIndicator_BASIS 0;
BA_ "GenSigSendType" SG_ 2365484270 tachographOutputShaftSpeed_BASIS 0;
BA_ "GenSigSendType" SG_ 2365484270 tachographVehicleSpeed_BASIS 0;
BA_ "GenSigSendType" SG_ 2365484270 driveRecognize_BASIS 0;
BA_ "GenSigSendType" SG_ 2365484270 driver1timeRelatedStates_BASIS 0;
BA_ "GenSigSendType" SG_ 2566802471 OprtrsBlackOutIntnstySel_BASE 0;
BA_ "GenSigSendType" SG_ 2566806728 tyreWheelIdentification_BASIS 0;
BA_ "GenSigSendType" SG_ 2566806728 axleLoad_BASE 0;
BA_ "GenSigSendType" SG_ 2565870375 pitchAngle_SAE 0;
BA_ "GenSigSendType" SG_ 2565870375 rollAngle_SAE 0;
BA_ "GenSigSendType" SG_ 2565870375 pitchAngleFigureofMerit_SAE 0;
BA_ "GenSigSendType" SG_ 2565870375 rollAngleFigureofMerit_SAE 0;
BA_ "GenSigSendType" SG_ 2566846467 transmissionOilTemperature_TCU 0;
BA_ "GenSigSendType" SG_ 2566846467 transmissionOilLevel_TCU 0;
BA_ "GenSigSendType" SG_ 2566749489 tellTaleBlockID_BASE 0;
BA_ "GenSigSendType" SG_ 2566749489 tellTaleStatus03_BASE 0;
BA_ "GenSigSendType" SG_ 2566749489 tellTaleStatus04_BASE 0;
BA_ "GenSigSendType" SG_ 2566749489 tellTaleStatus05_BASE 0;
BA_ "GenSigSendType" SG_ 2566749489 tellTaleStatus06_BASE 0;
BA_ "GenSigSendType" SG_ 2566749489 tellTaleStatus07_BASE 0;
BA_ "GenSigSendType" SG_ 2566749489 tellTaleStatus08_BASE 0;
BA_ "GenSigSendType" SG_ 2566749489 tellTaleStatus09_BASE 0;
BA_ "GenSigSendType" SG_ 2566749489 tellTaleStatus01_BASE 0;
BA_ "GenSigSendType" SG_ 2566749489 tellTaleStatus10_BASE 0;
BA_ "GenSigSendType" SG_ 2566749489 tellTaleStatus11_BASE 0;
BA_ "GenSigSendType" SG_ 2566749489 tellTaleStatus12_BASE 0;
BA_ "GenSigSendType" SG_ 2566749489 tellTaleStatus13_BASE 0;
BA_ "GenSigSendType" SG_ 2566749489 tellTaleStatus14_BASE 0;
BA_ "GenSigSendType" SG_ 2566749489 tellTaleStatus15_BASE 0;
BA_ "GenSigSendType" SG_ 2566749489 tellTaleStatus02_BASE 0;
BA_ "GenSigSendType" SG_ 2566803262 VDCinformationSignal_BASIS 0;
BA_ "GenSigSendType" SG_ 2566803262 ROPbrakeControlActive_BASIS 0;
BA_ "GenSigSendType" SG_ 2566803262 YCengineControlActive_BASIS 0;
BA_ "GenSigSendType" SG_ 2566803262 YCbrakeControlActive_BASIS 0;
BA_ "GenSigSendType" SG_ 2566803262 VDCfullyOperational_BASIS 0;
BA_ "GenSigSendType" SG_ 2566803262 VDCbrakeLightRequest_BASIS 0;
BA_ "GenSigSendType" SG_ 2566803262 ROPengineControlActive_BASIS 0;
BA_ "GenSigSendType" SG_ 2566613799 highVtgBusEPTOAvlblty_BASE 0;
BA_ "GenSigSendType" SG_ 2365346087 liftAxle1Status_BASE 0;
BA_ "GenSigSendType" SG_ 2566827275 brakePressHRfrontAxleLeftW_VAR1 0;
BA_ "GenSigSendType" SG_ 2566827275 brakePressHRrearAxle1leftW_VAR1 0;
BA_ "GenSigSendType" SG_ 2566827275 brakePressHRrearAxle1rightW_VAR1 0;
BA_ "GenSigSendType" SG_ 2566827275 brakePressHRrearAxle2leftW_VAR1 0;
BA_ "GenSigSendType" SG_ 2566827275 brakePressHRrearAxle2rightW_VAR1 0;
BA_ "GenSigSendType" SG_ 2566827275 brakePressHRrearAxle3leftW_VAR1 0;
BA_ "GenSigSendType" SG_ 2566827275 brakePressHRrearAxle3rightW_VAR1 0;
BA_ "GenSigSendType" SG_ 2566827275 brakePressHRfrontAxleRightW_VAR1 0;
BA_ "GenSigSendType" SG_ 2566767143 fuelType_BASE 0;
BA_ "GenSigSendType" SG_ 2364641930 HVESP1fastUpdateSOC_BASE 0;
BA_ "GenSigSendType" SG_ 2364641930 HVESP1HighestCellVoltage_BASE 0;
BA_ "GenSigSendType" SG_ 2364641930 HVESP1lowestCellVoltage_BASE 0;
BA_ "GenSigSendType" SG_ 2364645770 HVESP2fastUpdateSOC_BASE 0;
BA_ "GenSigSendType" SG_ 2364645770 HVESP2HighestCellVoltage_BASE 0;
BA_ "GenSigSendType" SG_ 2364645770 HVESP2lowestCellVoltage_BASE 0;
BA_ "GenSigSendType" SG_ 2364649610 HVESP3fastUpdateSOC_BASE 0;
BA_ "GenSigSendType" SG_ 2364649610 HVESP3HighestCellVoltage_BASE 0;
BA_ "GenSigSendType" SG_ 2364649610 HVESP3lowestCellVoltage_BASE 0;
BA_ "GenSigSendType" SG_ 2364657290 HVESP5fastUpdateSOC_BASE 0;
BA_ "GenSigSendType" SG_ 2364657290 HVESP5HighestCellVoltage_BASE 0;
BA_ "GenSigSendType" SG_ 2364657290 HVESP5lowestCellVoltage_BASE 0;
BA_ "GenSigSendType" SG_ 2364675722 HVESP7fastUpdateSOC_BASE 0;
BA_ "GenSigSendType" SG_ 2364675722 HVESP7HighestCellVoltage_BASE 0;
BA_ "GenSigSendType" SG_ 2364675722 HVESP7lowestCellVoltage_BASE 0;
BA_ "GenSigSendType" SG_ 2364653450 HVESP4fastUpdateSOC_BASE 0;
BA_ "GenSigSendType" SG_ 2364653450 HVESP4HighestCellVoltage_BASE 0;
BA_ "GenSigSendType" SG_ 2364653450 HVESP4lowestCellVoltage_BASE 0;
BA_ "GenSigSendType" SG_ 2364679562 HVESP8fastUpdateSOC_BASE 0;
BA_ "GenSigSendType" SG_ 2364679562 HVESP8HighestCellVoltage_BASE 0;
BA_ "GenSigSendType" SG_ 2364679562 HVESP8lowestCellVoltage_BASE 0;
BA_ "GenSigSendType" SG_ 2364661130 HVESP6fastUpdateSOC_BASE 0;
BA_ "GenSigSendType" SG_ 2364661130 HVESP6HighestCellVoltage_BASE 0;
BA_ "GenSigSendType" SG_ 2364661130 HVESP6lowestCellVoltage_BASE 0;
BA_ "GenSigSendType" SG_ 2566840592 retarderType_RD 0;
BA_ "GenSigSendType" SG_ 2566840592 percentTorqueAtPoint4_RD 0;
BA_ "GenSigSendType" SG_ 2566840592 retarderSpeedAtPeakTorqPoint5_RD 0;
BA_ "GenSigSendType" SG_ 2566840592 referenceRetarderTorque_RD 0;
BA_ "GenSigSendType" SG_ 2566840592 percentTorqAtPeakTorqPoint5_RD 0;
BA_ "GenSigSendType" SG_ 2566840592 retarderSpeedAtIdlePoint1_RD 0;
BA_ "GenSigSendType" SG_ 2566840592 percentTorqueAtIdlePoint1_RD 0;
BA_ "GenSigSendType" SG_ 2566840592 retarderLocation_RD 0;
BA_ "GenSigSendType" SG_ 2566840592 maximumRetarderSpeedPoint2_RD 0;
BA_ "GenSigSendType" SG_ 2566840592 percentTorqueAtMaxSpeedPoint2_RD 0;
BA_ "GenSigSendType" SG_ 2566840592 retarderSpeedAtPoint3_RD 0;
BA_ "GenSigSendType" SG_ 2566840592 retarderControlMethod_RD 0;
BA_ "GenSigSendType" SG_ 2566840592 percentTorqueAtPoint3_RD 0;
BA_ "GenSigSendType" SG_ 2566840592 retarderSpeedAtPoint4_RD 0;
BA_ "GenSigSendType" SG_ 2566847248 drivelineRetOverheatIndicator_RD 0;
BA_ "GenSigSendType" SG_ 2566847248 hydraulicOilTemperature_RD 0;
BA_ "GenSigSendType" SG_ 2566698791 hybridBatPackRemCharge_BASE 0;
BA_ "GenSigSendType" SG_ 2566545546 EVfullChargeTimeRemaining_BASE 0;
BA_ "GenSigSendType" SG_ 2600407299 maxCustEnergyTES_BASE 0;
BA_ "GenSigSendType" SG_ 2600407299 activationStateHVHTES_BASE 0;
BA_ "GenSigSendType" SG_ 2600407299 activationStateCoolSysTES_BASE 0;
BA_ "GenSigSendType" SG_ 2600407300 totalEnergyConsumption_BASE 0;
BA_ "GenSigSendType" SG_ 2600407300 HVESSintakeCoolantTemp_BASE 0;
BA_ "GenSigSendType" SG_ 2600407300 drvSysActv_BASE 0;
BA_ "GenSigSendType" SG_ 2600407297 HVESSstateOfHealth_BASE 0;
BA_ "GenSigSendType" SG_ 2600407297 HVESSmaxPackSOC_BASE 0;
BA_ "GenSigSendType" SG_ 2600407297 HVESSminPackSOC_BASE 0;
BA_ "GenSigSendType" SG_ 2600407301 reqInsideTemp1_BASE 0;
BA_ "GenSigSendType" SG_ 2600407301 brightnessAmbientLight_BASE 0;
BA_ "GenSigSendType" SG_ 2600407301 rainIntensity_BASE 0;
BA_ "GenSigSendType" SG_ 2600407301 schalterWischintervall_BASIS 0;
BA_ "GenSigSendType" SG_ 2600407301 reqInsideTemp2_BASE 0;
BA_ "GenSigSendType" SG_ 2565903754 HVESSintakeCoolantTemp_BASE 0;
BA_ "GenSigSendType" SG_ 2565903754 HVESStemperature_BASE 0;
BA_ "GenSigSendType" SG_ 2566866977 brightnessAmbientLight_BASE 0;
BA_ "GenSigSendType" SG_ 2566866977 rainIntensity_BASE 0;
BA_ "GenSigSendType" SG_ 2566866977 actWindscreenTemp_BASE 0;
BA_ "GenSigSendType" SG_ 2566866977 intAirHum_BASE 0;
BA_ "GenSigSendType" SG_ 2566866977 lightSwitchReason_BASE 0;
BA_ "GenSigSendType" SG_ 2566771850 oprtnKeySwIgnPow_BASE 0;
BA_ "GenSigSendType" SG_ 2364610442 lowSidePowerDCDC_BASE 0;
BA_ "GenSigSendType" SG_ 2364579978 HVESSdischgEnCpcty_BASE 0;
BA_ "GenSigSendType" SG_ 2633935883 brakeLineRemainFrontAxleLeftW_BA 1;
BA_ "GenSigSendType" SG_ 2633935883 brakeLineRemainRearAxle1leftW_BA 1;
BA_ "GenSigSendType" SG_ 2633935883 brakeLineRemainRearAxle1rightW_B 1;
BA_ "GenSigSendType" SG_ 2633935883 brakeLineRemainRearAxle2leftW_BA 1;
BA_ "GenSigSendType" SG_ 2633935883 brakeLineRemainRearAxle2rightW_B 1;
BA_ "GenSigSendType" SG_ 2633935883 brakeLineRemainRearAxle3leftW_BA 1;
BA_ "GenSigSendType" SG_ 2633935883 brakeLineRemainRearAxle3rightW_B 1;
BA_ "GenSigSendType" SG_ 2633935883 brakeLineRemainFrontAxleRightW_B 1;
BA_ "GenSigSendType" SG_ 2566842094 seconds_BASIS 0;
BA_ "GenSigSendType" SG_ 2566842094 hours_BASIS 0;
BA_ "GenSigSendType" SG_ 2566842094 month_BASIS 0;
BA_ "GenSigSendType" SG_ 2566842094 day_BASIS 0;
BA_ "GenSigSendType" SG_ 2566842094 year_BASIS 0;
BA_ "GenSigSendType" SG_ 2566842094 localMinuteOffset_BASIS 0;
BA_ "GenSigSendType" SG_ 2566842094 localHourOffset_BASIS 0;
BA_ "GenSigSendType" SG_ 2566842094 minutes_BASIS 0;
BA_ "GenSigSendType" SG_ 2583638092 appFrameworkAppID_BASE 3;
BA_ "GenSigSendType" SG_ 2583638092 appFrameworkAppState_BASE 3;
BA_ "GenSigSendType" SG_ 2564488174 UDSresp_DTCO2TBM 1;
BA_ "GenSigSendType" SG_ 2564430062 UDSresp_DTCO2CM4 1;
BA_ "GenSigSendType" SG_ 2600422183 frceAirflushActive_BASE 0;
BA_ "GenSigSendType" SG_ 2600422183 actPrkHtrProgData_BASE 0;
BA_ "GenSigSendType" SG_ 2600422183 reqSilentMode_BASE 0;
BA_ "GenSigSendType" SG_ 2600422183 washerPumpFront_BASE 0;
BA_ "GenSigSendType" SG_ 2600422183 eco24VshutOffReq_BASE 0;
BA_ "GenSigSendType" SG_ 2600422183 mainSwitchShutOffInfo_BASE 0;
BA_ "GenSigSendType" SG_ 2600422183 actForceReqAC_BASE 0;
BA_ "GenSigSendType" SG_ 2600422183 infoEmgcyShutOff_BASE 0;
BA_ "GenSigSendType" SG_ 2600422183 revGearHVAC_BASE 0;
BA_ "GenSigSendType" SG_ 2600422183 eco24VpwrSaveReq_BASE 0;
BA_ "GenSigSendType" SG_ 2600422183 egyModeHVAC_BASE 0;
BA_ "GenSigSendType" SG_ 2600422183 prkHtrEnabled_BASE 0;
BA_ "GenSigSendType" SG_ 2600422183 tempReduceCorrect_BASE 0;
BA_ "GenSigSendType" SG_ 2600422183 drvSysOff_BASE 0;
BA_ "GenSigSendType" SG_ 2600422183 wiperMotorFrontStep1_BASE 0;
BA_ "GenSigSendType" SG_ 2600422183 wiperMotorFrontStep2_BASE 0;
BA_ "GenSigSendType" SG_ 2600422183 stopStartActvnState_BASE 0;
BA_ "GenSigSendType" SG_ 2600422183 CVM13cntE2E_BASE 0;
BA_ "GenSigSendType" SG_ 2600422183 windscreenHeatingDisp_BASE 0;
BA_ "GenSigSendType" SG_ 2600422183 CVM13chkE2E_BASE 0;
BA_ "GenSigSendType" SG_ 2600422183 reqElManual_BASE 0;
BA_ "GenSigSendType" SG_ 2600460311 rmtTstrInstallMsgHeaderReq_BASE 3;
BA_ "GenSigSendType" SG_ 2600460311 rmtTstrInstallJobIdReq_BASE 3;
BA_ "GenSigSendType" SG_ 2600460311 rmtTstrInstallListIdxReq_BASE 3;
BA_ "GenSigSendType" SG_ 2600462375 selectedLanguage_BASE 0;
BA_ "GenSigSendType" SG_ 2364547840 A1SCRactDosingUreaQuantity_BASE 0;
BA_ "GenSigSendType" SG_ 2600403716 daytimeRunningLightLftPdf_BASE 0;
BA_ "GenSigSendType" SG_ 2600403716 lowBeamHeadLightLftPdf_BASE 0;
BA_ "GenSigSendType" SG_ 2600403716 lowBeamHeadLightRghPdf_BASE 0;
BA_ "GenSigSendType" SG_ 2600403716 corneringLightLeftPdf_BASE 0;
BA_ "GenSigSendType" SG_ 2600403716 corneringLightRightPdf_BASE 0;
BA_ "GenSigSendType" SG_ 2600403716 daytimeRunningLightRghPdf_BASE 0;
BA_ "GenSigSendType" SG_ 2566832622 highResolutionTotalVehDistance_B 0;
BA_ "GenSigSendType" SG_ 2566832622 highResolutionTripDistance_BASIS 0;
BA_ "GenSigSendType" SG_ 2566864167 AAF_MC2TBM 1;
BA_ "GenSigSendType" SG_ 2566864167 reihenfolge_MC2TBM 1;
BA_ "GenSigSendType" SG_ 2566864167 statusDaten_MC2TBM 1;
BA_ "GenSigSendType" SG_ 2566864167 qualitaetVorhanden_MC2TBM 1;
BA_ "GenSigSendType" SG_ 2566864167 qualitaetEmpfohlen_MC2TBM 1;
BA_ "GenSigSendType" SG_ 2566864167 BWI_MC2TBM 1;
BA_ "GenSigSendType" SG_ 2566864167 Wartungsinformation_MC2TBM 1;
BA_ "GenSigSendType" SG_ 2566864167 optimierung_MC2TBM 1;
BA_ "GenSigSendType" SG_ 2566864167 einheitDaten_MC2TBM 1;
BA_ "GenSigSendType" SG_ 2566864167 weitereTermine_MC2TBM 1;
BA_ "GenSigSendType" SG_ 2566864167 CID_MC2TBM 1;
BA_ "GenSigSendType" SG_ 2364642442 HVESP1dischargeCapacity_BASE 0;
BA_ "GenSigSendType" SG_ 2364646282 HVESP2dischargeCapacity_BASE 0;
BA_ "GenSigSendType" SG_ 2364650122 HVESP3dischargeCapacity_BASE 0;
BA_ "GenSigSendType" SG_ 2364661642 HVESP6dischargeCapacity_BASE 0;
BA_ "GenSigSendType" SG_ 2364653962 HVESP4dischargeCapacity_BASE 0;
BA_ "GenSigSendType" SG_ 2364657802 HVESP5dischargeCapacity_BASE 0;
BA_ "GenSigSendType" SG_ 2364676234 HVESP7dischargeCapacity_BASE 0;
BA_ "GenSigSendType" SG_ 2364680074 HVESP8dischargeCapacity_BASE 0;
BA_ "GenSigSendType" SG_ 2566749184 DPFactvRegenerationStatus_BASE 0;
BA_ "GenSigSendType" SG_ 2566749184 DPFstatus_BASE 0;
BA_ "GenSigSendType" SG_ 2566749184 DPFactvRgnrtnInhDue2InhSw_BASE 0;
BA_ "GenSigSendType" SG_ 2566749184 DPFactvRgnrtnInhDue2PTOActv_BASE 0;
BA_ "GenSigSendType" SG_ 2566749184 DPFactvRgnrtnInhDue2LowExhGasTmp 0;
BA_ "GenSigSendType" SG_ 2566749184 DPFactvRgnrtnInhDue2SysFaultActv 0;
BA_ "GenSigSendType" SG_ 2566749184 DPFactvRgnrtnInhDue2EngNotWarmUp 0;
BA_ "GenSigSendType" SG_ 2566749184 exhaustSysHighTempLampCommand_BA 0;
BA_ "GenSigSendType" SG_ 2566749184 DPFpassiveRegenerationStatus_BAS 0;
BA_ "GenSigSendType" SG_ 2566769953 frontNonoperatorWiperSwitch_BASE 0;
BA_ "GenSigSendType" SG_ 2566769953 rearWiperSwitch_BASE 0;
BA_ "GenSigSendType" SG_ 2566769953 frontOperatorWiperDelayControl_B 0;
BA_ "GenSigSendType" SG_ 2566769953 frontNonoperatorWiperDelayCtrl_B 0;
BA_ "GenSigSendType" SG_ 2566769953 rearWiperDelayControl_BASE 0;
BA_ "GenSigSendType" SG_ 2566769953 frontOperatorWiperSwitch_BASE 0;
BA_ "GenSigSendType" SG_ 2566769953 frontNonoperatorWasherSwitch_BAS 0;
BA_ "GenSigSendType" SG_ 2566769953 frontOperatorWasherSwitch_BASE 0;
BA_ "GenSigSendType" SG_ 2566769953 rearWasherFunction_BASE 0;
BA_ "GenSigSendType" SG_ 2566837553 alternatorSpeed_BASIS 0;
BA_ "GenSigSendType" SG_ 2566837553 alternator1Status_BASIS 0;
BA_ "GenSigSendType" SG_ 2566837553 alternator2Status_BASIS 0;
BA_ "GenSigSendType" SG_ 2566837553 alternator3Status_BASIS 0;
BA_ "GenSigSendType" SG_ 2566837553 alternator4Status_BASIS 0;
BA_ "GenSigSendType" SG_ 2566805551 bellowPressureFrontAxleLeft_ASC4 0;
BA_ "GenSigSendType" SG_ 2566805551 bellowPressureFrontAxleRight_ASC 0;
BA_ "GenSigSendType" SG_ 2566805551 bellowPressureRearAxleLeft_ASC4_ 0;
BA_ "GenSigSendType" SG_ 2566805551 bellowPressureRearAxleRight_ASC4 0;
BA_ "GenSigSendType" SG_ 2566803180 positionOfDoors_BASIS 0;
BA_ "GenSigSendType" SG_ 2566803180 rampWheelChairLiftPosition_BASIS 0;
BA_ "GenSigSendType" SG_ 2566803180 status2ofDoors_BASIS 0;
BA_ "GenSigSendType" SG_ 2566876928 bodyLength_BASE 0;
BA_ "GenSigSendType" SG_ 2566876928 bodyWidth_BASE 0;
BA_ "GenSigSendType" SG_ 2566876928 bodyHeight_BASE 0;
BA_ "GenSigSendType" SG_ 2566876928 passengerCapacity_BASE 0;
BA_ "GenSigSendType" SG_ 2566842151 totalVehicleHours_BASE 1;
BA_ "GenSigSendType" SG_ 2566842151 totalPowerTakeoffHours_BASE 1;
BA_ "GenSigSendType" SG_ 2600455183 BattPack4ActTemp_BASE 0;
BA_ "GenSigSendType" SG_ 2600455183 BattPack4Curr_BASE 0;
BA_ "GenSigSendType" SG_ 2600455183 BattPack4TechSoC_BASE 0;
BA_ "GenSigSendType" SG_ 2600455173 BattPack2InterResistDisch_BASE 0;
BA_ "GenSigSendType" SG_ 2600455173 BattPack2InterResistCh_BASE 0;
BA_ "GenSigSendType" SG_ 2600455173 BattPack2MaxTheorEnergy_BASE 0;
BA_ "GenSigSendType" SG_ 2600455173 BattPack2Vltg_BASE 0;
BA_ "GenSigSendType" SG_ 2600455173 BattPack2ActState_BASE 0;
BA_ "GenSigSendType" SG_ 2600455181 BattPack2ActTemp_BASE 0;
BA_ "GenSigSendType" SG_ 2600455181 BattPack2Curr_BASE 0;
BA_ "GenSigSendType" SG_ 2600455181 BattPack2TechSoC_BASE 0;
BA_ "GenSigSendType" SG_ 2600455177 BattPack6InterResistDisch_BASE 0;
BA_ "GenSigSendType" SG_ 2600455177 BattPack6InterResistCh_BASE 0;
BA_ "GenSigSendType" SG_ 2600455177 BattPack6MaxTheorEnergy_BASE 0;
BA_ "GenSigSendType" SG_ 2600455177 BattPack6Vltg_BASE 0;
BA_ "GenSigSendType" SG_ 2600455177 BattPack6ActState_BASE 0;
BA_ "GenSigSendType" SG_ 2600455185 BattPack6ActTemp_BASE 0;
BA_ "GenSigSendType" SG_ 2600455185 BattPack6Curr_BASE 0;
BA_ "GenSigSendType" SG_ 2600455185 BattPack6TechSoC_BASE 0;
BA_ "GenSigSendType" SG_ 2600455172 BattPack1InterResistDisch_BASE 0;
BA_ "GenSigSendType" SG_ 2600455172 BattPack1InterResistCh_BASE 0;
BA_ "GenSigSendType" SG_ 2600455172 BattPack1MaxTheorEnergy_BASE 0;
BA_ "GenSigSendType" SG_ 2600455172 BattPack1Vltg_BASE 0;
BA_ "GenSigSendType" SG_ 2600455172 BattPack1ActState_BASE 0;
BA_ "GenSigSendType" SG_ 2600455182 BattPack3ActTemp_BASE 0;
BA_ "GenSigSendType" SG_ 2600455182 BattPack3Curr_BASE 0;
BA_ "GenSigSendType" SG_ 2600455182 BattPack3TechSoC_BASE 0;
BA_ "GenSigSendType" SG_ 2600455179 BattPack8InterResistDisch_BASE 0;
BA_ "GenSigSendType" SG_ 2600455179 BattPack8InterResistCh_BASE 0;
BA_ "GenSigSendType" SG_ 2600455179 BattPack8MaxTheorEnergy_BASE 0;
BA_ "GenSigSendType" SG_ 2600455179 BattPack8Vltg_BASE 0;
BA_ "GenSigSendType" SG_ 2600455179 BattPack8ActState_BASE 0;
BA_ "GenSigSendType" SG_ 2600455178 BattPack7InterResistDisch_BASE 0;
BA_ "GenSigSendType" SG_ 2600455178 BattPack7InterResistCh_BASE 0;
BA_ "GenSigSendType" SG_ 2600455178 BattPack7MaxTheorEnergy_BASE 0;
BA_ "GenSigSendType" SG_ 2600455178 BattPack7Vltg_BASE 0;
BA_ "GenSigSendType" SG_ 2600455178 BattPack7ActState_BASE 0;
BA_ "GenSigSendType" SG_ 2600455176 BattPack5InterResistDisch_BASE 0;
BA_ "GenSigSendType" SG_ 2600455176 BattPack5InterResistCh_BASE 0;
BA_ "GenSigSendType" SG_ 2600455176 BattPack5MaxTheorEnergy_BASE 0;
BA_ "GenSigSendType" SG_ 2600455176 BattPack5Vltg_BASE 0;
BA_ "GenSigSendType" SG_ 2600455176 BattPack5ActState_BASE 0;
BA_ "GenSigSendType" SG_ 2600455180 BattPack1ActTemp_BASE 0;
BA_ "GenSigSendType" SG_ 2600455180 BattPack1Curr_BASE 0;
BA_ "GenSigSendType" SG_ 2600455180 BattPack1TechSoC_BASE 0;
BA_ "GenSigSendType" SG_ 2600455186 BattPack7ActTemp_BASE 0;
BA_ "GenSigSendType" SG_ 2600455186 BattPack7Curr_BASE 0;
BA_ "GenSigSendType" SG_ 2600455186 BattPack7TechSoC_BASE 0;
BA_ "GenSigSendType" SG_ 2600455171 SOCactualTES_BASE 0;
BA_ "GenSigSendType" SG_ 2600455171 stateMultiTES_BASE 0;
BA_ "GenSigSendType" SG_ 2600455171 internalResistChTES_BASE 0;
BA_ "GenSigSendType" SG_ 2600455171 internalResistDischTES_BASE 0;
BA_ "GenSigSendType" SG_ 2600455184 BattPack5ActTemp_BASE 0;
BA_ "GenSigSendType" SG_ 2600455184 BattPack5Curr_BASE 0;
BA_ "GenSigSendType" SG_ 2600455184 BattPack5TechSoC_BASE 0;
BA_ "GenSigSendType" SG_ 2600455175 BattPack4InterResistDisch_BASE 0;
BA_ "GenSigSendType" SG_ 2600455175 BattPack4InterResistCh_BASE 0;
BA_ "GenSigSendType" SG_ 2600455175 BattPack4MaxTheorEnergy_BASE 0;
BA_ "GenSigSendType" SG_ 2600455175 BattPack4Vltg_BASE 0;
BA_ "GenSigSendType" SG_ 2600455175 BattPack4ActState_BASE 0;
BA_ "GenSigSendType" SG_ 2600455187 BattPack8ActTemp_BASE 0;
BA_ "GenSigSendType" SG_ 2600455187 BattPack8Curr_BASE 0;
BA_ "GenSigSendType" SG_ 2600455187 BattPack8TechSoC_BASE 0;
BA_ "GenSigSendType" SG_ 2600455174 BattPack3InterResistDisch_BASE 0;
BA_ "GenSigSendType" SG_ 2600455174 BattPack3InterResistCh_BASE 0;
BA_ "GenSigSendType" SG_ 2600455174 BattPack3MaxTheorEnergy_BASE 0;
BA_ "GenSigSendType" SG_ 2600455174 BattPack3Vltg_BASE 0;
BA_ "GenSigSendType" SG_ 2600455174 BattPack3ActState_BASE 0;
BA_ "GenSigSendType" SG_ 2566846247 electricalPotential_BASIS 0;
BA_ "GenSigSendType" SG_ 2566843630 vehicleID_VAR1 0;
VAL_ 2600460568 rmtTstrDispCondC1gearNeut_BASE 0 "show condition not fullfilled" 1 "show condition fullfilled" 2 "error" 3 "not available";
VAL_ 2600460568 rmtTstrDispCondC1VehSpd_BASE 0 "show condition not fullfilled" 1 "show condition fullfilled" 2 "error" 3 "not available";
VAL_ 2600460568 rmtTstrDispCondC1ParkBrake_BASE 0 "show condition not fullfilled" 1 "show condition fullfilled" 2 "error" 3 "not available";
VAL_ 2600460568 rmtTstrDispCondC1engSpd_BASE 0 "show condition not fullfilled" 1 "show condition fullfilled" 2 "error" 3 "not available";
VAL_ 2600460568 rmtTstrDispCondIgnition_BASE 0 "show condition not fullfilled" 1 "show condition fullfilled" 2 "error" 3 "not available";
VAL_ 2600460568 rmtTstrDispCondOBD_BASE 0 "show condition not fullfilled" 1 "show condition fullfilled" 2 "error" 3 "not available";
VAL_ 2600460568 rmtTstrDispICLreset_BASE 0 "do not display" 1 "display" 2 "error" 3 "not available";
VAL_ 2600460568 rmtTstrDispUpdateAvail_BASE 0 "do not display" 1 "display" 2 "error" 3 "not available";
VAL_ 2600460568 rmtTstrDispCondEPTO_BASE 0 "show condition not fullfilled" 1 "show condition fullfilled" 2 "error" 3 "not available";
VAL_ 2600460568 rmtTstrDispCond24VBattChrg_BASE 0 "show condition not fulfilled" 1 "show condition fulfilled" 2 "error" 3 "not available";
VAL_ 2600460568 rmtTstrDispCondSecCerts_BASE 0 "show condition not fulfilled" 1 "show condition fulfilled" 2 "error" 3 "not available";
VAL_ 2600460568 rmtTstrDispCondCurrent_BASE 0 "show condition not fulfilled" 1 "show condition fulfilled" 2 "error" 3 "not available";
VAL_ 2600460568 rmtTstrDispAllowDriverExit_BASE 0 "not allowed" 1 "allowed" 2 "error" 3 "not available";
VAL_ 2600460568 rmtTstrDispCondExtrnlChrg_BASE 0 "show condition not fulfilled" 1 "show condition fulfilled" 2 "error" 3 "not available";
VAL_ 2600460568 rmtTstrOverrideCl15_BASE 0 "do not override driver ignition request" 1 "do override driver ignition request" 2 "error" 3 "not available";
VAL_ 2566834939 protectLampStatus_CM4_SAE 0 "lamp off" 1 "lamp on" 2 "reserved" 3 "don´t care";
VAL_ 2566834939 flashAmberWarningLamp_CM4_SAE 0 "Slow flash (1Hz)" 1 "Fast flash (>=2Hz)" 2 "Class C DTC (WWH OBD only)" 3 "unavailable/don't flash";
VAL_ 2566834939 flashRedStopLamp_CM4_SAE 0 "Slow flash (1Hz)" 1 "Fast flash (>=2Hz)" 2 "Class C DTC (WWH OBD only)" 3 "unavailable/don't flash";
VAL_ 2566834939 flashMalFunctionalIndicatorLamp_ 0 "Slow flash (1Hz)" 1 "Fast flash (>=2Hz)" 2 "Class C DTC (WWH OBD only)" 3 "unavailable/don't flash";
VAL_ 2566834939 amberWarningLamp_CM4_SAE 0 "lamp off" 1 "lamp on";
VAL_ 2566834939 redStopLamp_CM4_SAE 0 "lamp off" 1 "lamp on" 2 "reserved" 3 "don´t care";
VAL_ 2566834939 malfunctionIndicatorLamp_CM4_SAE 0 "lamp off" 1 "lamp on" 2 "reserved" 3 "don´t care";
VAL_ 2566834939 flashProtectLampStatus_CM4_SAE 0 "Slow flash (1Hz)" 1 "Fast flash (>=2Hz)" 2 "Class C DTC (WWH OBD only)" 3 "unavailable/don't flash";
VAL_ 2566535765 enableSwitchePTO1_BASE 0 "Enable switch off - ePTO operation not desired" 1 "Enable switch on - ePTO operation desired" 2 "Error" 3 "Not available";
VAL_ 2566535765 engageConsent_ePTO1_BASE 0 "Consent not given - ePTO should not be activated or engaged" 1 "Consent given - ePTO equipment may be activated or engaged" 2 "Error" 3 "Not available";
VAL_ 2566535765 engageStatus_ePTO1_BASE 0 "Drive not activated or engaged" 1 "Drive is activated or engaged" 2 "Error" 3 "Not available";
VAL_ 2566535765 emrgncyDeenSw_ePTO1_BASE 0 "Emergency De-energize not active" 1 "Emergency De-energize active - initiate shutdown" 2 "Error" 3 "Not available";
VAL_ 2566535765 systemRdnss_ePTO1_BASE 0 "ePTO not available due to system error" 1 "ePTO available" 2 "Reserved" 3 "Not available";
VAL_ 2566535765 errorIndicator_ePTO1_BASE 0 "no ePTO error detected or ePTO not enabled" 1 "ePTO error detected" 2 "Reserved" 3 "Not available";
VAL_ 2566535765 activeDischargeRequest_ePTO1_BAS 0 "no active discharge request" 1 "active discharge request" 2 "error" 3 "not available";
VAL_ 2566896981 bobuWiperFrontReq_BASE 0 "wiper off" 1 "wiper step 1" 2 "wiper step 2" 14 "error" 15 "not available";
VAL_ 2566896981 bobuFlashLightReq_BASE 0 "no request" 1 "request" 2 "error" 3 "not available";
VAL_ 2566896981 rightTurnSignalLightsCmd_BASE 0 "De-activate" 1 "Activate" 2 "Reserved" 3 "Don't Care";
VAL_ 2566896981 leftTurnSignalLightsCmd_BASE 0 "De-activate" 1 "Activate" 2 "Reserved" 3 "Don't Care";
VAL_ 2566896981 haltBrakeSwitch_BASIS 0 "halt brake switch passive" 1 "halt brake switch active" 2 "error" 3 "not available";
VAL_ 2566896981 parkBrkAppReqBB_BASE 0 "parking brake application not requested" 1 "parking brake application requested" 2 "error" 3 "not available";
VAL_ 2566896981 parkBrkRlsReqBB_BASE 0 "parking brake release not requested" 1 "parking brake release requested" 2 "error" 3 "not available";
VAL_ 2566896981 parkBrkRlsInhibitBB_BASE 0 "no inhibit active" 1 "inhibit auto release" 2 "inhibit auto and manual release" 10 "error" 11 "error" 12 "error" 13 "error" 14 "error" 15 "not availavle";
VAL_ 2566896981 bobuAlarmDriveLvl_BASE 0 "no alarm drive" 1 "alarm drive level 1" 2 "alarm drive level 2" 6 "error" 7 "not available";
VAL_ 2566897041 bobuWiperFrontReq_BASE 0 "wiper off" 1 "wiper step 1" 2 "wiper step 2" 14 "error" 15 "not available";
VAL_ 2566897041 bobuFlashLightReq_BASE 0 "no request" 1 "request" 2 "error" 3 "not available";
VAL_ 2566897041 rightTurnSignalLightsCmd_BASE 0 "De-activate" 1 "Activate" 2 "Reserved" 3 "Don't Care";
VAL_ 2566897041 leftTurnSignalLightsCmd_BASE 0 "De-activate" 1 "Activate" 2 "Reserved" 3 "Don't Care";
VAL_ 2566897041 haltBrakeSwitch_BASIS 0 "halt brake switch passive" 1 "halt brake switch active" 2 "error" 3 "not available";
VAL_ 2566897041 parkBrkAppReqBB_BASE 0 "parking brake application not requested" 1 "parking brake application requested" 2 "error" 3 "not available";
VAL_ 2566897041 parkBrkRlsReqBB_BASE 0 "parking brake release not requested" 1 "parking brake release requested" 2 "error" 3 "not available";
VAL_ 2566897041 parkBrkRlsInhibitBB_BASE 0 "no inhibit active" 1 "inhibit auto release" 2 "inhibit auto and manual release" 10 "error" 11 "error" 12 "error" 13 "error" 14 "error" 15 "not availavle";
VAL_ 2566897041 bobuAlarmDriveLvl_BASE 0 "no alarm drive" 1 "alarm drive level 1" 2 "alarm drive level 2" 6 "error" 7 "not available";
VAL_ 2566897040 bobuWiperFrontReq_BASE 0 "wiper off" 1 "wiper step 1" 2 "wiper step 2" 14 "error" 15 "not available";
VAL_ 2566897040 bobuFlashLightReq_BASE 0 "no request" 1 "request" 2 "error" 3 "not available";
VAL_ 2566897040 rightTurnSignalLightsCmd_BASE 0 "De-activate" 1 "Activate" 2 "Reserved" 3 "Don't Care";
VAL_ 2566897040 leftTurnSignalLightsCmd_BASE 0 "De-activate" 1 "Activate" 2 "Reserved" 3 "Don't Care";
VAL_ 2566897040 haltBrakeSwitch_BASIS 0 "halt brake switch passive" 1 "halt brake switch active" 2 "error" 3 "not available";
VAL_ 2566897040 parkBrkAppReqBB_BASE 0 "parking brake application not requested" 1 "parking brake application requested" 2 "error" 3 "not available";
VAL_ 2566897040 parkBrkRlsReqBB_BASE 0 "parking brake release not requested" 1 "parking brake release requested" 2 "error" 3 "not available";
VAL_ 2566897040 parkBrkRlsInhibitBB_BASE 0 "no inhibit active" 1 "inhibit auto release" 2 "inhibit auto and manual release" 10 "error" 11 "error" 12 "error" 13 "error" 14 "error" 15 "not availavle";
VAL_ 2566897040 bobuAlarmDriveLvl_BASE 0 "no alarm drive" 1 "alarm drive level 1" 2 "alarm drive level 2" 6 "error" 7 "not available";
VAL_ 2600454919 tmrMngmntTimerIndexOTAreq_BASE 0 "charging timer (not used for now)" 1 "comfort timer (remote HVAC)" 14 "error" 15 "not available";
VAL_ 2600454919 reqVehPrkChangeOTA_BASE 0 "no request" 1 "request";
VAL_ 2566838781 Kuehlwassertemperaturwarnung_BAS 0 "aus (Warnung aus)" 1 "ein (Warnung ein: Kühlwassertemperatur)" 2 "error" 3 "not available";
VAL_ 2566838781 Oeldruckwarnung_BASIS 0 "aus (Warnung aus)" 1 "ein (Warnung ein: Öldruck zu niedrig)" 2 "error" 3 "not available";
VAL_ 2566759916 lockStatusOfDoor1_BASIS 0 "unlocked" 1 "locked" 2 "error" 3 "not available";
VAL_ 2566759916 enableStatusOfDoor2_BASIS 0 "door disabled" 1 "door enabled" 2 "error" 3 "not available";
VAL_ 2566759916 lockStatusOfDoor3_BASIS 0 "unlocked" 1 "locked" 2 "error" 3 "not available";
VAL_ 2566759916 openStatusOfDoor3_BASIS 0 "closed" 1 "opened" 2 "error" 3 "not available";
VAL_ 2566759916 enableStatusOfDoor3_BASIS 0 "door disabled" 1 "door enabled" 2 "error" 3 "not available";
VAL_ 2566759916 lockStatusOfDoor4_BASIS 0 "unlocked" 1 "locked" 2 "error" 3 "not available";
VAL_ 2566759916 openStatusOfDoor1_BASIS 0 "closed" 1 "opened" 2 "error" 3 "not available";
VAL_ 2566759916 openStatusOfDoor4_BASIS 0 "closed" 1 "opened" 2 "error" 3 "not available";
VAL_ 2566759916 enableStatusOfDoor4_BASIS 0 "door disabled" 1 "door enabled" 2 "error" 3 "not available";
VAL_ 2566759916 lockStatusOfDoor5_BASIS 0 "unlocked" 1 "locked" 2 "error" 3 "not available";
VAL_ 2566759916 openStatusOfDoor5_BASIS 0 "closed" 1 "opened" 2 "error" 3 "not available";
VAL_ 2566759916 enableStatusOfDoor5_BASIS 0 "door disabled" 1 "door enabled" 2 "error" 3 "not available";
VAL_ 2566759916 lockStatusOfDoor6_BASIS 0 "unlocked" 1 "locked" 2 "error" 3 "not available";
VAL_ 2566759916 openStatusOfDoor6_BASIS 0 "closed" 1 "opened" 2 "error" 3 "not available";
VAL_ 2566759916 enableStatusOfDoor6_BASIS 0 "door disabled" 1 "door enabled" 2 "error" 3 "not available";
VAL_ 2566759916 lockStatusOfDoor7_BASIS 0 "unlocked" 1 "locked" 2 "error" 3 "not available";
VAL_ 2566759916 openStatusOfDoor7_BASIS 0 "closed" 1 "opened" 2 "error" 3 "not available";
VAL_ 2566759916 enableStatusOfDoor1_BASIS 0 "door disabled" 1 "door enabled" 2 "error" 3 "not available";
VAL_ 2566759916 enableStatusOfDoor7_BASIS 0 "door disabled" 1 "door enabled" 2 "error" 3 "not available";
VAL_ 2566759916 lockStatusOfDoor8_BASIS 0 "unlocked" 1 "locked" 2 "error" 3 "not available";
VAL_ 2566759916 openStatusOfDoor8_BASIS 0 "closed" 1 "opened" 2 "error" 3 "not available";
VAL_ 2566759916 enableStatusOfDoor8_BASIS 0 "door disabled" 1 "door enabled" 2 "error" 3 "not available";
VAL_ 2566759916 lockStatusOfDoor9_BASIS 0 "unlocked" 1 "locked" 2 "error" 3 "not available";
VAL_ 2566759916 openStatusOfDoor9_BASIS 0 "closed" 1 "opened" 2 "error" 3 "not available";
VAL_ 2566759916 enableStatusOfDoor9_BASIS 0 "door disabled" 1 "door enabled" 2 "error" 3 "not available";
VAL_ 2566759916 lockStatusOfDoor10_BASIS 0 "unlocked" 1 "locked" 2 "error" 3 "not available";
VAL_ 2566759916 openStatusOfDoor10_BASIS 0 "closed" 1 "opened" 2 "error" 3 "not available";
VAL_ 2566759916 enableStatusOfDoor10_BASIS 0 "door disabled" 1 "door enabled" 2 "error" 3 "not available";
VAL_ 2566759916 lockStatusOfDoor2_BASIS 0 "unlocked" 1 "locked" 2 "error" 3 "not available";
VAL_ 2566759916 openStatusOfDoor2_BASIS 0 "closed" 1 "opened" 2 "error" 3 "not available";
VAL_ 2566767627 brakeTemperatureWarning_BASE 0 "Not active" 1 "active" 2 "error" 3 "not available";
VAL_ 2566767627 XBRsystemState_BASIS 0 "Any external brake demand will be accepted (brake system fully operational)" 1 "Only external brake demand of highest XBR Priority (00) will be accepted (e.g. because the temperature limit of the brake system is exceeded)" 2 "No external brake demand will be accepted (e.g. because of fault in brake system)" 3 "not available";
VAL_ 2566767627 XBRactiveControlMode_BASIS 0 "No brake demand being executed (default mode)" 1 "Driver's brake demand being executed, no external brake demand" 2 "Addition mode of XBR acceleration control being executed" 3 "Maximum mode of XBR acceleration control being executed" 15 "not available";
VAL_ 2566767627 haltBrakeMode_BASIS 0 "inactive" 1 "active" 2 "active, but not functioning properly" 6 "reserved" 7 "not available";
VAL_ 2566767627 parkBrakeActuatorFullyActivated_ 0 "Parking Brake Actuator not fully activated" 1 "Parking Brake Actuator fully activated" 2 "Error" 3 "Not available";
VAL_ 2566767627 emergencyBrakingActive_BASE 0 "Emergency brake signal not active" 1 "Emergency brake signal active" 2 "error" 3 "not available";
VAL_ 2566767627 hillHolderMode_BASIS 0 "inactive" 1 "active" 2 "active, but will change to inactive in a short time" 6 "hill holder not functional" 7 "not available";
VAL_ 2566767627 foundationBrakeUse_BASIS 0 "Foundation Brakes not in use" 1 "Foundation_Brakes in use" 2 "reserved" 3 "not available";
VAL_ 2566833352 vehicleABSactivePassive_T1_TO_TR 0 "Vehicle ABS passive, but installed" 1 "Vehicle ABS active";
VAL_ 2566833352 redWarningSignalRequest_T1_TO_TR 0 "No towed vehicle failure to be indicated by the red warning signal" 1 "Towed vehicle failure to be indicated by the red warning signal" 2 "reserved" 3 "take no action";
VAL_ 2566833352 amberWarningSignalRequest_T1_TO_ 0 "No towed vehicle failure to be indicated by the amber warning signal" 1 "Towed vehicle failure to be indicated by the amber warning signal" 2 "reserved" 3 "take no action";
VAL_ 2566833352 electricalSupplyOfNonBrakingSyst 0 "Supply of non-braking systems switched off" 1 "Supply of non-braking systems switched on" 2 "error" 3 "not available";
VAL_ 2566833352 springBrakeInstalled_T1_TO_TRUCK 0 "Vehicle without spring brakes" 1 "Vehicle with spring brakes" 2 "error" 3 "not available";
VAL_ 2566833352 electrLoadProportionalFunc_T1_TO 0 "Vehicle without electrical load proportional function" 1 "Vehicle with electrical load proportional function";
VAL_ 2566833352 vehicleRetContrActivePassive_T1_ 0 "retarder passive" 1 "retarder active";
VAL_ 2566833352 vehicleType_T1_TO_TRUCK_EBS22 0 "Towing or towed vehicle" 1 "Dolly axle" 2 "error indicator" 3 "not available";
VAL_ 2566833352 springBrakeEngaged_T1_TO_TRUCK 0 "Vehicle spring brake is released (is not braking the vehicle)" 1 "Vehicle spring brake is engaged (is braking the vehicle)" 2 "error" 3 "not available";
VAL_ 2566833352 loadingRampApproachAssistance_T1 0 "Loading ramp approach assistance not active" 1 "Loading ramp approach assistance active" 2 "error" 3 "not available";
VAL_ 2566833352 supplylineBrakingRequest_T1_TO_T 0 "No supply line braking request" 1 "Supply line braking request" 2 "reserved" 3 "take no action";
VAL_ 2566833352 stopLampsRequest_BASE 0 "No request to illuminate stop lamps" 1 "Request to illuminate stop lamps";
VAL_ 2566833352 electricCtrlLineBrkngSuprt_BASE 0 "Braking via electric control line not supported" 1 "Braking via electric control line supported";
VAL_ 2566833352 vehicleServiceBrakeActPass_T1_TO 0 "Vehicle service brake passive" 1 "Vehicle service brake active" 2 "error" 3 "not available";
VAL_ 2566833352 automaticTowedVehicleBrake_T1_TO 0 "Vehicle automatic braking passive" 1 "Vehicle automatic braking active" 2 "error" 3 "not available";
VAL_ 2566833352 vehicleElectricalSupply_T1_TO_TR 0 "Vehicle electrical supply insufficient" 1 "Vehicle electrical supply sufficient" 2 "error" 3 "not available";
VAL_ 2364539395 drivelineEngaged_BASIS 0 "driveline disengaged" 1 "driveline engaged" 2 "error" 3 "not available";
VAL_ 2364539395 torqueConverterLockupEngaged_BAS 0 "Torque converter lockup disengaged" 1 "Torque converter lockup engaged" 2 "Error" 3 "not available";
VAL_ 2364539395 engineMomentaryOverspeedEnable_B 0 "Momentary engine overspeed is disable" 1 "Momentary engine overspeed is enable" 2 "error" 3 "not available";
VAL_ 2364539395 progressiveShiftDisable_BASIS 0 "Progressive shift is not disabled" 1 "Progressive shift is disabled" 3 "Take no action";
VAL_ 2364539395 PTO2permission_BASIS 0 "not allowed" 1 "allowed" 2 "reserved" 3 "don't care / take no action";
VAL_ 2364539395 PTO1permission_BASIS 0 "not allowed" 1 "allowed" 2 "reserved" 3 "don't care / take no action";
VAL_ 2364539395 shiftInProcess_BASIS 0 "shift is not in process" 1 "shift in process" 2 "error" 3 "not available";
VAL_ 2633880061 FMSstandardDiagnosticsSupported_ 0 "Diagnostics Is Not Supported" 1 "Diagnostics Is Supported" 2 "Reserved" 3 "Don't care";
VAL_ 2633880061 FMSstandardRequestsSupported_BAS 0 "On request mode is not supported" 1 "On request mode is supported" 2 "Reserved" 3 "Don't care";
VAL_ 2365443111 turnSignalSwitch_BASE 0 "No Turn being signaled" 1 "Left Turn to be Flashing" 2 "Right turn to be Flashing" 3 "0011 - 1101 Reserved" 14 "Error (to include both left and right selected simultaneously)" 15 "Not available (do not change)";
VAL_ 2365484270 driver1workingState_BASIS 0 "Rest - sleeping" 1 "Driver available - short break" 2 "Work - loading, unloading, working in an office" 3 "Drive - behind wheel" 6 "Error" 7 "Not available";
VAL_ 2365484270 driverCard1_BASIS 0 "Driver card not present" 1 "Driver card present" 2 "Error" 3 "Not available";
VAL_ 2365484270 overspeed_BASIS 0 "no overspeed" 1 "overspeed" 2 "error" 3 "not available";
VAL_ 2365484270 driver2timeRelatedStates_BASIS 0 "no time related warning detected" 1 "reserved" 2 "reserved" 3 "reserved" 4 "reserved" 5 "daily/weekly rest pre-warning active" 6 "daily/weekly rest warning active" 7 "reserved" 8 "reserved" 9 "reserved" 10 "reserved" 11 "driver 2 card expiry warning active" 12 "next mandatory driver 2 card download warning active" 13 "other" 14 "error" 15 "not available";
VAL_ 2365484270 driverCard2_BASIS 0 "Driver card not present" 1 "Driver card present" 2 "Error" 3 "Not available";
VAL_ 2365484270 systemEvent_BASIS 0 "no tachograph event" 1 "tachograph event" 2 "error" 3 "not available";
VAL_ 2365484270 handlingInformation_BASIS 0 "no handling information" 1 "handling information" 2 "Error" 3 "Not available";
VAL_ 2365484270 tachographPerformance_BASIS 0 "normal performance" 1 "performance analysis" 2 "error" 3 "not available";
VAL_ 2365484270 driver2workingState_BASIS 0 "Rest - sleeping" 1 "Driver available - short break" 2 "Work - loading, unloading, working in an office" 3 "Drive - behind wheel" 6 "Error" 7 "Not available";
VAL_ 2365484270 directionIndicator_BASIS 0 "forward" 1 "reverse" 2 "error" 3 "not available";
VAL_ 2365484270 driveRecognize_BASIS 0 "Vehicle motion not detected" 1 "Vehicle motion detected" 2 "Error" 3 "Not available";
VAL_ 2365484270 driver1timeRelatedStates_BASIS 0 "Normal/No limits reached" 1 "continuous driving time pre-warning active (15 min before 4h30)" 2 "continuous driving time warning active (4h30 exceeded)" 3 "daily driving time pre-warning active (daily driving time above 9h, or above maximum allowed daily driving time)riving time)" 4 "daily driving time warning active (daily driving time above 9h, or above maximum allowed daily driving time)" 5 "daily/weekly rest pre-warning active" 6 "daily/weekly rest warning active" 7 "weekly driving time pre-warning active" 8 "weekly driving time warning active" 9 "2 weeks driving time pre-warning active" 10 "2 weeks driving time warning active" 11 "driver 1 card expiry warning active" 12 "next mandatory driver 1 card download warning active" 13 "other" 14 "error" 15 "not available";
VAL_ 2566806728 tyreWheelIdentification_BASIS 0 "wheel position undefined, axle position undefined" 1 "wheel position 1, axle position undefined" 2 "wheel position 2, axle position undefined" 3 "wheel position 3, axle position undefined" 4 "wheel position 4, axle position undefined" 5 "wheel position 5, axle position undefined" 6 "wheel position 6, axle position undefined" 7 "wheel position 7, axle position undefined" 8 "wheel position 8, axle position undefined" 9 "wheel position 9, axle position undefined" 10 "wheel position 10, axle position undefined" 11 "wheel position 11, axle position undefined" 12 "wheel position 12, axle position undefined" 13 "wheel position 13, axle position undefined" 14 "wheel position 14, axle position undefined" 15 "wheel position 15, axle position undefined" 16 "wheel position undefined, axle position 1" 17 "wheel position 1, axle position 1" 18 "wheel position 2, axle position 1" 19 "wheel position 3, axle position 1" 20 "wheel position 4, axle position 1" 21 "wheel position 5, axle position 1" 22 "wheel position 6, axle position 1" 23 "wheel position 7, axle position 1" 24 "wheel position 8, axle position 1" 25 "wheel position 9, axle position 1" 26 "wheel position 10, axle position 1" 27 "wheel position 11, axle position 1" 28 "wheel position 12, axle position 1" 29 "wheel position 13, axle position 1" 30 "wheel position 14, axle position 1" 31 "wheel position 15, axle position 1" 32 "wheel position undefined, axle position 2" 33 "wheel position 1, axle position 2" 34 "wheel position 2, axle position 2" 35 "wheel position 3, axle position 2" 36 "wheel position 4, axle position 2" 37 "wheel position 5, axle position 2" 38 "wheel position 6, axle position 2" 39 "wheel position 7, axle position 2" 40 "wheel position 8, axle position 2" 41 "wheel position 9, axle position 2" 42 "wheel position 10, axle position 2" 43 "wheel position 11, axle position 2" 44 "wheel position 12, axle position 2" 45 "wheel position 13, axle position 2" 46 "wheel position 14, axle position 2" 47 "wheel position 15, axle position 2" 48 "wheel position undefined, axle position 3" 49 "wheel position 1, axle position 3" 50 "wheel position 2, axle position 3" 51 "wheel position 3, axle position 3" 52 "wheel position 4, axle position 3" 53 "wheel position 5, axle position 3" 54 "wheel position 6, axle position 3" 55 "wheel position 7, axle position 3" 56 "wheel position 8, axle position 3" 57 "wheel position 9, axle position 3" 58 "wheel position 10, axle position 3" 59 "wheel position 11, axle position 3" 60 "wheel position 12, axle position 3" 61 "wheel position 13, axle position 3" 62 "wheel position 14, axle position 3" 63 "wheel position 15, axle position 3" 64 "wheel position undefined, axle position 4" 65 "wheel position 1, axle position 4" 66 "wheel position 2, axle position 4" 67 "wheel position 3, axle position 4" 68 "wheel position 4, axle position 4" 69 "wheel position 5, axle position 4" 70 "wheel position 6, axle position 4" 71 "wheel position 7, axle position 4" 72 "wheel position 8, axle position 4" 73 "wheel position 9, axle position 4" 74 "wheel position 10, axle position 4" 75 "wheel position 11, axle position 4" 76 "wheel position 12, axle position 4" 77 "wheel position 13, axle position 4" 78 "wheel position 14, axle position 4" 79 "wheel position 15, axle position 4" 80 "wheel position undefined, axle position 5" 81 "wheel position 1, axle position 5" 82 "wheel position 2, axle position 5" 83 "wheel position 3, axle position 5" 84 "wheel position 4, axle position 5" 85 "wheel position 5, axle position 5" 86 "wheel position 6, axle position 5" 87 "wheel position 7, axle position 5" 88 "wheel position 8, axle position 5" 89 "wheel position 9, axle position 5" 90 "wheel position 10, axle position 5" 91 "wheel position 11, axle position 5" 92 "wheel position 12, axle position 5" 93 "wheel position 13, axle position 5" 94 "wheel position 14, axle position 5" 95 "wheel position 15, axle position 5" 96 "wheel position undefined, axle position 6" 97 "wheel position 1, axle position 6" 98 "wheel position 2, axle position 6" 99 "wheel position 3, axle position 6" 100 "wheel position 4, axle position 6" 101 "wheel position 5, axle position 6" 102 "wheel position 6, axle position 6" 103 "wheel position 7, axle position 6" 104 "wheel position 8, axle position 6" 105 "wheel position 9, axle position 6" 106 "wheel position 10, axle position 6" 107 "wheel position 11, axle position 6" 108 "wheel position 12, axle position 6" 109 "wheel position 13, axle position 6" 110 "wheel position 14, axle position 6" 111 "wheel position 15, axle position 6" 112 "wheel position undefined, axle position 7" 113 "wheel position 1, axle position 7" 114 "wheel position 2, axle position 7" 115 "wheel position 3, axle position 7" 116 "wheel position 4, axle position 7" 117 "wheel position 5, axle position 7" 118 "wheel position 6, axle position 7" 119 "wheel position 7, axle position 7" 120 "wheel position 8, axle position 7" 121 "wheel position 9, axle position 7" 122 "wheel position 10, axle position 7" 123 "wheel position 11, axle position 7" 124 "wheel position 12, axle position 7" 125 "wheel position 13, axle position 7" 126 "wheel position 14, axle position 7" 127 "wheel position 15, axle position 7" 128 "wheel position undefined, axle position 8" 129 "wheel position 1, axle position 8" 130 "wheel position 2, axle position 8" 131 "wheel position 3, axle position 8" 132 "wheel position 4, axle position 8" 133 "wheel position 5, axle position 8" 134 "wheel position 6, axle position 8" 135 "wheel position 7, axle position 8" 136 "wheel position 8, axle position 8" 137 "wheel position 9, axle position 8" 138 "wheel position 10, axle position 8" 139 "wheel position 11, axle position 8" 140 "wheel position 12, axle position 8" 141 "wheel position 13, axle position 8" 142 "wheel position 14, axle position 8" 143 "wheel position 15, axle position 8" 144 "wheel position undefined, axle position 9" 145 "wheel position 1, axle position 9" 146 "wheel position 2, axle position 9" 147 "wheel position 3, axle position 9" 148 "wheel position 4, axle position 9" 149 "wheel position 5, axle position 9" 150 "wheel position 6, axle position 9" 151 "wheel position 7, axle position 9" 152 "wheel position 8, axle position 9" 153 "wheel position 9, axle position 9" 154 "wheel position 10, axle position 9" 155 "wheel position 11, axle position 9" 156 "wheel position 12, axle position 9" 157 "wheel position 13, axle position 9" 158 "wheel position 14, axle position 9" 159 "wheel position 15, axle position 9" 160 "wheel position undefined, axle position 10" 161 "wheel position 1, axle position 10" 162 "wheel position 2, axle position 10" 163 "wheel position 3, axle position 10" 164 "wheel position 4, axle position 10" 165 "wheel position 5, axle position 10" 166 "wheel position 6, axle position 10" 167 "wheel position 7, axle position 10" 168 "wheel position 8, axle position 10" 169 "wheel position 9, axle position 10" 170 "wheel position 10, axle position 10" 171 "wheel position 11, axle position 10" 172 "wheel position 12, axle position 10" 173 "wheel position 13, axle position 10" 174 "wheel position 14, axle position 10" 175 "wheel position 15, axle position 10" 176 "wheel position undefined, axle position 11" 177 "wheel position 1, axle position 11" 178 "wheel position 2, axle position 11" 179 "wheel position 3, axle position 11" 180 "wheel position 4, axle position 11" 181 "wheel position 5, axle position 11" 182 "wheel position 6, axle position 11" 183 "wheel position 7, axle position 11" 184 "wheel position 8, axle position 11" 185 "wheel position 9, axle position 11" 186 "wheel position 10, axle position 11" 187 "wheel position 11, axle position 11" 188 "wheel position 12, axle position 11" 189 "wheel position 13, axle position 11" 190 "wheel position 14, axle position 11" 191 "wheel position 15, axle position 11" 192 "wheel position undefined, axle position 12" 193 "wheel position 1, axle position 12" 194 "wheel position 2, axle position 12" 195 "wheel position 3, axle position 12" 196 "wheel position 4, axle position 12" 197 "wheel position 5, axle position 12" 198 "wheel position 6, axle position 12" 199 "wheel position 7, axle position 12" 200 "wheel position 8, axle position 12" 201 "wheel position 9, axle position 12" 202 "wheel position 10, axle position 12" 203 "wheel position 11, axle position 12" 204 "wheel position 12, axle position 12" 205 "wheel position 13, axle position 12" 206 "wheel position 14, axle position 12" 207 "wheel position 15, axle position 12" 208 "wheel position undefined, axle position 13" 209 "wheel position 1, axle position 13" 210 "wheel position 2, axle position 13" 211 "wheel position 3, axle position 13" 212 "wheel position 4, axle position 13" 213 "wheel position 5, axle position 13" 214 "wheel position 6, axle position 13" 215 "wheel position 7, axle position 13" 216 "wheel position 8, axle position 13" 217 "wheel position 9, axle position 13" 218 "wheel position 10, axle position 13" 219 "wheel position 11, axle position 13" 220 "wheel position 12, axle position 13" 221 "wheel position 13, axle position 13" 222 "wheel position 14, axle position 13" 223 "wheel position 15, axle position 13" 224 "wheel position undefined, axle position 14" 225 "wheel position 1, axle position 14" 226 "wheel position 2, axle position 14" 227 "wheel position 3, axle position 14" 228 "wheel position 4, axle position 14" 229 "wheel position 5, axle position 14" 230 "wheel position 6, axle position 14" 231 "wheel position 7, axle position 14" 232 "wheel position 8, axle position 14" 233 "wheel position 9, axle position 14" 234 "wheel position 10, axle position 14" 235 "wheel position 11, axle position 14" 236 "wheel position 12, axle position 14" 237 "wheel position 13, axle position 14" 238 "wheel position 14, axle position 14" 239 "wheel position 15, axle position 14" 240 "wheel position undefined, axle position 15" 241 "wheel position 1, axle position 15" 242 "wheel position 2, axle position 15" 243 "wheel position 3, axle position 15" 244 "wheel position 4, axle position 15" 245 "wheel position 5, axle position 15" 246 "wheel position 6, axle position 15" 247 "wheel position 7, axle position 15" 248 "wheel position 8, axle position 15" 249 "wheel position 9, axle position 15" 250 "wheel position 10, axle position 15" 251 "wheel position 11, axle position 15" 252 "wheel position 12, axle position 15" 253 "wheel position 13, axle position 15" 254 "wheel position 14, axle position 15" 255 "wheel position 15, axle position 15";
VAL_ 2565870375 pitchAngleFigureofMerit_SAE 0 "Pitch angle fully functional. Data is within sensor specification." 1 "Pitch angle degraded. Data is suspect due to environmental conditions." 2 "error" 3 "not available";
VAL_ 2565870375 rollAngleFigureofMerit_SAE 0 "Roll angle fully functional. Data is within sensor specification." 1 "Roll angle degraded. Data is suspect due to environmental conditions." 2 "error" 3 "not available";
VAL_ 2566749489 tellTaleStatus03_BASE 0 "Off" 1 "Condition Red" 2 "Condition Yellow" 3 "Condition Info" 4 "Reserved" 5 "Reserved" 6 "Reserved" 7 "Not available";
VAL_ 2566749489 tellTaleStatus04_BASE 0 "Off" 1 "Condition Red" 2 "Condition Yellow" 3 "Condition Info" 4 "Reserved" 5 "Reserved" 6 "Reserved" 7 "Not available";
VAL_ 2566749489 tellTaleStatus05_BASE 0 "Off" 1 "Condition Red" 2 "Condition Yellow" 3 "Condition Info" 4 "Reserved" 5 "Reserved" 6 "Reserved" 7 "Not available";
VAL_ 2566749489 tellTaleStatus06_BASE 0 "Off" 1 "Condition Red" 2 "Condition Yellow" 3 "Condition Info" 4 "Reserved" 5 "Reserved" 6 "Reserved" 7 "Not available";
VAL_ 2566749489 tellTaleStatus07_BASE 0 "Off" 1 "Condition Red" 2 "Condition Yellow" 3 "Condition Info" 4 "Reserved" 5 "Reserved" 6 "Reserved" 7 "Not available";
VAL_ 2566749489 tellTaleStatus08_BASE 0 "Off" 1 "Condition Red" 2 "Condition Yellow" 3 "Condition Info" 4 "Reserved" 5 "Reserved" 6 "Reserved" 7 "Not available";
VAL_ 2566749489 tellTaleStatus09_BASE 0 "Off" 1 "Condition Red" 2 "Condition Yellow" 3 "Condition Info" 4 "Reserved" 5 "Reserved" 6 "Reserved" 7 "Not available";
VAL_ 2566749489 tellTaleStatus01_BASE 0 "Off" 1 "Condition Red" 2 "Condition Yellow" 3 "Condition Info" 4 "Reserved" 5 "Reserved" 6 "Reserved" 7 "Not available";
VAL_ 2566749489 tellTaleStatus10_BASE 0 "Off" 1 "Condition Red" 2 "Condition Yellow" 3 "Condition Info" 4 "Reserved" 5 "Reserved" 6 "Reserved" 7 "Not available";
VAL_ 2566749489 tellTaleStatus11_BASE 0 "Off" 1 "Condition Red" 2 "Condition Yellow" 3 "Condition Info" 4 "Reserved" 5 "Reserved" 6 "Reserved" 7 "Not available";
VAL_ 2566749489 tellTaleStatus12_BASE 0 "Off" 1 "Condition Red" 2 "Condition Yellow" 3 "Condition Info" 4 "Reserved" 5 "Reserved" 6 "Reserved" 7 "Not available";
VAL_ 2566749489 tellTaleStatus13_BASE 0 "Off" 1 "Condition Red" 2 "Condition Yellow" 3 "Condition Info" 4 "Reserved" 5 "Reserved" 6 "Reserved" 7 "Not available";
VAL_ 2566749489 tellTaleStatus14_BASE 0 "Off" 1 "Condition Red" 2 "Condition Yellow" 3 "Condition Info" 4 "Reserved" 5 "Reserved" 6 "Reserved" 7 "Not available";
VAL_ 2566749489 tellTaleStatus15_BASE 0 "Off" 1 "Condition Red" 2 "Condition Yellow" 3 "Condition Info" 4 "Reserved" 5 "Reserved" 6 "Reserved" 7 "Not available";
VAL_ 2566749489 tellTaleStatus02_BASE 0 "Off" 1 "Condition Red" 2 "Condition Yellow" 3 "Condition Info" 4 "Reserved" 5 "Reserved" 6 "Reserved" 7 "Not available";
VAL_ 2566803262 VDCinformationSignal_BASIS 0 "Off" 1 "On" 2 "reserved" 3 "Don't care/Take no action";
VAL_ 2566803262 ROPbrakeControlActive_BASIS 0 "ROP Brake control passive but installed" 1 "ROP Brake Control active" 2 "reserved" 3 "Don't care/Take no action";
VAL_ 2566803262 YCengineControlActive_BASIS 0 "YC engine control passive but installed" 1 "YC engine control active" 2 "reserved" 3 "Don't care/Take no action";
VAL_ 2566803262 YCbrakeControlActive_BASIS 0 "YC brake control passive but installed" 1 "YC brake control active" 2 "reserved" 3 "Don't care/Take no action";
VAL_ 2566803262 VDCfullyOperational_BASIS 0 "Not fully operational" 1 "Fully operational" 2 "reserved" 3 "Don't care/Take no action";
VAL_ 2566803262 VDCbrakeLightRequest_BASIS 0 "Turn brake light not on" 1 "Turn brake light on" 2 "reserved" 3 "Don't care/Take no action";
VAL_ 2566803262 ROPengineControlActive_BASIS 0 "ROP engine control passive but installed" 1 "ROP Engine Control active" 2 "reserved" 3 "Don't care/Take no action";
VAL_ 2566613799 highVtgBusEPTOAvlblty_BASE 0 "High voltage DC bus is not connected." 1 "High voltage DC bus is connected." 2 "High voltage DC bus connection is in process of being connected." 3 "High voltage DC bus disconnection is in process.   Devices on the bus should take appropriate action." 4 "SAE Reserved 1" 5 "High voltage DC bus disconnect forewarning.  Disconnection is imminent." 6 "SAE Reserved 2" 7 "SAE Reserved 3" 8 "SAE Reserved 4" 9 "SAE Reserved 5" 10 "SAE Reserved 6" 11 "SAE Reserved 7" 12 "SAE Reserved 8" 13 "SAE Reserved 9" 14 "error" 15 "not available";
VAL_ 2365346087 liftAxle1Status_BASE 0 "down, tag axle is laden" 1 "unloading, load is being transferred from the tag axle" 2 "lifting, tag axle is moving up" 3 "up, tag axle is up and stationary" 4 "lowering, tag axle is moving down" 5 "loading, load is being transferred to the tag axle" 6 "error" 7 "not available";
VAL_ 2566767143 fuelType_BASE 0 "none / not available" 1 "Gasoline/petrol" 2 "Methanol" 3 "Ethanol" 4 "Diesel" 5 "Liquefied Petroleum Gas (LPG)" 6 "Compressed Natural Gas (CNG)" 7 "Propane" 8 "Battery/electric" 9 "Bi-fuel vehicle using gasoline" 10 "Bi-fuel vehicle using methanol" 11 "Bi-fuel vehicle using ethanol" 12 "Bi-fuel vehicle using LPG" 13 "Bi-fuel vehicle using CNG" 14 "Bi-fuel vehicle using propane" 15 "Bi-fuel vehicle using battery" 16 "Bi-fuel vehicle using battery and combustion engine" 17 "Hybrid vehicle using gasoline engine" 18 "Hybrid vehicle using gasoline engine on ethanol" 19 "Hybrid vehicle using diesel engine" 20 "Hybrid vehicle using battery" 21 "Hybrid vehicle using battery and combustion engine" 22 "Hybrid vehicle in regeneration mode" 23 "Natural Gas (NG)" 24 "Bi-fuel vehicle using NG" 25 "Bi-fuel using diesel" 26 "Natural Gas (Compressed or Liquefied Natural Gas)" 27 "Dual Fuel ¿ Diesel and CNG" 28 "Dual Fuel ¿ Diesel and LNG" 254 "error" 255 "not available (parameter not supported)";
VAL_ 2566840592 retarderType_RD 0 "Electric/Magnetic" 1 "Hydraulic" 2 "Cooled Friction" 3 "Compression Release (Engine retarder)" 4 "Exhaust" 14 "other" 15 "not available";
VAL_ 2566840592 retarderLocation_RD 0 "(primary)Engine Compression Release Brake (Engine rpm)" 1 "(primary)Engine Exhaust Brake (Exhaust Pressure)" 2 "(primary) Transmission Input (Engine rpm)" 3 "(secondary) Transmission Output (Engine rpm)" 4 "(secondary) Driveline (Output Shaft rpm)" 5 "Trailer (Vehicle Speed)" 14 "other" 15 "not available";
VAL_ 2566847248 drivelineRetOverheatIndicator_RD 0 "Driveline Retarder Overheat Indicator is off" 1 "Driveline Retarder Overheat Indicator is on continuously" 2 "Driveline Retarder Overheat Indicator is flashing" 3 "Not available";
VAL_ 2600407299 activationStateHVHTES_BASE 0 "HVH off" 1 "HVH on" 2 "error" 3 "not available";
VAL_ 2600407299 activationStateCoolSysTES_BASE 0 "Cooling System off" 1 "Cooling System on" 2 "error" 3 "not available";
VAL_ 2600407300 drvSysActv_BASE 0 "drive system not active" 1 "drive system active" 2 "error" 3 "not available / not installed";
VAL_ 2600407301 rainIntensity_BASE 0 "no rain" 1 "little rain" 2 "normal rain" 3 "heavy rain" 14 "error" 15 "not available";
VAL_ 2600407301 schalterWischintervall_BASIS 0 "off" 1 "on" 2 "error" 3 "not available";
VAL_ 2566866977 rainIntensity_BASE 0 "no rain" 1 "little rain" 2 "normal rain" 3 "heavy rain" 14 "error" 15 "not available";
VAL_ 2566866977 lightSwitchReason_BASE 0 "day" 1 "twilight" 2 "darkness" 4 "precipitation" 8 "tunnel" 16 "underground car park" 32 "high speed" 255 "not available";
VAL_ 2566771850 oprtnKeySwIgnPow_BASE 0 "ignition state is not active" 1 "ignition state is active" 2 "error" 3 "not available";
VAL_ 2583638092 appFrameworkAppState_BASE 0 "not running" 1 "starting" 2 "running" 3 "closing" 4 "error / failure" 5 "unknown";
VAL_ 2600422183 frceAirflushActive_BASE 0 "forced airflush deactive" 1 "forced airflush active" 2 "error" 3 "not available";
VAL_ 2600422183 actPrkHtrProgData_BASE 0 "Programming dataset for park heater active" 1 "Programming dataset for park heater not active" 2 "error" 3 "not available";
VAL_ 2600422183 reqSilentMode_BASE 0 "silent mode not requested" 1 "silent mode requested" 2 "error" 3 "not available";
VAL_ 2600422183 washerPumpFront_BASE 0 "deactivated" 1 "activated" 2 "error" 3 "not available";
VAL_ 2600422183 eco24VshutOffReq_BASE 0 "no shut off request" 1 "shut off request" 2 "error" 3 "not available";
VAL_ 2600422183 mainSwitchShutOffInfo_BASE 0 "not active" 1 "active" 2 "error" 3 "not available";
VAL_ 2600422183 actForceReqAC_BASE 0 "no request forced AC-usage" 1 "request forced AC usage" 2 "error" 3 "not available";
VAL_ 2600422183 infoEmgcyShutOff_BASE 0 "no emergency shut off requested" 1 "emergency shut off requested" 2 "error" 3 "not available";
VAL_ 2600422183 revGearHVAC_BASE 0 "reverse gear not active" 1 "reverse gear active" 2 "error" 3 "not available";
VAL_ 2600422183 eco24VpwrSaveReq_BASE 0 "no eco pwr save" 1 "eco pwr save no charging possible" 2 "eco pwr save comfort small restriction" 3 "eco pwr save comfort restriction" 4 "eco pwr save function restriction" 5 "eco pwr save ICE starting mode" 254 "error" 255 "not available";
VAL_ 2600422183 egyModeHVAC_BASE 0 "ECO-Mode" 1 "Normal Mode" 2 "Boost Mode" 3 "Silent mode" 4 "Waste Energy mode" 5 "Shutdown mode" 254 "Error" 255 "Not available";
VAL_ 2600422183 prkHtrEnabled_BASE 0 "Park heater usage disabled" 1 "Park heater usage enbaled" 2 "error" 3 "not available";
VAL_ 2600422183 drvSysOff_BASE 0 "drive system not off" 1 "drive system off" 2 "error" 3 "not available";
VAL_ 2600422183 wiperMotorFrontStep1_BASE 0 "deactivated" 1 "activated" 2 "error" 3 "not available";
VAL_ 2600422183 wiperMotorFrontStep2_BASE 0 "deactivated" 1 "activated" 2 "error" 3 "not available";
VAL_ 2600422183 stopStartActvnState_BASE 0 "stop-start-mode not active" 1 "stop-start-mode active" 2 "error" 3 "not available";
VAL_ 2600422183 windscreenHeatingDisp_BASE 0 "not requested" 1 "requested" 2 "error" 3 "not available";
VAL_ 2600422183 reqElManual_BASE 0 "electronically manual deactive" 1 "electronically manual active" 2 "error" 3 "not available";
VAL_ 2600460311 rmtTstrInstallMsgHeaderReq_BASE 1025 "RemoteTesterFeatureList_GetJobId" 1028 "RemoteTesterFeatureList_GetTitles" 1031 "RemoteTesterFeatureList_GetText" 1034 "RemoteTesterFeatureList_GetUrl";
VAL_ 2600462375 selectedLanguage_BASE 0 "Arabic" 1 "Bulgarian" 2 "Chinese (Mandarin)" 3 "Danish" 4 "German" 5 "English" 6 "Estonian" 7 "Finnish" 8 "French" 9 "Greek" 10 "Hebrew" 11 "Ukrainian" 12 "Italian" 13 "Corean" 14 "Croatian" 15 "Latvian" 16 "Lithuanian" 17 "Dutch" 18 "Norwegian" 19 "Polish" 20 "Portuguese" 21 "Romanian" 22 "Russian" 23 "Swedish" 24 "Serbian" 25 "Slowakian" 26 "Slowenian" 27 "Spanish" 28 "Czech" 29 "Turkish" 30 "Hungarian" 250 "no action";
VAL_ 2566864167 AAF_MC2TBM 0 "Zuordnung 1" 1 "Zuordnung 2" 2 "Zuordnung 3" 3 "Zuordnung 4" 7 "not available";
VAL_ 2566864167 reihenfolge_MC2TBM 0 "keine Reihenfolge" 1 "Reihenfolge bis 111111";
VAL_ 2566864167 statusDaten_MC2TBM 0 "nächster" 1 "fallig" 2 "überfällig 1 Grad" 3 "überfällig 2 Grad";
VAL_ 2566864167 qualitaetVorhanden_MC2TBM 0 "Qualität vorhanden; Zuordnung 0 gemäß Tabelle" 1 "Qualität vorhanden; Zuordnung 1 gemäß Tabelle" 2 "Qualität vorhanden; Zuordnung 2 gemäß Tabelle" 3 "Qualität vorhanden; Zuordnung 3 gemäß Tabelle" 4 "Qualität vorhanden; Zuordnung 4 gemäß Tabelle" 5 "Qualität vorhanden; Zuordnung 5 gemäß Tabelle" 6 "Qualität vorhanden; Zuordnung 6 gemäß Tabelle" 7 "keine Qualitätsaussage zur Komponente vorhanden";
VAL_ 2566864167 qualitaetEmpfohlen_MC2TBM 0 "Qualität empfohlen; Zuordnung 0 gemäß Tabelle" 1 "Qualität empfohlen; Zuordnung 1 gemäß Tabelle" 2 "Qualität empfohlen; Zuordnung 2 gemäß Tabelle" 3 "Qualität empfohlen; Zuordnung 3 gemäß Tabelle" 4 "Qualität empfohlen; Zuordnung 4 gemäß Tabelle" 5 "Qualität empfohlen; Zuordnung 5 gemäß Tabelle" 6 "Qualität empfohlen; Zuordnung 6 gemäß Tabelle" 7 "keine Qualitätsaussage zur Komponente vorhanden";
VAL_ 2566864167 BWI_MC2TBM 0 "Bestätigung nicht möglich" 1 "Bestätigung möglich";
VAL_ 2566864167 optimierung_MC2TBM 0 "ZWS" 1 "FWS";
VAL_ 2566864167 einheitDaten_MC2TBM 0 "km" 1 "BS" 2 "Datum" 3 "not available";
VAL_ 2566864167 weitereTermine_MC2TBM 0 "nein" 1 "ja";
VAL_ 2566749184 DPFactvRegenerationStatus_BASE 0 "not active" 1 "active" 2 "regeneration needed - automatically initiated active regeneration imminent" 3 "not available";
VAL_ 2566749184 DPFstatus_BASE 0 "Regeneration not needed" 1 "Regeneration needed - lowest level" 2 "Regeneration needed - moderate level" 3 "Regeneration needed - highest level" 7 "not available";
VAL_ 2566749184 DPFactvRgnrtnInhDue2InhSw_BASE 0 "not inhibited" 1 "inhibited" 2 "error" 3 "not available";
VAL_ 2566749184 DPFactvRgnrtnInhDue2PTOActv_BASE 0 "not inhibited" 1 "inhibited" 2 "error" 3 "not available";
VAL_ 2566749184 DPFactvRgnrtnInhDue2LowExhGasTmp 0 "not inhibited" 1 "inhibited" 2 "error" 3 "not available";
VAL_ 2566749184 DPFactvRgnrtnInhDue2SysFaultActv 0 "not inhibited" 1 "inhibited" 2 "error" 3 "not available";
VAL_ 2566749184 DPFactvRgnrtnInhDue2EngNotWarmUp 0 "not inhibited" 1 "inhibited" 2 "error" 3 "not available";
VAL_ 2566749184 exhaustSysHighTempLampCommand_BA 0 "Off" 1 "On - solid" 7 "not available";
VAL_ 2566749184 DPFpassiveRegenerationStatus_BAS 0 "not active" 1 "active" 2 "error" 3 "not available";
VAL_ 2566769953 frontNonoperatorWiperSwitch_BASE 0 "Off" 1 "Low" 2 "Medium" 3 "High" 4 "Delayed 1 (used for the first delay choice when the wiper switch position controls the delay)" 5 "Delayed 2 (used for the second delay choice when the wiper switch position controls the delay)" 6 "Mist (position where external sensor controls wiper rate)" 7 "0111 - 1110 Reserved" 15 "Not available (do not change)";
VAL_ 2566769953 rearWiperSwitch_BASE 0 "Off" 1 "Low" 2 "Medium" 3 "High" 4 "Delayed 1 (used for the first delay choice when the wiper switch position controls the delay)" 5 "Delayed 2 (used for the second delay choice when the wiper switch position controls the delay)" 6 "Mist (position where external sensor controls wiper rate)" 7 "0111 - 1110 Reserved" 15 "Not available (do not change)";
VAL_ 2566769953 frontOperatorWiperSwitch_BASE 0 "Off" 1 "Low" 2 "Medium" 3 "High" 4 "Delayed 1 (used for the first delay choice when the wiper switch position controls the delay)" 5 "Delayed 2 (used for the second delay choice when the wiper switch position controls the delay)" 6 "Mist (position where external sensor controls wiper rate)" 7 "0111 - 1110 Reserved" 15 "Not available (do not change)";
VAL_ 2566769953 frontNonoperatorWasherSwitch_BAS 0 "Off" 1 "Low" 2 "Medium" 3 "High" 4 "100 - 110 Reserved" 7 "Not available (do not change)";
VAL_ 2566769953 frontOperatorWasherSwitch_BASE 0 "Off" 1 "Low" 2 "Medium" 3 "High" 4 "100 - 110 Reserved" 7 "Not available (do not change)";
VAL_ 2566769953 rearWasherFunction_BASE 0 "Off" 1 "Low" 2 "Medium" 3 "High" 4 "100 - 110 Reserved" 7 "Not available (do not change)";
VAL_ 2566837553 alternator1Status_BASIS 0 "Alternator 1 not charging" 1 "Alternator 1 charging" 2 "error" 3 "not available";
VAL_ 2566837553 alternator2Status_BASIS 0 "Alternator 2 not charging" 1 "Alternator 2 charging" 2 "error" 3 "not available";
VAL_ 2566837553 alternator3Status_BASIS 0 "Alternator 3 not charging" 1 "Alternator 3 charging" 2 "error" 3 "not available";
VAL_ 2566837553 alternator4Status_BASIS 0 "Alternator 4 not charging" 1 "Alternator 4 charging" 2 "error" 3 "not available";
VAL_ 2566803180 positionOfDoors_BASIS 0 "at least one door is open" 1 "closing last door" 2 "all doors closed" 3 "0011-1101 not defined" 14 "error" 15 "not available";
VAL_ 2566803180 rampWheelChairLiftPosition_BASIS 0 "inside bus" 1 "outside bus" 2 "error" 3 "not available";
VAL_ 2566803180 status2ofDoors_BASIS 0 "all bus doors are disabled" 1 "at least 1 bus door enabled" 2 "error" 3 "not available";
VAL_ 2600455173 BattPack2ActState_BASE 0 "StdBy" 1 "HV/Drive" 2 "N/A" 3 "ExternalCharging" 4 "ExternalChargingHV" 5 "Error_Batt" 6 "ExternalDCCHargingHV" 7 "Init" 8 "Shutdown" 9 "Afterun" 10 "reserved";
VAL_ 2600455177 BattPack6ActState_BASE 0 "StdBy" 1 "HV/Drive" 2 "N/A" 3 "ExternalCharging" 4 "ExternalChargingHV" 5 "Error_Batt" 6 "ExternalDCCHargingHV" 7 "Init" 8 "Shutdown" 9 "Afterun" 10 "reserved";
VAL_ 2600455172 BattPack1ActState_BASE 0 "StdBy" 1 "HV/Drive" 2 "N/A" 3 "ExternalCharging" 4 "ExternalChargingHV" 5 "Error_Batt" 6 "ExternalDCCHargingHV" 7 "Init" 8 "Shutdown" 9 "Afterun" 10 "reserved";
VAL_ 2600455179 BattPack8ActState_BASE 0 "StdBy" 1 "HV/Drive" 2 "N/A" 3 "ExternalCharging" 4 "ExternalChargingHV" 5 "Error_Batt" 6 "ExternalDCCHargingHV" 7 "Init" 8 "Shutdown" 9 "Afterun" 10 "reserved";
VAL_ 2600455178 BattPack7ActState_BASE 0 "StdBy" 1 "HV/Drive" 2 "N/A" 3 "ExternalCharging" 4 "ExternalChargingHV" 5 "Error_Batt" 6 "ExternalDCCHargingHV" 7 "Init" 8 "Shutdown" 9 "Afterun" 10 "reserved";
VAL_ 2600455176 BattPack5ActState_BASE 0 "StdBy" 1 "HV/Drive" 2 "N/A" 3 "ExternalCharging" 4 "ExternalChargingHV" 5 "Error_Batt" 6 "ExternalDCCHargingHV" 7 "Init" 8 "Shutdown" 9 "Afterun" 10 "reserved";
VAL_ 2600455171 stateMultiTES_BASE 0 "0 TES connected, 0 TES not in error mode" 1 "0 TES connected, 1 TES not in error mode" 2 "0 TES connected, 2 TES not in error mode" 3 "0 TES connected, 3 TES not in error mode" 4 "0 TES connected, 4 TES not in error mode" 5 "0 TES connected, 5 TES not in error mode" 6 "0 TES connected, 6 TES not in error mode" 7 "0 TES connected, 7 TES not in error mode" 8 "0 TES connected, 8 TES not in error mode" 17 "1 TES connected, 1 TES not in error mode" 18 "1 TES connected, 2 TES not in error mode" 19 "1 TES connected, 3 TES not in error mode" 20 "1 TES connected, 4 TES not in error mode" 21 "1 TES connected, 5 TES not in error mode" 22 "1 TES connected, 6 TES not in error mode" 23 "1 TES connected, 7 TES not in error mode" 24 "1 TES connected, 8 TES not in error mode" 34 "2 TES connected, 2 TES not in error mode" 35 "2 TES connected, 3 TES not in error mode" 36 "2 TES connected, 4 TES not in error mode" 37 "2 TES connected, 5 TES not in error mode" 38 "2 TES connected, 6 TES not in error mode" 39 "2 TES connected, 7 TES not in error mode" 40 "2 TES connected, 8 TES not in error mode" 51 "3 TES connected, 3 TES not in error mode" 52 "3 TES connected, 4 TES not in error mode" 53 "3 TES connected, 5 TES not in error mode" 54 "3 TES connected, 6 TES not in error mode" 55 "3 TES connected, 7 TES not in error mode" 56 "3 TES connected, 8 TES not in error mode" 68 "4 TES connected, 4 TES not in error mode" 69 "4 TES connected, 5 TES not in error mode" 70 "4 TES connected, 6 TES not in error mode" 71 "4 TES connected, 7 TES not in error mode" 72 "4 TES connected, 8 TES not in error mode" 85 "5 TES connected, 5 TES not in error mode" 86 "5 TES connected, 6 TES not in error mode" 87 "5 TES connected, 7 TES not in error mode" 88 "5 TES connected, 8 TES not in error mode" 102 "6 TES connected, 6 TES not in error mode" 103 "6 TES connected, 7 TES not in error mode" 104 "6 TES connected, 8 TES not in error mode" 119 "7 TES connected, 7 TES not in error mode" 120 "7 TES connected, 8 TES not in error mode" 136 "8 TES connected, 8 TES not in error mode";
VAL_ 2600455175 BattPack4ActState_BASE 0 "StdBy" 1 "HV/Drive" 2 "N/A" 3 "ExternalCharging" 4 "ExternalChargingHV" 5 "Error_Batt" 6 "ExternalDCCHargingHV" 7 "Init" 8 "Shutdown" 9 "Afterun" 10 "reserved";
VAL_ 2600455174 BattPack3ActState_BASE 0 "StdBy" 1 "HV/Drive" 2 "N/A" 3 "ExternalCharging" 4 "ExternalChargingHV" 5 "Error_Batt" 6 "ExternalDCCHargingHV" 7 "Init" 8 "Shutdown" 9 "Afterun" 10 "reserved";
